VERSION "Version"

NS_ :

BS_:

BU_: IID IDC CCU Tester CCURT1 CCURT2 CCU3 CCU4 AVAS LCUFL LCUFR LCURL LCURR ZCUF ZCUL ZCUR ZCUT PADS MFS VDC ITS BCB IPS DCDC PCU EOP DCU BMC SRS EPS RBM IBCS AMP WHUD ADC RADARRR RADARRL RADARFR RADARFL RPC IFC RADARFRT RADARR HDMAP SBM WCM ETC TBOX DSM FLPDM FRPDM RLPDM RRPDM

BO_ 475 IDC_4: 64 IDC
 SG_ IDC_4_Dummy7 : 31|30@0+ (1,0) [0|0] ""  CCU,CCURT2
 SG_ IDC_4_Dummy6 : 64|25@0+ (1,0) [0|0] ""  CCU,CCURT2
 SG_ IDC_4_Dummy5 : 101|22@0+ (1,0) [0|0] ""  CCU,CCURT2
 SG_ IDC_4_Dummy4 : 127|64@0+ (1,0) [0|0] ""  CCU,CCURT2
 SG_ IDC_4_Dummy3 : 303|48@0+ (1,0) [0|0] ""  CCU,CCURT2
 SG_ IDC_4_Dummy2 : 415|38@0+ (1,0) [0|0] ""  CCU,CCURT2
 SG_ IDC_4_Dummy1 : 455|64@0+ (1,0) [0|0] ""  CCU,CCURT2
 SG_ Reserved1 : 441|2@0+ (1,0) [0|3] ""  CCU,CCURT2
 SG_ ACU_FRSeatOttomanExtentPosCtlReq : 295|8@0+ (0.5,0) [0|255] ""  CCU,CCURT2
 SG_ ACU_FRSeatOttomanAnglePosCtlReq : 287|8@0+ (0.5,0) [0|255] ""  CCU,CCURT2
 SG_ ACU_FLSeatOttomanExtentPosCtlReq : 279|8@0+ (0.5,0) [0|255] ""  CCU,CCURT2
 SG_ ACU_FLSeatOttomanAnglePosCtlReq : 271|8@0+ (0.5,0) [0|255] ""  CCU,CCURT2
 SG_ IDC_4_Counter : 23|8@0+ (1,0) [0|255] ""  CCU,CCURT2
 SG_ IDC_4_CRC : 7|16@0+ (1,0) [0|65535] ""  CCU,CCURT2
 SG_ ACU_HVACFR_OffOnBtnSt : 49|1@0+ (1,0) [0|1] ""  CCU,CCURT2
 SG_ ACU_HVACFR_AutoModeBtnSt : 48|1@0+ (1,0) [0|1] ""  CCU,CCURT2
 SG_ ACU_HVACFR_ModeBtnSt : 63|1@0+ (1,0) [0|1] ""  CCU,CCURT2
 SG_ ACU_HVACF_FDefrostBtnSt : 62|1@0+ (1,0) [0|1] ""  CCU,CCURT2
 SG_ ACU_HVACF_RDefrostBtnSt : 61|1@0+ (1,0) [0|1] ""  CCU,CCURT2
 SG_ ACU_HVACF_DualSyncBtnSt : 60|1@0+ (1,0) [0|1] ""  CCU,CCURT2
 SG_ ACU_HVACF_IonBtnSt : 59|1@0+ (1,0) [0|1] ""  CCU,CCURT2
 SG_ ACU_HVACFR_FanIncBtnSt : 58|1@0+ (1,0) [0|1] ""  CCU,CCURT2
 SG_ ACU_HVACFR_FanDecBtnSt : 57|1@0+ (1,0) [0|1] ""  CCU,CCURT2
 SG_ ACU_HVACF_CirBtnSt : 56|1@0+ (1,0) [0|1] ""  CCU,CCURT2
 SG_ ACU_HVACF_ACBtnSt : 71|1@0+ (1,0) [0|1] ""  CCU,CCURT2
 SG_ ACU_HVACF_ACMaxBtnSt : 70|1@0+ (1,0) [0|1] ""  CCU,CCURT2
 SG_ ACU_HVACF_FLTempIncBtnSt : 69|1@0+ (1,0) [0|1] ""  CCU,CCURT2
 SG_ ACU_HVACF_FLTempDecBtnSt : 68|1@0+ (1,0) [0|1] ""  CCU,CCURT2
 SG_ ACU_HVACF_FRTempIncBtnSt : 67|1@0+ (1,0) [0|1] ""  CCU,CCURT2
 SG_ ACU_HVACF_FRTempDecBtnSt : 66|1@0+ (1,0) [0|1] ""  CCU,CCURT2
 SG_ ACU_HVACF_ECOBtnSt : 65|1@0+ (1,0) [0|1] ""  CCU,CCURT2
 SG_ ACU_HVAC_RearOnOffBtnSt : 103|1@0+ (1,0) [0|1] ""  CCU,CCURT2
 SG_ ACU_HVAC_RearAutoModeBtnSt : 102|1@0+ (1,0) [0|1] ""  CCU,CCURT2
 SG_ ACU_LeftMirrorXPosCtlReq : 191|8@0+ (1,0) [0|255] "%"  CCU,CCURT2,ZCUL
 SG_ ACU_LeftMirrorYPosCtlReq : 199|8@0+ (1,0) [0|255] "%"  CCU,CCURT2,ZCUL
 SG_ ACU_RightMirrorXPosCtlReq : 207|8@0+ (1,0) [0|255] "%"  CCU,CCURT2,ZCUL
 SG_ ACU_RightMirrorYPosCtlReq : 215|8@0+ (1,0) [0|255] "%"  CCU,CCURT2,ZCUL
 SG_ ACU_FLSeatSlidePosCtlReq : 223|8@0+ (0.5,0) [0|255] ""  CCU,CCURT2
 SG_ ACU_FLSeatHeightPosCtlReq : 231|8@0+ (0.5,0) [0|255] ""  CCU,CCURT2
 SG_ ACU_FLSeatBackrestPosCtlReq : 239|8@0+ (0.5,0) [0|255] ""  CCU,CCURT2
 SG_ ACU_FLSeatTiltPosCtlReq : 247|8@0+ (0.5,0) [0|255] ""  CCU,CCURT2
 SG_ ACU_SteeringAnglePosCtlReq : 255|8@0+ (0.5,0) [0|255] ""  CCU,CCURT2,ZCUL
 SG_ ACU_SteeringExtentPosCtlReq : 263|8@0+ (0.5,0) [0|255] ""  CCU,CCURT2,ZCUL
 SG_ ACU_FRSeatSlidePosCtlReq : 351|8@0+ (0.5,0) [0|255] ""  CCU,CCURT2
 SG_ ACU_FRSeatHeightPosCtlReq : 359|8@0+ (0.5,0) [0|255] ""  CCU,CCURT2
 SG_ ACU_FRSeatBackrestPosCtlReq : 367|8@0+ (0.5,0) [0|255] ""  CCU,CCURT2
 SG_ ACU_FRSeatTiltPosCtlReq : 375|8@0+ (0.5,0) [0|255] ""  CCU,CCURT2
 SG_ ACU_FLSeatCushionPosCtlReq : 383|8@0+ (0.5,0) [0|255] ""  CCU,CCURT2
 SG_ ACU_FRSeatCushionPosCtlReq : 391|8@0+ (0.5,0) [0|255] ""  CCU,CCURT2
 SG_ ACU_FLSeatOttomanPosCtlReq : 399|8@0+ (0.5,0) [0|255] ""  CCU,CCURT2
 SG_ ACU_FRSeatOttomanPosCtlReq : 407|8@0+ (0.5,0) [0|255] ""  CCU,CCURT2

BO_ 967 IDC_DMS_1: 64 IDC
 SG_ IDC_DMS_1_Dummy13 : 264|4@0+ (1,0) [0|15] "" Vector__XXX
 SG_ IDC_DMS_1_Dummy12 : 63|3@0+ (1,0) [0|7] ""  CCU
 SG_ DMS_YawnSt : 276|2@0+ (1,0) [0|3] ""  ADC,CCU
 SG_ IDC_DMS_1_Dummy11 : 137|2@0+ (1,0) [0|3] ""  CCU
 SG_ IDC_DMS_1_Dummy10 : 25|2@0+ (1,0) [0|0] ""  CCU
 SG_ IDC_DMS_1_Dummy9 : 34|1@0+ (1,0) [0|0] ""  CCU
 SG_ DMS_FaceID : 58|4@0+ (1,0) [0|15] ""  CCU
 SG_ IDC_DMS_1_Dummy6 : 128|1@0+ (1,0) [0|0] ""  CCU
 SG_ IDC_DMS_1_Dummy5 : 188|1@0+ (1,0) [0|0] ""  CCU
 SG_ IDC_DMS_1_Dummy4 : 274|43@0+ (1,0) [0|8796093022207] ""  CCU
 SG_ IDC_DMS_1_Dummy3 : 327|64@0+ (1,0) [0|0] ""  CCU
 SG_ IDC_DMS_1_Dummy2 : 391|64@0+ (1,0) [0|0] ""  CCU
 SG_ IDC_DMS_1_Dummy1 : 455|64@0+ (1,0) [0|0] ""  CCU
 SG_ DMS_SeatBeltRigntrearStatus : 269|1@0+ (1,0) [0|1] ""  CCU
 SG_ DMS_SeatBeltMidrearStatus : 270|1@0+ (1,0) [0|1] ""  CCU
 SG_ DMS_SeatBeltLeftrearStatus : 271|1@0+ (1,0) [0|1] ""  CCU
 SG_ DMS_SeatBeltCodriverStatus : 256|1@0+ (1,0) [0|1] ""  CCU
 SG_ DMS_SeatBeltDriverStatus : 257|1@0+ (1,0) [0|1] ""  CCU
 SG_ DMS_MidrearChild : 258|1@0+ (1,0) [0|1] ""  CCU
 SG_ DMS_RigntrearChild : 259|1@0+ (1,0) [0|1] ""  CCU
 SG_ DMS_LeftrearChild : 260|1@0+ (1,0) [0|1] ""  CCU
 SG_ DMS_CodriverChild : 261|1@0+ (1,0) [0|1] ""  CCU
 SG_ DMS_MidrearThumbleftgestures : 262|1@0+ (1,0) [0|1] ""  CCU
 SG_ DMS_RigntrearThumbleftgestures : 263|1@0+ (1,0) [0|1] ""  CCU
 SG_ DMS_LeftrearThumbleftgestures : 248|1@0+ (1,0) [0|1] ""  CCU
 SG_ DMS_CodriverThumbleftgestures : 249|1@0+ (1,0) [0|1] ""  CCU
 SG_ DMS_DriverThumbleftgestures : 250|1@0+ (1,0) [0|1] ""  CCU
 SG_ DMS_MidrearThumbrightgestures : 251|1@0+ (1,0) [0|1] ""  CCU
 SG_ DMS_RigntrearThumbrightgestures : 252|1@0+ (1,0) [0|1] ""  CCU
 SG_ DMS_LeftrearThumbrightgestures : 253|1@0+ (1,0) [0|1] ""  CCU
 SG_ DMS_CodriverThumbrightgestures : 254|1@0+ (1,0) [0|1] ""  CCU
 SG_ DMS_DriverThumbrightgestures : 255|1@0+ (1,0) [0|1] ""  CCU
 SG_ DMS_MidrearThumbdowngestures : 240|1@0+ (1,0) [0|1] ""  CCU
 SG_ DMS_RigntrearThumbdowngestures : 241|1@0+ (1,0) [0|1] ""  CCU
 SG_ DMS_LeftrearThumbdowngestures : 242|1@0+ (1,0) [0|1] ""  CCU
 SG_ DMS_CodriverThumbdowngestures : 243|1@0+ (1,0) [0|1] ""  CCU
 SG_ DMS_DriverThumbdowngestures : 244|1@0+ (1,0) [0|1] ""  CCU
 SG_ DMS_MidrearThumbupgestures : 245|1@0+ (1,0) [0|1] ""  CCU
 SG_ DMS_RigntrearThumbupgestures : 246|1@0+ (1,0) [0|1] ""  CCU
 SG_ DMS_LeftrearThumbupgestures : 247|1@0+ (1,0) [0|1] ""  CCU
 SG_ DMS_CodriverThumbupgestures : 232|1@0+ (1,0) [0|1] ""  CCU
 SG_ DMS_DriverThumbupgestures : 233|1@0+ (1,0) [0|1] ""  CCU
 SG_ DMS_MidrearPapergesture : 234|1@0+ (1,0) [0|1] ""  CCU
 SG_ DMS_RigntrearPapergesture : 235|1@0+ (1,0) [0|1] ""  CCU
 SG_ DMS_LeftrearPapergesture : 236|1@0+ (1,0) [0|1] ""  CCU
 SG_ DMS_CodriverPapergesture : 237|1@0+ (1,0) [0|1] ""  CCU
 SG_ DMS_DriverPapergesture : 238|1@0+ (1,0) [0|1] ""  CCU
 SG_ DMS_MidrearScissorsgesture : 239|1@0+ (1,0) [0|1] ""  CCU
 SG_ DMS_RigntrearScissorsgesture : 224|1@0+ (1,0) [0|1] ""  CCU
 SG_ DMS_LeftrearScissorsgesture : 225|1@0+ (1,0) [0|1] ""  CCU
 SG_ DMS_CodriverScissorsgesture : 226|1@0+ (1,0) [0|1] ""  CCU
 SG_ DMS_DriverScissorsgesture : 227|1@0+ (1,0) [0|1] ""  CCU
 SG_ DMS_MidrearRockgesture : 228|1@0+ (1,0) [0|1] ""  CCU
 SG_ DMS_RigntrearRockgesture : 229|1@0+ (1,0) [0|1] ""  CCU
 SG_ DMS_LeftrearRockgesture : 230|1@0+ (1,0) [0|1] ""  CCU
 SG_ DMS_CodriverRockgesture : 231|1@0+ (1,0) [0|1] ""  CCU
 SG_ DMS_DriverRockgesture : 216|1@0+ (1,0) [0|1] ""  CCU
 SG_ DMS_MidrearWavepalmtotheleft : 217|1@0+ (1,0) [0|1] ""  CCU
 SG_ DMS_RigntrearWavepalmtotheleft : 218|1@0+ (1,0) [0|1] ""  CCU
 SG_ DMS_LeftrearWavepalmtotheleft : 219|1@0+ (1,0) [0|1] ""  CCU
 SG_ DMS_CodriverWavepalmtotheleft : 220|1@0+ (1,0) [0|1] ""  CCU
 SG_ DMS_DriverWavepalmtotheleft : 221|1@0+ (1,0) [0|1] ""  CCU
 SG_ DMS_MidrearWavepalmtotheright : 222|1@0+ (1,0) [0|1] ""  CCU
 SG_ DMS_RigntrearWavepalmtotheright : 223|1@0+ (1,0) [0|1] ""  CCU
 SG_ DMS_LeftrearWavepalmtotheright : 208|1@0+ (1,0) [0|1] ""  CCU
 SG_ DMS_CodriverWavepalmtotheright : 209|1@0+ (1,0) [0|1] ""  CCU
 SG_ DMS_DriverWavepalmtotheright : 210|1@0+ (1,0) [0|1] ""  CCU
 SG_ DMS_MidrearDownwardwave : 211|1@0+ (1,0) [0|1] ""  CCU
 SG_ DMS_RigntrearDownwardwave : 212|1@0+ (1,0) [0|1] ""  CCU
 SG_ DMS_LeftrearDownwardwave : 213|1@0+ (1,0) [0|1] ""  CCU
 SG_ DMS_CodriverDownwardwave : 214|1@0+ (1,0) [0|1] ""  CCU
 SG_ DMS_DriverDownwardwave : 215|1@0+ (1,0) [0|1] ""  CCU
 SG_ DMS_MidrearUpwardwave : 200|1@0+ (1,0) [0|1] ""  CCU
 SG_ DMS_RigntrearUpwardwave : 201|1@0+ (1,0) [0|1] ""  CCU
 SG_ DMS_LeftrearUpwardwave : 202|1@0+ (1,0) [0|1] ""  CCU
 SG_ DMS_CodriverUpwardwave : 203|1@0+ (1,0) [0|1] ""  CCU
 SG_ DMS_DriverUpwardwave : 204|1@0+ (1,0) [0|1] ""  CCU
 SG_ DMS_MidrearForefingercircleleft : 205|1@0+ (1,0) [0|1] ""  CCU
 SG_ DMS_RigntrearForefingercirclelef : 206|1@0+ (1,0) [0|1] ""  CCU
 SG_ DMS_LeftrearForefingercircleleft : 207|1@0+ (1,0) [0|1] ""  CCU
 SG_ DMS_CodriverForefingercircleleft : 192|1@0+ (1,0) [0|1] ""  CCU
 SG_ DMS_DriverForefingercircleleft : 193|1@0+ (1,0) [0|1] ""  CCU
 SG_ DMS_MidrearForefingercircleright : 194|1@0+ (1,0) [0|1] ""  CCU
 SG_ DMS_RigntrearForefingercirclerig : 195|1@0+ (1,0) [0|1] ""  CCU
 SG_ DMS_LeftrearForefingercirclerigh : 196|1@0+ (1,0) [0|1] ""  CCU
 SG_ DMS_CodriverForefingercirclerigh : 197|1@0+ (1,0) [0|1] ""  CCU
 SG_ DMS_DriverForefingercircleright : 198|1@0+ (1,0) [0|1] ""  CCU
 SG_ DMS_MidrearOKgesture : 199|1@0+ (1,0) [0|1] ""  CCU
 SG_ DMS_RigntrearOKgesture : 184|1@0+ (1,0) [0|1] ""  CCU
 SG_ DMS_LeftrearOKgesture : 185|1@0+ (1,0) [0|1] ""  CCU
 SG_ DMS_CodriverOKgesture : 186|1@0+ (1,0) [0|1] ""  CCU
 SG_ DMS_DriverOKgesture : 187|1@0+ (1,0) [0|1] ""  CCU
 SG_ DMS_MidrearHandheartgesture : 189|1@0+ (1,0) [0|1] ""  CCU
 SG_ DMS_RigntrearHandheartgesture : 190|1@0+ (1,0) [0|1] ""  CCU
 SG_ DMS_LeftrearHandheartgesture : 191|1@0+ (1,0) [0|1] ""  CCU
 SG_ DMS_CodriverHandheartgesture : 176|1@0+ (1,0) [0|1] ""  CCU
 SG_ DMS_DriverHandheartgesture : 177|1@0+ (1,0) [0|1] ""  CCU
 SG_ DMS_CarOwner : 178|1@0+ (1,0) [0|1] ""  CCU
 SG_ DMS_PersonGender : 180|2@0+ (1,0) [0|3] ""  CCU
 SG_ DMS_SeatMidrearSt : 181|1@0+ (1,0) [0|1] ""  CCU
 SG_ DMS_SeatRigntrearSt : 182|1@0+ (1,0) [0|1] ""  CCU
 SG_ DMS_SeatLeftrearSt : 183|1@0+ (1,0) [0|1] ""  CCU
 SG_ DMS_PersonAge : 175|8@0+ (0.392,0) [0|99] ""  CCU
 SG_ DMS_SeatMidmiddleSt : 160|1@0+ (1,0) [0|1] ""  CCU
 SG_ DMS_SeatCodriverSt : 161|1@0+ (1,0) [0|1] ""  CCU
 SG_ DMS_PersonCount : 165|4@0+ (1,0) [0|7] ""  CCU
 SG_ DMS_DriverDistractionSt : 167|2@0+ (1,0) [0|3] ""  CCU
 SG_ DMS_SeatDriverSt : 152|1@0+ (1,0) [0|1] ""  CCU
 SG_ DMS_DriverInterestsRegion : 156|4@0+ (1,0) [0|15] ""  CCU
 SG_ DMS_DriverFatigueSt : 159|3@0+ (1,0) [0|3] ""  CCU
 SG_ DMS_FaceIDFailCause : 146|3@0+ (1,0) [0|7] ""  CCU
 SG_ DMS_FaceIDWelcomeMode : 147|1@0+ (1,0) [0|1] ""  CCU
 SG_ DMS_DriverFaceID : 151|4@0+ (1,0) [0|15] ""  CCU
 SG_ DMS_MidrearHealthSt : 140|3@0+ (1,0) [0|7] ""  CCU
 SG_ DMS_RigntrearHealthSt : 143|3@0+ (1,0) [0|7] ""  CCU
 SG_ DMS_LeftrearHealthSt : 131|3@0+ (1,0) [0|7] ""  CCU
 SG_ DMS_CodriverHealthSt : 134|3@0+ (1,0) [0|7] ""  CCU
 SG_ DMS_SeatPositionID : 121|3@0+ (1,0) [0|3] ""  CCU
 SG_ DMS_MidrearTelephoneSt : 123|2@0+ (1,0) [0|3] ""  CCU
 SG_ DMS_RigntrearTelephoneSt : 125|2@0+ (1,0) [0|3] ""  CCU
 SG_ DMS_LeftrearTelephoneSt : 127|2@0+ (1,0) [0|3] ""  CCU
 SG_ DMS_CodriverTelephoneSt : 113|2@0+ (1,0) [0|3] ""  CCU
 SG_ DMS_MidrearSmokeSt : 115|2@0+ (1,0) [0|3] ""  CCU
 SG_ DMS_RigntrearSmokeSt : 117|2@0+ (1,0) [0|3] ""  CCU
 SG_ DMS_LeftrearSmokeSt : 119|2@0+ (1,0) [0|3] ""  CCU
 SG_ DMS_MidrearExpressionSt : 107|4@0+ (1,0) [0|15] ""  CCU
 SG_ DMS_RigntrearExpressionSt : 111|4@0+ (1,0) [0|15] ""  CCU
 SG_ DMS_LeftrearExpressionSt : 99|4@0+ (1,0) [0|15] ""  CCU
 SG_ DMS_CodriverExpressionSt : 103|4@0+ (1,0) [0|15] ""  CCU
 SG_ DMS_CodriverSmokeSt : 89|2@0+ (1,0) [0|3] ""  CCU
 SG_ DMS_ObjectSt : 90|1@0+ (1,0) [0|1] ""  CCU
 SG_ DMS_PetSt : 91|1@0+ (1,0) [0|1] ""  CCU
 SG_ DMS_DistrWarnSt : 94|3@0+ (1,0) [0|7] ""  CCU
 SG_ DMS_FatigWarnSt : 81|3@0+ (1,0) [0|7] ""  CCU
 SG_ DMS_SeatLeftmiddleSt : 82|1@0+ (1,0) [0|1] ""  CCU
 SG_ DMS_SeatRightmiddleSt : 83|1@0+ (1,0) [0|1] ""  CCU
 SG_ DMS_DriverHealthSt : 86|3@0+ (1,0) [0|7] ""  CCU
 SG_ DMS_DriverTelephoneSt : 72|2@0+ (1,0) [0|3] ""  CCU
 SG_ DMS_DriverSmokeSt : 74|2@0+ (1,0) [0|3] ""  CCU
 SG_ DMS_GlassWearSt : 75|1@0+ (1,0) [0|1] ""  CCU
 SG_ DMS_MouthSt : 76|1@0+ (1,0) [0|1] ""  CCU
 SG_ DMS_RightEyeOpenSt : 78|2@0+ (1,0) [0|3] ""  CCU
 SG_ DMS_LeftEyeOpenSt : 64|2@0+ (1,0) [0|3] ""  CCU
 SG_ DMS_FaceIDDeleteResult : 66|2@0+ (1,0) [0|3] ""  CCU
 SG_ DMS_FaceIDVerifyResult : 68|2@0+ (1,0) [0|3] ""  CCU
 SG_ DMS_FaceIDRegisterResult : 70|2@0+ (1,0) [0|3] ""  CCU
 SG_ DMS_FaceIDStatus : 60|2@0+ (1,0) [0|3] ""  CCU
 SG_ DMS_DriverExpressionSt : 268|4@0+ (1,0) [0|15] ""  CCU
 SG_ DMS_1_Checksum : 7|16@0+ (1,0) [0|65535] ""  CCU,ADC
 SG_ DMS_1_MsgCounter : 23|8@0+ (1,0) [0|255] ""  CCU,ADC
 SG_ DMS_SysErrSt : 31|3@0+ (1,0) [0|7] ""  CCU,ADC
 SG_ DMS_DrvrDetSts : 28|3@0+ (1,0) [0|7] ""  CCU,ADC
 SG_ DMS_InterestsRegion : 39|5@0+ (1,0) [0|31] ""  CCU,ADC
 SG_ DMS_L3DriverDistractionSt : 33|6@0+ (1,0) [0|63] ""  CCU,ADC
 SG_ DMS_L3DriverFatigueSt : 43|12@0+ (1,0) [0|4095] ""  CCU,ADC

BO_ 1963 IDC_Diag_Tx: 64 IDC
 SG_ IDC_Diag_Response : 7|64@0+ (1,0) [0|0] ""  Tester

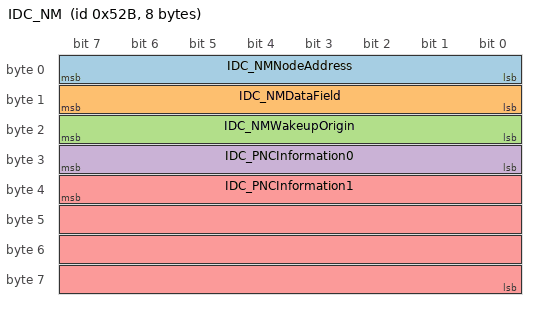
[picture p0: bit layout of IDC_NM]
BO_ 1323 IDC_NM: 8 IDC
 SG_ IDC_NMNodeAddress : 7|8@0+ (1,0) [0|255] ""  CCU,CCURT2
 SG_ IDC_NMDataField : 15|8@0+ (1,0) [0|0] ""  CCU,CCURT2
 SG_ IDC_NMWakeupOrigin : 23|8@0+ (1,0) [0|255] ""  CCU,CCURT2
 SG_ IDC_PNCInformation0 : 31|8@0+ (1,0) [0|255] ""  CCU,CCURT2
 SG_ IDC_PNCInformation1 : 39|32@0+ (1,0) [0|0] ""  CCU,CCURT2

BO_ 169 IDC_SecReq: 16 IDC
 SG_ IDC_SecReq : 7|128@0+ (1,0) [0|255] ""  CCU

BO_ 157 IDC_IMMO: 1 IDC
 SG_ IDC_IMMO : 7|8@0+ (1,0) [0|255] "" Vector__XXX

BO_ 122 IDC_SECKEY: 1 IDC
 SG_ IDC_SEC_KEY_Defaultencoding : 7|8@0+ (1,0) [0|255] ""  CCU,CCURT1

BO_ 624 CCU_ZCUR_1: 64 CCU
 SG_ KAE_KeyReminderWarning : 40|1@0+ (1,0) [0|1] ""  IDC
 SG_ KAE_DoorLockWarning : 55|2@0+ (1,0) [0|3] ""  IDC
 SG_ KAE_StartAuthFailWarning : 53|1@0+ (1,0) [0|1] ""  IDC
 SG_ KAE_KeyBattaryLowWarning : 52|1@0+ (1,0) [0|1] ""  IDC
 SG_ KAE_IDOutWarning : 50|1@0+ (1,0) [0|1] ""  IDC
 SG_ ZCUR_1_FreshnessValue : 455|16@0+ (1,0) [0|255] ""  IDC
 SG_ ZCUR_1_MAC_Check : 471|48@0+ (1,0) [0|255] ""  IDC

BO_ 777 CCU_ZCUR_4: 64 CCU
 SG_ SSW_FROttomanExtentCurrentOpeSt : 443|2@0+ (1,0) [0|3] ""  IDC
 SG_ SSW_FROttomanExtentCurrentPst : 435|8@0+ (0.5,0) [0|100] ""  IDC
 SG_ SSW_FROttomanAngleCurrentOpeSt : 437|2@0+ (1,0) [0|3] ""  IDC
 SG_ SSW_FROttomanAngleCurrentPst : 429|8@0+ (0.5,0) [0|100] ""  IDC
 SG_ SSW_FRSeatSlideCurrentPst : 87|8@0+ (0.5,0) [0|100] ""  IDC
 SG_ SSW_FRSeatHeightCurrentPst : 95|8@0+ (0.5,0) [0|100] ""  IDC
 SG_ SSW_FRSeatBackrestCurrentPst : 151|8@0+ (0.5,0) [0|100] ""  IDC
 SG_ SSW_FRSeatTiltCurrentPst : 175|8@0+ (0.5,0) [0|100] ""  IDC
 SG_ SSW_FRSeatCushionCurrentPst : 183|8@0+ (0.5,0) [0|100] ""  IDC
 SG_ SSW_FRSeatOttomanCurrentPst : 191|8@0+ (0.5,0) [0|100] ""  IDC
 SG_ SSW_FRSeatHeatingSt : 167|3@0+ (1,0) [0|7] ""  IDC
 SG_ SSW_FRSeatVentSt : 164|3@0+ (1,0) [0|7] ""  IDC
 SG_ EL_MRTurnLightSt : 325|2@0+ (1,0) [0|3] ""  SRS,IDC,TBOX
 SG_ EL_MRTurnLightFaultSt : 323|1@0+ (1,0) [0|1] ""  SRS,IDC,ADC

BO_ 786 CCU_ZCUR_7: 64 CCU
 SG_ SSW_FRMassageForceSt : 7|4@0+ (1,0) [0|15] "" Vector__XXX
 SG_ SSW_FRMassageModeSt : 439|4@0+ (1,0) [0|15] ""  IDC
 SG_ SSW_FRSPAMode : 425|2@0+ (1,0) [0|3] ""  IDC
 SG_ SSW_FRLumbarModeSt : 428|3@0+ (1,0) [0|7] ""  IDC
 SG_ SSW_FRMassageSt : 430|2@0+ (1,0) [0|3] ""  IDC
 SG_ AQM_CO2DataVD : 423|1@0+ (1,0) [0|1] ""  IDC
 SG_ AQM_CO2Data : 407|16@0+ (1,0) [0|65535] ""  IDC
 SG_ AQM_PM25Data : 215|10@0+ (1,0) [0|999] "ug/m3"  IDC
 SG_ AQM_PM10Data : 221|10@0+ (1,0) [0|999] "ug/m3"  IDC
 SG_ AQM_PM25DataVD : 232|1@0+ (1,0) [0|1] ""  IDC
 SG_ AQM_PM10DataVD : 247|1@0+ (1,0) [0|1] ""  IDC
 SG_ AQM_PM25ValueOutVD : 290|1@0+ (1,0) [0|1] ""  IDC
 SG_ AQM_PM25ValueOut : 289|10@0+ (1,0) [0|999] "Î¼g/mÂ³"  IDC

BO_ 342 CCU_ZCUR_8: 64 CCU
 SG_ KAE_KUID : 83|4@0+ (1,0) [0|15] ""  IDC
 SG_ KAE_RKEChargeGunUnlockReq : 103|1@0+ (1,0) [0|1] ""  IDC

BO_ 632 CCU_ZCUL_2: 64 CCU
 SG_ SSW_FLLumbarOpeSt : 139|3@0+ (1,0) [0|7] ""  IDC
 SG_ SSW_FLOttomanExtentCurrentOpeSt : 373|2@0+ (1,0) [0|3] ""  IDC
 SG_ SSW_FLOttomanExtentCurrentPst : 365|8@0+ (0.5,0) [0|100] ""  IDC
 SG_ SSW_FLOttomanAngleCurrentOpeSt : 367|2@0+ (1,0) [0|3] ""  IDC
 SG_ SSW_FLOttomanAngleCurrentPst : 359|8@0+ (0.5,0) [0|100] ""  IDC
 SG_ SSW_FLSeatVentSt : 164|3@0+ (1,0) [0|7] ""  ZCUR,IDC,SBM
 SG_ SSW_FLSeatHeatingSt : 167|3@0+ (1,0) [0|7] ""  ZCUR,IDC,SBM
 SG_ SSW_FLSeatSlideCurrentPst : 47|8@0+ (0.5,0) [0|100] "%"  IDC
 SG_ SSW_FLSeatHeightCurrentPst : 55|8@0+ (0.5,0) [0|100] "%"  IDC
 SG_ SSW_FLSeatBackrestCurrentPst : 63|8@0+ (0.5,0) [0|100] "%"  IDC
 SG_ SSW_FLSeatTiltCurrentPst : 79|8@0+ (0.5,0) [0|100] "%"  IDC
 SG_ SSW_SteeringAngleCurrentPst : 87|8@0+ (0.5,0) [0|100] "%"  IDC
 SG_ SSW_SteeringExtentCurrentPst : 95|8@0+ (0.5,0) [0|100] "%"  IDC
 SG_ SSW_FLSeatCushionCurrentPst : 103|8@0+ (0.5,0) [0|100] "%"  IDC
 SG_ SSW_FLSeatOttomanCurrentPst : 127|8@0+ (0.5,0) [0|100] "%"  IDC
 SG_ SSW_SteerHeatSt : 135|1@0+ (1,0) [0|1] ""  IDC

BO_ 776 CCU_ZCUL_3: 64 CCU
 SG_ EL_MLTurnLightSt : 35|2@0+ (1,0) [0|3] ""  IDC
 SG_ EL_MLTurnLightFaultSt : 33|1@0+ (1,0) [0|1] ""  SRS,IDC,ADC
 SG_ UINM_HazardLightSwSt : 39|1@0+ (1,0) [0|1] ""  SRS,IDC,ADC

BO_ 791 CCU_ZCUF_2: 64 CCU
 SG_ WW_FWPMotorSt : 27|3@0+ (1,0) [0|7] ""  IBCS,IDC
 SG_ WW_FWSHLevelWarning : 24|1@0+ (1,0) [0|1] ""  IDC
 SG_ EL_FLPositionLightSt : 71|1@0+ (1,0) [0|1] ""  IDC
 SG_ EL_FLPositionLightFaultSt : 70|1@0+ (1,0) [0|1] ""  IDC,ADC
 SG_ EL_FRPositionLightSt : 69|1@0+ (1,0) [0|1] ""  IDC
 SG_ EL_FRPositionLightFaultSt : 68|1@0+ (1,0) [0|1] ""  IDC,ADC
 SG_ EL_LeftLowBeamSt : 67|1@0+ (1,0) [0|1] ""  IDC
 SG_ EL_LeftLowBeamFaultSt : 66|1@0+ (1,0) [0|1] ""  IDC,ADC
 SG_ EL_RightLowBeamSt : 65|1@0+ (1,0) [0|1] ""  IDC
 SG_ EL_RightLowBeamFaultSt : 64|1@0+ (1,0) [0|1] ""  IDC,ADC
 SG_ EL_LeftHighBeamSt : 79|1@0+ (1,0) [0|1] ""  IDC
 SG_ EL_LeftHighBeamFaultSt : 78|1@0+ (1,0) [0|1] ""  IDC,ADC
 SG_ EL_RightHighBeamSt : 77|1@0+ (1,0) [0|1] ""  IDC
 SG_ EL_RightHighBeamFaultSt : 76|1@0+ (1,0) [0|1] ""  IDC,ADC
 SG_ EL_FLFogLightSt : 75|1@0+ (1,0) [0|1] ""  IDC
 SG_ EL_FLFogLightFaultSt : 74|1@0+ (1,0) [0|1] ""  IDC,ADC
 SG_ EL_FRFogLightSt : 73|1@0+ (1,0) [0|1] ""  IDC
 SG_ EL_FRFogLightFaultSt : 72|1@0+ (1,0) [0|1] ""  IDC,ADC
 SG_ EL_LeftDRLFaultSt : 86|1@0+ (1,0) [0|1] ""  IDC,ADC
 SG_ EL_RightDRLFaultSt : 84|1@0+ (1,0) [0|1] ""  IDC,ADC
 SG_ EL_FLTurnLightSt : 95|2@0+ (1,0) [0|3] ""  SRS,IDC,TBOX
 SG_ EL_FLTurnLightFaultSt : 93|1@0+ (1,0) [0|1] ""  SRS,IDC,ADC
 SG_ EL_FRTurnLightSt : 92|2@0+ (1,0) [0|3] ""  SRS,IDC,TBOX
 SG_ EL_FRTurnLightFaultSt : 90|1@0+ (1,0) [0|1] ""  SRS,IDC,ADC
 SG_ EBSF_SOC : 263|8@0+ (1,0) [0|100] "%"  ZCUR,BMC,SRS,IDC,SBM,TBOX
 SG_ EBSF_SOC_STATE : 311|2@0+ (1,0) [0|3] ""  ZCUR,BMC,SRS,IDC,SBM

BO_ 792 CCU_ZCUT_2: 64 CCU
 SG_ EL_CHMSLSt : 107|1@0+ (1,0) [0|1] ""  ADC,IDC
 SG_ EL_SideBrkLightSt : 109|1@0+ (1,0) [0|1] ""  ADC,IDC
 SG_ EL_ReverseLightSt : 111|1@0+ (1,0) [0|1] ""  ADC,IDC
 SG_ UMM_SecondMIDSeatSt : 35|2@0+ (1,0) [0|3] ""  IFC,IDC,ADC
 SG_ UMM_SecondRHSeatSt : 37|2@0+ (1,0) [0|3] ""  IFC,IDC,ADC
 SG_ UMM_SecondLHSeatSt : 39|2@0+ (1,0) [0|3] ""  IFC,IDC,ADC
 SG_ PLG_SetPosition : 79|8@0+ (0.5,0) [0|100] ""  IDC
 SG_ LCK_PowerFillerCapAngle : 103|8@0+ (1,0) [0|255] "deg"  IDC
 SG_ EL_ReverseLightFaultSt : 110|1@0+ (1,0) [0|1] ""  IDC
 SG_ EL_SideBrkLightFaultSt : 108|1@0+ (1,0) [0|1] ""  IDC
 SG_ EL_CHMSLFaultSt : 106|1@0+ (1,0) [0|1] ""  IDC
 SG_ EL_RLPositionLightSt : 105|1@0+ (1,0) [0|1] ""  IDC
 SG_ EL_RLPositionLightFaultSt : 104|1@0+ (1,0) [0|1] ""  IDC
 SG_ EL_RRPositionLightSt : 119|1@0+ (1,0) [0|1] ""  IDC
 SG_ EL_RRPositionLightFaultSt : 118|1@0+ (1,0) [0|1] ""  IDC
 SG_ EL_RearFogLightSt : 117|1@0+ (1,0) [0|1] ""  IDC
 SG_ EL_RearFogLightFaultSt : 116|1@0+ (1,0) [0|1] ""  IDC
 SG_ EL_RLTurnLightSt : 113|2@0+ (1,0) [0|3] ""  SRS,IDC,TBOX
 SG_ EL_RLTurnLightFaultSt : 127|1@0+ (1,0) [0|1] ""  SRS,IDC
 SG_ EL_RRTurnLightSt : 126|2@0+ (1,0) [0|3] ""  SRS,IDC,TBOX
 SG_ EL_RRTurnLightFaultSt : 124|1@0+ (1,0) [0|1] ""  SRS,IDC
 SG_ LCK_RearLeftDoorLockAction : 141|2@0+ (1,0) [0|2] ""  IDC

BO_ 616 CCU_1: 64 CCU
 SG_ EEM_LvElecEgySt : 315|4@0+ (1,0) [0|15] ""  IDC
 SG_ CCU_1_Dummy12 : 39|1@0+ (1,0) [0|0] ""  ZCUT,ZCUR,ZCUL,ZCUF,WHUD,WCM,TBOX,SRS,SBM,RBM,RADARRR,RADARRL,RADARR,RADARFR,RADARFL,PCU,PADS,MFS,LCURR,LCURL,LCUFR,LCUFL,ITS,IPS,IDC,IBCS,HDMAP,ETC,EPS,EOP,DCU,DCDC,CCURT2,CCURT1,CCU4,CCU3,BMC,BCB,AVAS,AMP,ADC
 SG_ CCU_1_Dummy11 : 36|1@0+ (1,0) [0|0] ""  ZCUT,ZCUR,ZCUL,ZCUF,WHUD,WCM,TBOX,SRS,SBM,RBM,RADARRR,RADARRL,RADARR,RADARFR,RADARFL,PCU,PADS,MFS,LCURR,LCURL,LCUFR,LCUFL,ITS,IPS,IDC,IBCS,HDMAP,ETC,EPS,EOP,DCU,DCDC,CCURT2,CCURT1,CCU4,CCU3,BMC,BCB,AVAS,AMP,ADC
 SG_ CCU_1_Dummy10 : 47|20@0+ (1,0) [0|1048575] ""  EOP,IDC,ZCUT,ZCUR,ZCUL,ZCUF,WHUD,WCM,SRS,TBOX,SBM,RBM,RADARRR,RADARRL,RADARR,RADARFR,RADARFL,PCU,MFS,PADS,LCURR,LCURL,LCUFR,LCUFL,ITS,IPS,HDMAP,IBCS,ETC,EPS,DCU,DCDC,CCURT2,CCURT1,CCU4,CCU3,BMC,BCB,AVAS,AMP,ADC
 SG_ CCU_1_Dummy9 : 71|24@0+ (1,0) [0|0] ""  ADC,AMP,AVAS,BCB,BMC,CCU3,CCU4,CCURT1,CCURT2,DCDC,DCU,EOP,EPS,ETC,HDMAP,IBCS,IDC,IPS,ITS,LCUFL,LCUFR,LCURL,LCURR,MFS,PADS,PCU,RADARFL,RADARFR,RADARR,RADARRL,RADARRR,RBM,SBM,SRS,TBOX,WCM,WHUD,ZCUF,ZCUL,ZCUR,ZCUT
 SG_ CCU_1_Dummy8 : 95|64@0+ (1,0) [0|0] ""  ADC,AMP,AVAS,BCB,BMC,CCU3,CCU4,CCURT1,CCURT2,DCDC,DCU,EOP,EPS,ETC,HDMAP,IBCS,IDC,IPS,ITS,LCUFL,LCUFR,LCURL,LCURR,MFS,PADS,PCU,RADARFL,RADARFR,RADARR,RADARRL,RADARRR,RBM,SBM,SRS,TBOX,WCM,WHUD,ZCUF,ZCUL,ZCUR,ZCUT
 SG_ CCU_1_Dummy7 : 155|4@0+ (1,0) [0|0] ""  ADC,AMP,AVAS,BCB,BMC,CCU3,CCU4,CCURT1,CCURT2,DCDC,DCU,EOP,EPS,ETC,HDMAP,IBCS,IDC,IPS,ITS,LCUFL,LCUFR,LCURL,LCURR,MFS,PADS,PCU,RADARFL,RADARFR,RADARR,RADARRL,RADARRR,RBM,SBM,SRS,TBOX,WCM,WHUD,ZCUF,ZCUL,ZCUR,ZCUT
 SG_ CCU_1_Dummy6 : 165|30@0+ (1,0) [0|0] ""  ADC,AMP,AVAS,BCB,BMC,CCU3,CCU4,CCURT1,CCURT2,DCDC,DCU,EOP,EPS,ETC,HDMAP,IBCS,IDC,IPS,ITS,LCUFL,LCUFR,LCURL,LCURR,MFS,PADS,PCU,RADARFL,RADARFR,RADARR,RADARRL,RADARRR,RBM,SBM,SRS,TBOX,WCM,WHUD,ZCUF,ZCUL,ZCUR,ZCUT
 SG_ CCU_1_Dummy5 : 199|64@0+ (1,0) [0|0] ""  ADC,AMP,AVAS,BCB,BMC,CCU3,CCU4,CCURT1,CCURT2,DCDC,DCU,EOP,EPS,ETC,HDMAP,IBCS,IDC,IPS,ITS,LCUFL,LCUFR,LCURL,LCURR,MFS,PADS,PCU,RADARFL,RADARFR,RADARR,RADARRL,RADARRR,RBM,SBM,SRS,TBOX,WCM,WHUD,ZCUF,ZCUL,ZCUR,ZCUT
 SG_ CCU_1_Dummy4 : 263|60@0+ (1,0) [0|1.15292150460685E+018] ""  ITS,LCUFL,LCUFR,LCURL,LCURR,MFS,PADS,PCU,RADARFL,RADARFR,RADARR,RADARRL,RADARRR,RBM,SBM,SRS,TBOX,WCM,WHUD,ZCUF,ZCUL,ZCUR,ZCUT,IPS,IDC,IBCS,HDMAP,ETC,EPS,EOP,DCU,DCDC,CCURT2,CCURT1,CCU4,CCU3,BMC,BCB,AVAS,AMP,ADC
 SG_ CCU_1_Dummy3 : 325|10@0+ (1,0) [0|0] ""  ZCUT,ZCUR,ZCUL,ZCUF,WHUD,WCM,TBOX,SRS,SBM,RBM,RADARRR,RADARRL,RADARR,RADARFR,RADARFL,PCU,PADS,MFS,LCURR,LCURL,LCUFR,LCUFL,ITS,IPS,IDC,IBCS,HDMAP,ETC,EPS,EOP,DCU,DCDC,CCURT2,CCURT1,CCU4,CCU3,BMC,BCB,AVAS,AMP,ADC
 SG_ CCU_1_Dummy2 : 343|48@0+ (1,0) [0|0] ""  ZCUT,ZCUR,ZCUL,ZCUF,WHUD,WCM,TBOX,SRS,SBM,RBM,RADARRR,RADARRL,RADARR,RADARFR,RADARFL,PCU,PADS,MFS,LCURR,LCURL,LCUFR,LCUFL,ITS,IPS,IDC,IBCS,HDMAP,ETC,EPS,EOP,DCU,DCDC,CCURT2,CCURT1,CCU4,CCU3,BMC,BCB,AVAS,AMP,ADC
 SG_ CCU_1_Dummy1 : 391|64@0+ (1,0) [0|0] ""  CCURT1,CCU3,CCU4,EPS,AVAS,LCURL,LCUFR,LCUFL,LCURR,ZCUF,ZCUL,ZCUR,ZCUT,PADS,MFS,ITS,BCB,IPS,DCDC,PCU,EOP,DCU,BMC,AMP,WHUD,RADARRR,RADARRL,RADARFR,RADARFL,RADARR,HDMAP,SBM,WCM,ETC,SRS,RBM,IBCS,TBOX,CCURT2,IDC,ADC
 SG_ CCU_1_Counter1 : 23|8@0+ (1,0) [0|255] ""  IDC
 SG_ CCU_1_CRC1 : 7|16@0+ (1,0) [0|65535] ""  IDC
 SG_ UMM_FrontPassengerSeatSt : 57|2@0+ (1,0) [0|3] ""  SRS,IFC,IDC,ADC
 SG_ UMM_EmergencyWarning : 31|1@0+ (1,0) [0|1] ""  IDC
 SG_ UINM_BrakeSWSt : 30|1@0+ (1,0) [0|1] ""  IDC
 SG_ UMM_OpIndicationWarning : 29|3@0+ (1,0) [0|7] ""  IDC
 SG_ UMM_UsageModeSt : 26|3@0+ (1,0) [0|7] ""  CCURT1,CCU3,CCU4,AVAS,LCUFL,LCUFR,LCURL,LCURR,ZCUF,ZCUL,ZCUR,ZCUT,PADS,MFS,ITS,BCB,IPS,DCDC,PCU,EOP,DCU,BMC,SRS,EPS,RBM,IBCS,IDC,AMP,WHUD,ADC,RADARRR,RADARRL,RADARFR,RADARFL,RPC,IFC,RADARFRT,RADARR,HDMAP,SBM,WCM,ETC,TBOX
 SG_ UINM_BrakeSWNCSt : 38|1@0+ (1,0) [0|1] ""  IDC
 SG_ UINM_BrakeSWNOSt : 37|1@0+ (1,0) [0|1] ""  IDC
 SG_ UMM_ReadyForbidWarning : 35|1@0+ (1,0) [0|1] ""  IDC
 SG_ UMM_PowerKeepMode : 34|1@0+ (1,0) [0|1] ""  ZCUR,MFS,IDC
 SG_ UMM_PowerOffEnable : 33|1@0+ (1,0) [0|1] ""  MFS,IDC
 SG_ UMM_PowerKeepEnable : 32|1@0+ (1,0) [0|1] ""  MFS,IDC
 SG_ UMM_DriverSeatSt : 59|2@0+ (1,0) [0|3] ""  SRS,IDC,ADC,IFC
 SG_ VMM_VehModeSt : 159|4@0+ (1,0) [0|15] ""  AVAS,LCUFL,LCUFR,LCURL,LCURR,ZCUF,ZCUL,ZCUR,ZCUT,PADS,MFS,ITS,BCB,IPS,DCDC,PCU,EOP,DCU,BMC,SRS,RBM,IBCS,IDC,AMP,WHUD,ADC,RADARRR,RADARRL,RADARFR,RADARFL,RPC,IFC,RADARFRT,RADARR,HDMAP,SBM,WCM,ETC,TBOX
 SG_ VMM_OTAModeSt : 167|2@0+ (1,0) [0|3] ""  AVAS,LCUFL,LCUFR,LCURL,LCURR,ZCUF,ZCUL,ZCUR,ZCUT,PADS,MFS,ITS,BCB,IPS,DCDC,PCU,EOP,DCU,BMC,SRS,RBM,IBCS,IDC,AMP,WHUD,ADC,RADARRR,RADARRL,RADARFR,RADARFL,RPC,IFC,RADARFRT,RADARR,HDMAP,SBM,WCM,ETC,TBOX
 SG_ IPDS_EnablePowerSup : 327|2@0+ (1,0) [0|3] ""  SRS,RBM,IBCS,IDC,TBOX
 SG_ EEM_LdCtlLv : 331|3@0+ (1,0) [0|7] ""  CCURT2,IDC
 SG_ EEM_LdCtlSt : 328|1@0+ (1,0) [0|1] ""  CCURT2,IDC
 SG_ CCU_1_FreshnessValue : 455|16@0+ (1,0) [0|255] ""  IDC,ADC
 SG_ CCU_1_MAC_Check : 471|48@0+ (1,0) [0|255] ""  IDC,ADC

BO_ 816 CCU_2: 64 CCU
 SG_ AQM_FreshPopReq : 20|1@0+ (1,0) [0|1] ""  IDC,ZCUR
 SG_ AQM_CO2CleanReq : 21|1@0+ (1,0) [0|1] ""  IDC,ZCUR
 SG_ HVAC_InCarAutoVentilationSt : 25|1@0+ (1,0) [0|1] ""  IDC
 SG_ HVAC_RearDefrostSt : 31|1@0+ (1,0) [0|1] ""  ZCUL,ZCUR,ZCUT,IDC,ADC,TBOX
 SG_ HVAC_ACSt : 30|1@0+ (1,0) [0|1] ""  CCURT1,ZCUL,ZCUR,IDC,SBM,TBOX
 SG_ HVAC_ACmaxSt : 29|1@0+ (1,0) [0|1] ""  ZCUL,ZCUR,IDC,TBOX
 SG_ HVAC_AutoDefCfgSt : 28|2@0+ (1,0) [0|3] ""  IDC
 SG_ HVAC_TimedVentilationSt : 26|1@0+ (1,0) [0|1] ""  IDC
 SG_ HVAC_DualSyncSt : 39|1@0+ (1,0) [0|1] ""  ZCUL,ZCUR,IDC,TBOX
 SG_ HVAC_AutoSt : 38|1@0+ (1,0) [0|1] ""  ZCUL,ZCUR,IDC,SBM,TBOX
 SG_ HVAC_WindExitMode : 37|3@0+ (1,0) [0|7] ""  CCURT1,ZCUL,ZCUR,IDC,ADC,TBOX
 SG_ HVAC_AirCirculationSt : 47|2@0+ (1,0) [0|3] ""  ZCUL,ZCUR,IDC,SBM,TBOX
 SG_ HVAC_PopUpDisplayReq : 45|1@0+ (1,0) [0|1] ""  IDC
 SG_ HVAC_PopupDisplayReq2 : 44|5@0+ (1,0) [0|31] ""  IDC
 SG_ AQM_IonPopReq : 55|1@0+ (1,0) [0|1] ""  IDC
 SG_ HVAC_DriverTempSelect : 54|5@0+ (0.5,18) [18|32] "degC"  CCURT1,ZCUL,ZCUR,IDC,SBM,TBOX
 SG_ AQM_IonMode : 49|2@0+ (1,0) [0|3] ""  ZCUL,ZCUR,IDC,TBOX
 SG_ HVAC_WindExitSpd : 63|4@0+ (1,0) [0|15] ""  CCURT1,ZCUL,ZCUR,IDC,TBOX
 SG_ HVAC_ECOSt : 59|1@0+ (1,0) [0|1] ""  ZCUR,IDC
 SG_ HVAC_WindExitSpdPercent : 56|7@0+ (1,0) [0|100] "%"  IDC
 SG_ HVAC_PTCPwrConsmp : 65|10@0+ (10,0) [0|10200] "W"  CCURT1,IDC,TBOX
 SG_ HVAC_PsnTempSelect : 87|5@0+ (0.5,18) [18|31] "degC"  ZCUL,ZCUR,IDC,SBM,TBOX
 SG_ HVAC_PTCWaterTempWarn : 82|1@0+ (1,0) [0|1] ""  IDC,TBOX
 SG_ HVAC_ComfortCfgSt : 81|2@0+ (1,0) [0|3] ""  IDC,TBOX
 SG_ HVAC_AirCirCfgSt : 88|1@0+ (1,0) [0|1] ""  IDC,TBOX
 SG_ HVAC_PTCOutletTargetTemp : 103|6@0+ (1,20) [20|80] "degC"  CCURT1,IDC,TBOX
 SG_ HVAC_AirQualitySenSt : 97|2@0+ (1,0) [0|3] ""  IDC,TBOX
 SG_ HVAC_FanspeedCfgSt : 111|2@0+ (1,0) [0|3] ""  IDC,TBOX
 SG_ HVAC_SceneDisplayReq : 109|2@0+ (1,0) [0|3] ""  IDC,TBOX
 SG_ HVAC_EvapratorSelfCleanSt : 107|1@0+ (1,0) [0|1] ""  IDC,TBOX
 SG_ HVAC_SolarFeaturesCfgSt : 106|1@0+ (1,0) [0|1] ""  IDC,TBOX
 SG_ HVAC_CorrectedExterTemp : 135|8@0+ (0.5,-40) [-40|87.5] "degC"  ZCUL,ZCUR,ZCUT,ITS,IDC,ADC,TBOX
 SG_ HVAC_CorrectedExterTempVD : 143|1@0+ (1,0) [0|1] ""  ZCUL,ZCUR,ZCUT,ITS,IDC,ADC
 SG_ HVAC_DualCircuSt : 174|2@0+ (1,0) [0|2] ""  ZCUR,IDC
 SG_ HVAC_CondDefSt : 204|2@0+ (1,0) [1|3] ""  CCURT1,IDC
 SG_ AQM_PM25CleanReq : 242|1@0+ (1,0) [0|1] ""  IDC
 SG_ AQM_FraganceRatioWarn : 267|2@0+ (1,0) [0|3] ""  IDC
 SG_ AQM_FraganceConcentrationReq : 279|2@0+ (1,0) [0|3] ""  ZCUR,IDC
 SG_ AQM_FragTasteRemanentRatio : 277|4@0+ (10,0) [0|100] "%"  IDC
 SG_ AQM_FraganceTaste : 273|2@0+ (1,0) [0|3] ""  IDC
 SG_ AQM_FraganceConcentration : 287|2@0+ (1,0) [0|3] ""  IDC
 SG_ AQM_FraganceBoxID : 285|2@0+ (1,0) [0|3] ""  IDC
 SG_ AQM_FraganceTaste_Seek : 283|4@0+ (1,0) [0|15] ""  IDC
 SG_ AQM_FraganceBoxLoad : 295|5@0+ (1,0) [0|31] ""  IDC
 SG_ HVAC_UnlockVentilationSt : 337|1@0+ (1,0) [0|1] ""  IDC
 SG_ AQM_PM25CirReq : 351|1@0+ (1,0) [0|1] ""  IDC
 SG_ HVAC_ECPPwrConsump : 367|11@0+ (10,0) [0|20320] "W"  CCURT1,IDC,TBOX

BO_ 288 CCU_3: 64 CCU
 SG_ PWL_LockAutoWinCloseFunCfgSt : 31|1@0+ (1,0) [0|1] ""  IDC
 SG_ PWL_PowerWinOpenWarn : 28|1@0+ (1,0) [0|1] ""  IDC

BO_ 825 CCU_5: 64 CCU
 SG_ RLS_RainfallLevel : 439|4@0+ (1,0) [0|15] ""  ADC,IDC
 SG_ RLS_RSErr : 400|1@0+ (1,0) [0|1] ""  ADC,IDC
 SG_ RLS_LSErr : 401|1@0+ (1,0) [0|1] ""  ADC,IDC
 SG_ RLS_WiperSpd : 385|4@0+ (1,0) [0|15] ""  ADC,IDC
 SG_ RLS_LampOnReqValid : 386|1@0+ (1,0) [0|1] ""  ADC,IDC
 SG_ RLS_LightOnReq : 387|1@0+ (1,0) [0|1] ""  ADC,CCURT1,IDC
 SG_ SSW_RLSeatAutoModeCfgSt : 452|1@0+ (1,0) [0|1] ""  IDC
 SG_ SSW_RRSeatAutoModeCfgSt : 451|1@0+ (1,0) [0|1] ""  IDC
 SG_ SSW_FRSeatAutoModeCfgSt : 31|1@0+ (1,0) [0|1] ""  IDC
 SG_ SSW_FLSeatAutoModeCfgSt : 30|1@0+ (1,0) [0|1] ""  IDC
 SG_ SSW_FLSeatHeatModeSt : 29|2@0+ (1,0) [0|3] ""  IDC
 SG_ MR_MirrorAutoFoldFuncCfgSt : 27|1@0+ (1,0) [0|1] ""  IDC
 SG_ MR_MirrorAngleDipFuncCfgSt : 26|2@0+ (1,0) [0|3] ""  IDC
 SG_ SSW_EasyEntryExitFuncCfgSt : 24|1@0+ (1,0) [0|1] ""  IDC
 SG_ SSW_SeatNapModePosSt : 39|1@0+ (1,0) [0|1] ""  IDC
 SG_ SSW_PosSaveRecallPopUpReq : 38|1@0+ (1,0) [0|1] ""  IDC
 SG_ SSW_SeatNapPopUpReq : 37|1@0+ (1,0) [0|1] ""  IDC
 SG_ SSW_FRSeatHeatModeSt : 36|2@0+ (1,0) [0|3] ""  IDC
 SG_ WW_FwpFaultSt : 34|1@0+ (1,0) [0|1] ""  IDC,ADC
 SG_ WW_RwpFaultSt : 33|1@0+ (1,0) [0|1] ""  IDC,ADC
 SG_ WW_FwshFaultSt : 32|1@0+ (1,0) [0|1] ""  IDC,ADC
 SG_ WW_RwshFaultSt : 47|1@0+ (1,0) [0|1] ""  IDC,ADC
 SG_ WW_FwpAutoModeSt : 46|1@0+ (1,0) [0|1] ""  IDC,ADC
 SG_ SSW_FRSeatVentSt : 52|3@0+ (1,0) [0|7] ""  IDC
 SG_ SSW_SeatNapModeSt : 49|2@0+ (1,0) [0|3] ""  IDC
 SG_ MR_LeftMirrorXCurrentPst : 63|8@0+ (0.5,0) [0|255] ""  IDC
 SG_ MR_LeftMirrorYCurrentPst : 71|8@0+ (0.5,0) [0|255] ""  IDC
 SG_ MR_RightMirrorXCurrentPst : 79|8@0+ (0.5,0) [0|255] ""  IDC
 SG_ MR_RightMirrorYCurrentPst : 87|8@0+ (0.5,0) [0|255] ""  IDC
 SG_ SSW_FLSeatSlideCurrentPst : 95|8@0+ (0.5,0) [0|100] "%"  IDC
 SG_ SSW_FLSeatHeightCurrentPst : 103|8@0+ (0.5,0) [0|100] "%"  IDC
 SG_ SSW_FLSeatBackrestCurrentPst : 111|8@0+ (0.5,0) [0|100] "%"  IDC
 SG_ SSW_FLSeatTiltCurrentPst : 119|8@0+ (0.5,0) [0|100] "%"  IDC
 SG_ SSW_SteeringAngleCurrentPst : 127|8@0+ (0.5,0) [0|100] "%"  IDC
 SG_ SSW_SteeringExtentCurrentPst : 135|8@0+ (0.5,0) [0|100] "%"  IDC
 SG_ SSW_PSCSOpeSt : 143|4@0+ (1,0) [0|15] ""  IDC
 SG_ WinVentilationReqExculFb : 139|2@0+ (1,0) [0|3] ""  IDC,TBOX
 SG_ SSW_FLSeatVentModeSt : 137|2@0+ (1,0) [0|3] ""  IDC,TBOX
 SG_ SSW_FRSeatHeatingSt : 148|3@0+ (1,0) [0|7] ""  IDC
 SG_ SSW_FRSeatVentModeSt : 145|2@0+ (1,0) [0|3] ""  IDC
 SG_ SSW_FRSeatSlideCurrentPst : 159|8@0+ (0.5,0) [0|100] "%"  IDC
 SG_ SSW_FRSeatHeightCurrentPst : 167|8@0+ (0.5,0) [0|100] "%"  IDC
 SG_ SSW_FRSeatBackrestCurrentPst : 175|8@0+ (0.5,0) [0|100] "%"  IDC
 SG_ SSW_FRSeatTiltCurrentPst : 183|8@0+ (0.5,0) [0|100] "%"  IDC
 SG_ SSW_FLSeatCushionCurrentPst : 191|8@0+ (0.5,0) [0|100] "%"  IDC
 SG_ SSW_FRSeatCushionCurrentPst : 199|8@0+ (0.5,0) [0|100] "%"  IDC
 SG_ SSW_FLSeatOttomanCurrentPst : 207|8@0+ (0.5,0) [0|100] "%"  IDC
 SG_ SSW_FRSeatOttomanCurrentPst : 215|8@0+ (0.5,0) [0|100] "%"  IDC
 SG_ PWL_FLWinCurrentPst : 327|8@0+ (0.5,0) [0|100] ""  IDC,TBOX
 SG_ PWL_FRWinCurrentPst : 335|8@0+ (0.5,0) [0|100] ""  IDC,TBOX
 SG_ PWL_RLWinCurrentPst : 343|8@0+ (0.5,0) [0|100] ""  IDC,TBOX
 SG_ PWL_RRWinCurrentPst : 351|8@0+ (0.5,0) [0|100] ""  IDC,TBOX
 SG_ PWL_FLWinCurrentOpeSt : 359|3@0+ (1,0) [0|7] ""  IDC,TBOX
 SG_ PWL_FRWinCurrentOpeSt : 356|3@0+ (1,0) [0|7] ""  IDC,TBOX
 SG_ PWL_RLWinCurrentOpeSt : 367|3@0+ (1,0) [0|7] ""  IDC,TBOX
 SG_ PWL_RRWinCurrentOpeSt : 364|3@0+ (1,0) [0|7] ""  IDC,TBOX
 SG_ WW_RainFallLevel : 391|4@0+ (1,0) [0|15] ""  IDC,ADC
 SG_ WW_RLSWarning_Rain : 402|1@0+ (1,0) [0|1] ""  IDC
 SG_ PLG_TravelPst : 431|8@0+ (0.5,0) [0|100] "%"  IDC
 SG_ PLG_SetPst : 435|4@0+ (0.5,0) [0|7.5] "%"  IDC
 SG_ PLG_DoorSt : 447|3@0+ (1,0) [0|7] ""  IDC
 SG_ PLG_ModeSW : 444|1@0+ (1,0) [0|1] ""  IDC

BO_ 291 CCU_6: 64 CCU
 SG_ WW_FWPInitAdjustSWPresent : 42|1@0+ (1,0) [0|1] ""  IDC
 SG_ WW_RearCamWasherVRResp : 123|2@0+ (1,0) [0|3] ""  IDC
 SG_ WW_RearCamWasherVKResp : 125|2@0+ (1,0) [0|3] ""  IDC
 SG_ ATWS_ATWSAlarmReq : 31|2@0+ (1,0) [0|3] ""  CCURT1,IDC,ADC
 SG_ ATWS_ATWSLEDIndCmd : 29|2@0+ (1,0) [0|3] ""  ZCUL,IDC
 SG_ ATWS_ATWSSt : 26|3@0+ (1,0) [0|7] ""  CCURT1,ZCUR,IDC,ADC
 SG_ WW_FrontWiperServiceMode : 41|1@0+ (1,0) [0|1] ""  ZCUF,IDC
 SG_ WW_RearWiperServiceMode : 40|1@0+ (1,0) [0|1] ""  ZCUF,ZCUT,IDC
 SG_ HRN_HornDoorLookAckEnable : 71|1@0+ (1,0) [0|1] ""  ZCUF,IDC
 SG_ HRN_HornVehAckEnable : 69|1@0+ (1,0) [0|1] ""  ZCUF,IDC
 SG_ WW_FWPIntLevelSt : 93|3@0+ (1,0) [0|7] ""  IDC
 SG_ WW_FWPAutoLevelSt : 90|3@0+ (1,0) [0|7] ""  IDC
 SG_ WW_FrontAutoWiperEnable : 103|1@0+ (1,0) [0|1] ""  IDC
 SG_ WW_FrontWiperVRResp : 102|2@0+ (1,0) [0|3] ""  IDC
 SG_ WW_FrontWasherVRResp : 100|2@0+ (1,0) [0|3] ""  IDC
 SG_ ATWS_ATWSAlarmHistory : 98|3@0+ (1,0) [0|7] ""  CCURT1,IDC
 SG_ WW_FrontWiperCtrlSt : 111|3@0+ (1,0) [0|7] ""  ZCUF,ZCUT,IDC,ADC,IFC
 SG_ WW_FrontAutoWiperPresent : 108|1@0+ (1,0) [0|1] ""  IDC
 SG_ WW_RearWiperCtrlSt : 107|3@0+ (1,0) [0|7] ""  ZCUF,ZCUT,IDC,ADC
 SG_ WW_RearWiperPresent : 104|1@0+ (1,0) [0|1] ""  IDC
 SG_ WW_RearWiperVRResp : 119|2@0+ (1,0) [0|3] ""  IDC
 SG_ WW_RearWasherVRResp : 117|2@0+ (1,0) [0|3] ""  IDC
 SG_ WW_FrontWiperCtrlSrc : 115|3@0+ (1,0) [0|7] ""  ZCUF,ZCUT,IDC,ADC
 SG_ WW_RearWiperCtrlSrc : 112|3@0+ (1,0) [0|7] ""  ZCUF,ZCUT,IDC,ADC

BO_ 865 CCU_7: 64 CCU
 SG_ EL_SideBrkLightCtrlCmd : 29|1@0+ (1,0) [0|1] ""  ADC,CCURT1,IDC,ZCUF,ZCUT
 SG_ EL_PositionLightCtrlSource : 34|3@0+ (1,0) [0|7] ""  ADC,IDC,MFS,TBOX,ZCUF,ZCUL,ZCUR,ZCUT
 SG_ EL_HeadLightDelayEnable : 31|1@0+ (1,0) [0|1] ""  IDC
 SG_ EL_RLSWarning_Light : 47|1@0+ (1,0) [0|1] ""  ZCUT,IDC
 SG_ EL_LampOnWarningReq : 80|1@0+ (1,0) [0|1] ""  IDC
 SG_ IL_AutoDomeLightCfgSt : 107|1@0+ (1,0) [0|1] ""  IDC
 SG_ EL_WelcomeLightMode : 119|4@0+ (1,0) [0|15] ""  IDC
 SG_ EL_LightShowSt : 115|4@0+ (1,0) [0|15] ""  ZCUF,ZCUL,ZCUR,ZCUT,IDC
 SG_ EL_HeadLightLevelingSwSt : 467|4@0+ (1,0) [0|15] ""  IDC
 SG_ EL_ALSEnable : 479|1@0+ (1,0) [0|1] ""  IDC
 SG_ EL_LeftTurnLightStForDisp : 478|1@0+ (1,0) [0|1] ""  IDC,ADC,IFC
 SG_ EL_RightTurnLightStForDisp : 477|1@0+ (1,0) [0|1] ""  IDC,ADC,IFC
 SG_ EL_PositionLightstForDisp : 476|1@0+ (1,0) [0|1] ""  CCURT1,MFS,IDC,ADC,IFC
 SG_ EL_FrontFogLightStForDisp : 475|1@0+ (1,0) [0|1] ""  IDC,ADC,IFC
 SG_ EL_RearFogLightStForDisp : 474|1@0+ (1,0) [0|1] ""  IDC,ADC,IFC
 SG_ EL_LowBeamStForDisp : 473|1@0+ (1,0) [0|1] ""  CCURT1,IDC,ADC,IFC
 SG_ EL_HighBeamStForDisp : 472|1@0+ (1,0) [0|1] ""  CCURT1,IDC,ADC,IFC

BO_ 293 CCU_8: 64 CCU
 SG_ TPMS_FrontLeftTirePressure : 207|8@0+ (1.373,0) [0|255] "kpa"  IDC
 SG_ TPMS_FrontRightTirePressure : 215|8@0+ (1.373,0) [0|255] "kpa"  IDC
 SG_ TPMS_RearRightTirePressure : 223|8@0+ (1.373,0) [0|255] "kpa"  IDC
 SG_ TPMS_RearLeftTirePressure : 231|8@0+ (1.373,0) [0|255] "kpa"  IDC
 SG_ TPMS_FrontLeftTireTemperature : 239|8@0+ (1,-50) [-50|204] "degC"  IDC
 SG_ TPMS_FrontRightTireTemperature : 247|8@0+ (1,-50) [-50|204] "degC"  IDC
 SG_ TPMS_RearRightTireTemperature : 255|8@0+ (1,-50) [-50|204] "degC"  IDC
 SG_ TPMS_RearLeftTireTemperature : 263|8@0+ (1,-50) [-50|204] "degC"  IDC
 SG_ TPMS_FrontWheelRCP : 271|4@0+ (10,200) [200|350] "kpa"  IDC
 SG_ TPMS_RearWheelRCP : 267|4@0+ (10,200) [200|350] "kpa"  IDC
 SG_ TPMS_FrontLeftTireLowPressure : 279|1@0+ (1,0) [0|1] ""  SRS,IDC
 SG_ TPMS_FrontRightTireLowPressure : 278|1@0+ (1,0) [0|1] ""  SRS,IDC
 SG_ TPMS_RearRightTireLowPressure : 277|1@0+ (1,0) [0|1] ""  SRS,IDC
 SG_ TPMS_RearLeftTireLowPressure : 276|1@0+ (1,0) [0|1] ""  SRS,IDC
 SG_ TPMS_FrontLeftTireHighPressure : 275|1@0+ (1,0) [0|1] ""  IDC
 SG_ TPMS_FrontRightTireHighPressure : 274|1@0+ (1,0) [0|1] ""  IDC
 SG_ TPMS_RearRightTireHighPressure : 273|1@0+ (1,0) [0|1] ""  IDC
 SG_ TPMS_RearLeftTireHighPressure : 272|1@0+ (1,0) [0|1] ""  IDC
 SG_ TPMS_FrontLeftTireDelaPressure : 287|1@0+ (1,0) [0|1] ""  IDC
 SG_ TPMS_FrontRightTireDelaPressure : 286|1@0+ (1,0) [0|1] ""  IDC
 SG_ TPMS_RearRightTireDelaPressure : 285|1@0+ (1,0) [0|1] ""  IDC
 SG_ TPMS_RearLeftTireDelaPressure : 284|1@0+ (1,0) [0|1] ""  IDC
 SG_ TPMS_FLTireHighTemperature : 283|1@0+ (1,0) [0|1] ""  IDC
 SG_ TPMS_FRTireHighTemperature : 282|1@0+ (1,0) [0|1] ""  IDC
 SG_ TPMS_RRTireHighTemperature : 281|1@0+ (1,0) [0|1] ""  IDC
 SG_ TPMS_RearLeftTireHighTemperature : 280|1@0+ (1,0) [0|1] ""  IDC
 SG_ TPMS_TireWarningLamp : 295|1@0+ (1,0) [0|1] ""  SRS,IDC
 SG_ TPMS_FrontLeftSensorLowBattery : 294|1@0+ (1,0) [0|1] ""  IDC
 SG_ TPMS_FrontRighSensorLowBattery : 293|1@0+ (1,0) [0|1] ""  IDC
 SG_ TPMS_RearRightSensorLowBattery : 292|1@0+ (1,0) [0|1] ""  IDC
 SG_ TPMS_RearLeftSensorLowBattery : 291|1@0+ (1,0) [0|1] ""  IDC
 SG_ TPMS_FrontLeftSensorFailure : 290|1@0+ (1,0) [0|1] ""  SRS,IDC
 SG_ TPMS_FrontRightSensorFailure : 289|1@0+ (1,0) [0|1] ""  SRS,IDC
 SG_ TPMS_RearRightSensorFailure : 288|1@0+ (1,0) [0|1] ""  SRS,IDC
 SG_ TPMS_RearLeftSensorFailure : 303|1@0+ (1,0) [0|1] ""  SRS,IDC
 SG_ TPMS_FrontLeftSensorNotCalibrate : 302|1@0+ (1,0) [0|1] ""  SRS,IDC
 SG_ TPMS_FRSensorNotCalibrate : 301|1@0+ (1,0) [0|1] ""  SRS,IDC
 SG_ TPMS_RearRightSensorNotCalibrate : 300|1@0+ (1,0) [0|1] ""  SRS,IDC
 SG_ TPMS_RearLeftSensorNotCalibrate : 299|1@0+ (1,0) [0|1] ""  SRS,IDC
 SG_ TPMS_FrontLeftSensorMute : 298|1@0+ (1,0) [0|1] ""  IDC
 SG_ TPMS_FrontRightSensorMute : 297|1@0+ (1,0) [0|1] ""  IDC
 SG_ TPMS_RearRightSensorMute : 296|1@0+ (1,0) [0|1] ""  IDC
 SG_ TPMS_RearLeftSensorMute : 311|1@0+ (1,0) [0|1] ""  IDC
 SG_ TPMS_SystemWarningLamp : 310|1@0+ (1,0) [0|1] ""  SRS,IDC

BO_ 294 CCU_9: 64 CCU
 SG_ LCK_DriverDoorAjarSt : 31|1@0+ (1,0) [0|1] ""  CCURT1,ZCUF,ZCUR,ZCUT,IBCS,IDC,ADC,IFC
 SG_ LCK_PassengerDoorAjarSt : 30|1@0+ (1,0) [0|1] ""  CCURT1,ZCUF,ZCUR,ZCUT,IDC,ADC,IFC
 SG_ LCK_DriverDoorLockSt : 29|1@0+ (1,0) [0|1] ""  ZCUR,ZCUT,IBCS,IDC,ADC,IFC
 SG_ LCK_PassengerDoorLockSt : 28|1@0+ (1,0) [0|1] ""  ZCUR,ZCUT,IDC,ADC,IFC
 SG_ LCK_VehicleDoorLockSt : 25|2@0+ (1,0) [0|3] ""  ZCUF,ZCUL,ZCUR,ZCUT,IDC,ADC,IFC
 SG_ LCK_VehicleChildSaftyLockSt : 39|1@0+ (1,0) [0|1] ""  IDC,ADC,IFC
 SG_ LCK_VehicleChildSaftyLockedIndic : 38|1@0+ (1,0) [0|1] ""  ZCUL,IDC,ADC,IFC
 SG_ LCK_VehicleDoorLockedIndicate : 41|1@0+ (1,0) [0|1] ""  ZCUL,IDC
 SG_ LCK_VehicleDoorUnlockedIndicate : 40|1@0+ (1,0) [0|1] ""  ZCUL,IDC
 SG_ LCK_LockOverHeatInhibit : 183|2@0+ (1,0) [0|3] ""  ZCUL,IDC
 SG_ LCK_LockVehicleModeInhibit : 181|2@0+ (1,0) [0|3] ""  ZCUL,IDC
 SG_ LCK_LockEmergencyInhibit : 179|2@0+ (1,0) [0|3] ""  ZCUL,IDC
 SG_ CCU_9_FreshnessValue : 455|16@0+ (1,0) [0|255] ""  ZCUF,ZCUL,ZCUR,ZCUT,IDC,ADC
 SG_ CCU_9_MAC_Check : 471|48@0+ (1,0) [0|255] ""  ZCUF,ZCUL,ZCUR,ZCUT,IDC,ADC

BO_ 909 CCU_ZCU_1: 64 CCU
 SG_ KAE_BLEChl7Connectingst : 267|2@0+ (1,0) [0|3] ""  IDC
 SG_ LCK_FLPowerReleaseFailedRemind : 27|1@0+ (1,0) [0|1] ""  IDC
 SG_ LCK_FRPowerReleaseFailedRemind : 26|1@0+ (1,0) [0|1] ""  IDC
 SG_ LCK_RLPowerReleaseFailedRemind : 25|1@0+ (1,0) [0|1] ""  IDC
 SG_ LCK_RRPowerReleaseFailedRemind : 24|1@0+ (1,0) [0|1] ""  IDC
 SG_ LCK_HoodAjarSt : 37|1@0+ (1,0) [0|1] ""  ZCUL,ZCUT,ZCUR,IDC,ADC,IFC
 SG_ LCK_FrontLeftDoorAjarSt : 36|1@0+ (1,0) [0|1] ""  ZCUF,ZCUR,ZCUT,IDC,ADC,IFC
 SG_ LCK_FrontRightDoorAjarSt : 35|1@0+ (1,0) [0|1] ""  ZCUF,ZCUR,ZCUT,IDC,ADC,IFC
 SG_ LCK_RearLeftDoorAjarSt : 34|1@0+ (1,0) [0|1] ""  ZCUL,RBM,IBCS,ZCUF,ZCUR,IDC,ADC,IFC
 SG_ LCK_RearRightDoorAjarSt : 33|1@0+ (1,0) [0|1] ""  ZCUL,IBCS,RBM,ZCUF,ZCUR,IDC,ADC,IFC
 SG_ LCK_TrunkAjarSt : 32|1@0+ (1,0) [0|1] ""  ZCUL,ZCUF,ZCUR,IDC,ADC,IFC
 SG_ LCK_FrontLeftDoorLockSt : 47|1@0+ (1,0) [0|1] ""  ZCUR,ZCUT,IDC,ADC,IFC
 SG_ LCK_FrontRightDoorLockSt : 46|1@0+ (1,0) [0|1] ""  ZCUR,IDC,ADC,IFC
 SG_ LCK_RearLeftDoorLockSt : 45|1@0+ (1,0) [0|1] ""  ZCUR,IDC,ADC,IFC
 SG_ LCK_RearRightDoorLockSt : 44|1@0+ (1,0) [0|1] ""  ZCUR,IDC,ADC,IFC
 SG_ LCK_RearLeftChildSaftyLockSt : 43|1@0+ (1,0) [0|1] ""  IDC,ADC,IFC
 SG_ LCK_RearRightChildSaftyLockSt : 42|1@0+ (1,0) [0|1] ""  IDC,ADC,IFC
 SG_ LCK_FrontLeftDoorHandlePosition : 135|8@0+ (1,0) [0|255] ""  IDC
 SG_ LCK_FrontRightDoorHandlePosition : 143|8@0+ (1,0) [0|255] ""  IDC
 SG_ LCK_RearLeftDoorHandlePosition : 151|8@0+ (1,0) [0|255] ""  IDC
 SG_ LCK_RearRightDoorHandlePosition : 159|8@0+ (1,0) [0|255] ""  IDC

CM_ SG_ 475 ACU_FRSeatOttomanExtentPosCtlReq "Front Right Seat Ottoman Extent Position Control Request";
CM_ SG_ 475 ACU_FRSeatOttomanAnglePosCtlReq "Front Right Seat Ottoman Angle Position Control Request";
CM_ SG_ 475 ACU_FLSeatOttomanExtentPosCtlReq "Front Left Seat Ottoman Extent Position Control Request";
CM_ SG_ 475 ACU_FLSeatOttomanAnglePosCtlReq "Front Left Seat Ottoman Angle Position Control Request";
CM_ SG_ 475 IDC_4_Counter "E2E Profile 5 Counter";
CM_ SG_ 475 IDC_4_CRC "E2E Profile 5 CRC";
CM_ SG_ 475 ACU_HVACFR_OffOnBtnSt "ON/OFF Button Status";
CM_ SG_ 475 ACU_HVACFR_AutoModeBtnSt "AUTO Button Status";
CM_ SG_ 475 ACU_HVACFR_ModeBtnSt "MODE Button Status";
CM_ SG_ 475 ACU_HVACF_FDefrostBtnSt "DEF Button Status";
CM_ SG_ 475 ACU_HVACF_RDefrostBtnSt "RrDEF Button Status";
CM_ SG_ 475 ACU_HVACF_DualSyncBtnSt "DUAL/sync Button Status";
CM_ SG_ 475 ACU_HVACF_IonBtnSt "ION Button Status";
CM_ SG_ 475 ACU_HVACFR_FanIncBtnSt "Fan+  Button Status";
CM_ SG_ 475 ACU_HVACFR_FanDecBtnSt "Fan-  Button Status";
CM_ SG_ 475 ACU_HVACF_CirBtnSt "Circulation Button Status";
CM_ SG_ 475 ACU_HVACF_ACBtnSt "AC Button Status";
CM_ SG_ 475 ACU_HVACF_ACMaxBtnSt "ACMax Button Status";
CM_ SG_ 475 ACU_HVACF_FLTempIncBtnSt "Front Left Temp+  Button Status";
CM_ SG_ 475 ACU_HVACF_FLTempDecBtnSt "Front Left Temp-  Button Status";
CM_ SG_ 475 ACU_HVACF_FRTempIncBtnSt "Front Right Temp+  Button Status";
CM_ SG_ 475 ACU_HVACF_FRTempDecBtnSt "Front Right Temp-  Button Status";
CM_ SG_ 475 ACU_HVACF_ECOBtnSt "ACU Eco Button Status";
CM_ SG_ 475 ACU_HVAC_RearOnOffBtnSt "Rear ON/OFF Button Status";
CM_ SG_ 475 ACU_HVAC_RearAutoModeBtnSt "Rear AUTO Button Status";
CM_ SG_ 475 ACU_LeftMirrorXPosCtlReq "Left Mirror X Positon Control Request";
CM_ SG_ 475 ACU_LeftMirrorYPosCtlReq "Left Mirror Y Positon Control Request";
CM_ SG_ 475 ACU_RightMirrorXPosCtlReq "Right Mirror X Positon Control Request";
CM_ SG_ 475 ACU_RightMirrorYPosCtlReq "Right Mirror Y Positon Control Request";
CM_ SG_ 475 ACU_FLSeatSlidePosCtlReq "Front Left Seat Slide Positon Control Request";
CM_ SG_ 475 ACU_FLSeatHeightPosCtlReq "Front Left Seat Height Positon Control Request";
CM_ SG_ 475 ACU_FLSeatBackrestPosCtlReq "Front Left Seat Backrest Positon Control Request";
CM_ SG_ 475 ACU_FLSeatTiltPosCtlReq "Front Left Seat Tilt Positon Control Request";
CM_ SG_ 475 ACU_SteeringAnglePosCtlReq "Steering Angle Positon Control Request";
CM_ SG_ 475 ACU_SteeringExtentPosCtlReq "Steering Extent Positon Control Request";
CM_ SG_ 475 ACU_FRSeatSlidePosCtlReq "Front Right Seat Slide Positon Control Request";
CM_ SG_ 475 ACU_FRSeatHeightPosCtlReq "Front Right Seat Height Positon Control Request";
CM_ SG_ 475 ACU_FRSeatBackrestPosCtlReq "Front Right Seat Backrest Positon Control Request";
CM_ SG_ 475 ACU_FRSeatTiltPosCtlReq "Front Right Seat Tilt Positon Control Request";
CM_ SG_ 475 ACU_FLSeatCushionPosCtlReq "Front Left Seat Cushion Positon Control Request";
CM_ SG_ 475 ACU_FRSeatCushionPosCtlReq "Front Right Seat Cushion Positon Control Request";
CM_ SG_ 475 ACU_FLSeatOttomanPosCtlReq "Front Left Seat Ottoman Positon Control Request";
CM_ SG_ 475 ACU_FRSeatOttomanPosCtlReq "Front Right Seat Ottoman Positon Control Request";
CM_ SG_ 967 DMS_YawnSt "Indication Driver's mouth Status";
CM_ SG_ 967 IDC_DMS_1_Dummy11 "ndication FaceID_Regonize_result";
CM_ SG_ 967 DMS_FaceID "FaceID";
CM_ SG_ 967 DMS_SeatBeltRigntrearStatus "Indication_SeatBeltRigntrearStatus";
CM_ SG_ 967 DMS_SeatBeltMidrearStatus "Indication_SeatBeltMidrearStatus";
CM_ SG_ 967 DMS_SeatBeltLeftrearStatus "Indication_SeatBeltLeftrearStatus";
CM_ SG_ 967 DMS_SeatBeltCodriverStatus "Indication_SeatBeltCodriverStatus";
CM_ SG_ 967 DMS_SeatBeltDriverStatus "Indication_SeatBeltDriverStatus";
CM_ SG_ 967 DMS_MidrearChild "Indication_MidrearChild";
CM_ SG_ 967 DMS_RigntrearChild "Indication_RigntrearChild";
CM_ SG_ 967 DMS_LeftrearChild "Indication_LeftrearChild";
CM_ SG_ 967 DMS_CodriverChild "Indication_CodriverChild";
CM_ SG_ 967 DMS_MidrearThumbleftgestures "Indication_MidrearThumbleftgestures";
CM_ SG_ 967 DMS_RigntrearThumbleftgestures "Indication_RigntrearThumbleftgestures";
CM_ SG_ 967 DMS_LeftrearThumbleftgestures "Indication_LeftrearThumbleftgestures";
CM_ SG_ 967 DMS_CodriverThumbleftgestures "Indication_CodriverThumbleftgestures";
CM_ SG_ 967 DMS_DriverThumbleftgestures "Indication_DriverThumbleftgestures";
CM_ SG_ 967 DMS_MidrearThumbrightgestures "Indication_MidrearThumbrightgestures";
CM_ SG_ 967 DMS_RigntrearThumbrightgestures "Indication_RigntrearThumbrightgestures";
CM_ SG_ 967 DMS_LeftrearThumbrightgestures "Indication_LeftrearThumbrightgestures";
CM_ SG_ 967 DMS_CodriverThumbrightgestures "Indication_CodriverThumbrightgestures";
CM_ SG_ 967 DMS_DriverThumbrightgestures "Indication_DriverThumbrightgestures";
CM_ SG_ 967 DMS_MidrearThumbdowngestures "Indication_MidrearThumbdowngestures";
CM_ SG_ 967 DMS_RigntrearThumbdowngestures "Indication_RigntrearThumbdowngestures";
CM_ SG_ 967 DMS_LeftrearThumbdowngestures "Indication_LeftrearThumbdowngestures";
CM_ SG_ 967 DMS_CodriverThumbdowngestures "Indication_CodriverThumbdowngestures";
CM_ SG_ 967 DMS_DriverThumbdowngestures "Indication_DriverThumbdowngestures";
CM_ SG_ 967 DMS_MidrearThumbupgestures "Indication_MidrearThumbupgestures";
CM_ SG_ 967 DMS_RigntrearThumbupgestures "Indication_RigntrearThumbupgestures";
CM_ SG_ 967 DMS_LeftrearThumbupgestures "Indication_LeftrearThumbupgestures";
CM_ SG_ 967 DMS_CodriverThumbupgestures "Indication_CodriverThumbupgestures";
CM_ SG_ 967 DMS_DriverThumbupgestures "Indication_DriverThumbupgestures";
CM_ SG_ 967 DMS_MidrearPapergesture "Indication_MidrearPapergesture";
CM_ SG_ 967 DMS_RigntrearPapergesture "Indication_RigntrearPapergesture";
CM_ SG_ 967 DMS_LeftrearPapergesture "Indication_LeftrearPapergesture";
CM_ SG_ 967 DMS_CodriverPapergesture "Indication_CodriverPapergesture";
CM_ SG_ 967 DMS_DriverPapergesture "Indication_DriverPapergesture";
CM_ SG_ 967 DMS_MidrearScissorsgesture "Indication_MidrearScissorsgesture";
CM_ SG_ 967 DMS_RigntrearScissorsgesture "Indication_RigntrearScissorsgesture";
CM_ SG_ 967 DMS_LeftrearScissorsgesture "Indication_LeftrearScissorsgesture";
CM_ SG_ 967 DMS_CodriverScissorsgesture "Indication_CodriverScissorsgesture";
CM_ SG_ 967 DMS_DriverScissorsgesture "Indication_DriverScissorsgesture";
CM_ SG_ 967 DMS_MidrearRockgesture "Indication_MidrearRockgesture";
CM_ SG_ 967 DMS_RigntrearRockgesture "Indication_RigntrearRockgesture";
CM_ SG_ 967 DMS_LeftrearRockgesture "Indication_LeftrearRockgesture";
CM_ SG_ 967 DMS_CodriverRockgesture "Indication_CodriverRockgesture";
CM_ SG_ 967 DMS_DriverRockgesture "Indication_DriverRockgesture";
CM_ SG_ 967 DMS_MidrearWavepalmtotheleft "Indication_MidrearWavepalmtotheleft";
CM_ SG_ 967 DMS_RigntrearWavepalmtotheleft "Indication_RigntrearWavepalmtotheleft";
CM_ SG_ 967 DMS_LeftrearWavepalmtotheleft "Indication_LeftrearWavepalmtotheleft";
CM_ SG_ 967 DMS_CodriverWavepalmtotheleft "Indication_CodriverWavepalmtotheleft";
CM_ SG_ 967 DMS_DriverWavepalmtotheleft "Indication_DriverWavepalmtotheleft";
CM_ SG_ 967 DMS_MidrearWavepalmtotheright "Indication_MidrearWavepalmtotheright";
CM_ SG_ 967 DMS_RigntrearWavepalmtotheright "Indication_RigntrearWavepalmtotheright";
CM_ SG_ 967 DMS_LeftrearWavepalmtotheright "Indication_LeftrearWavepalmtotheright";
CM_ SG_ 967 DMS_CodriverWavepalmtotheright "Indication_CodriverWavepalmtotheright";
CM_ SG_ 967 DMS_DriverWavepalmtotheright "Indication_DriverWavepalmtotheright";
CM_ SG_ 967 DMS_MidrearDownwardwave "Indication_MidrearDownwardwave";
CM_ SG_ 967 DMS_RigntrearDownwardwave "Indication_RigntrearDownwardwave";
CM_ SG_ 967 DMS_LeftrearDownwardwave "Indication_LeftrearDownwardwave";
CM_ SG_ 967 DMS_CodriverDownwardwave "Indication_CodriverDownwardwave";
CM_ SG_ 967 DMS_DriverDownwardwave "Indication_DriverDownwardwave";
CM_ SG_ 967 DMS_MidrearUpwardwave "Indication_MidrearUpwardwave";
CM_ SG_ 967 DMS_RigntrearUpwardwave "Indication_RigntrearUpwardwave";
CM_ SG_ 967 DMS_LeftrearUpwardwave "Indication_LeftrearUpwardwave";
CM_ SG_ 967 DMS_CodriverUpwardwave "Indication_CodriverUpwardwave";
CM_ SG_ 967 DMS_DriverUpwardwave "Indication_DriverUpwardwave";
CM_ SG_ 967 DMS_MidrearForefingercircleleft "Indication_MidrearForefingercircleleft";
CM_ SG_ 967 DMS_RigntrearForefingercirclelef "Indication_RigntrearForefingercircleleft";
CM_ SG_ 967 DMS_LeftrearForefingercircleleft "Indication_LeftrearForefingercircleleft";
CM_ SG_ 967 DMS_CodriverForefingercircleleft "Indication_CodriverForefingercircleleft";
CM_ SG_ 967 DMS_DriverForefingercircleleft "Indication_DriverForefingercircleleft";
CM_ SG_ 967 DMS_MidrearForefingercircleright "Indication_MidrearForefingercircleright";
CM_ SG_ 967 DMS_RigntrearForefingercirclerig "Indication_RigntrearForefingercircleright";
CM_ SG_ 967 DMS_LeftrearForefingercirclerigh "Indication_LeftrearForefingercircleright";
CM_ SG_ 967 DMS_CodriverForefingercirclerigh "Indication_CodriverForefingercircleright";
CM_ SG_ 967 DMS_DriverForefingercircleright "Indication_DriverForefingercircleright";
CM_ SG_ 967 DMS_MidrearOKgesture "Indication_MidrearOKgesture";
CM_ SG_ 967 DMS_RigntrearOKgesture "Indication_RigntrearOKgesture";
CM_ SG_ 967 DMS_LeftrearOKgesture "Indication_LeftrearOKgesture";
CM_ SG_ 967 DMS_CodriverOKgesture "Indication_CodriverOKgesture";
CM_ SG_ 967 DMS_DriverOKgesture "Indication_DriverOKgesture";
CM_ SG_ 967 DMS_MidrearHandheartgesture "Indication_MidrearHandheartgesture";
CM_ SG_ 967 DMS_RigntrearHandheartgesture "Indication_RigntrearHandheartgesture";
CM_ SG_ 967 DMS_LeftrearHandheartgesture "Indication_LeftrearHandheartgesture";
CM_ SG_ 967 DMS_CodriverHandheartgesture "Indication_CodriverHandheartgesture";
CM_ SG_ 967 DMS_DriverHandheartgesture "Indication_DriverHandheartgesture";
CM_ SG_ 967 DMS_CarOwner " Indication_CarOwner";
CM_ SG_ 967 DMS_PersonGender " Indication_Gender";
CM_ SG_ 967 DMS_SeatMidrearSt "Indication_SeatMidrearStatus";
CM_ SG_ 967 DMS_SeatRigntrearSt "Indication_SeatRigntrearStatus";
CM_ SG_ 967 DMS_SeatLeftrearSt "Indication_SeatLeftrearStatus";
CM_ SG_ 967 DMS_PersonAge " Indication_Age";
CM_ SG_ 967 DMS_SeatMidmiddleSt "Indication_SeatMidmiddleStatus";
CM_ SG_ 967 DMS_SeatCodriverSt "Indication_SeatCodriverStatus";
CM_ SG_ 967 DMS_PersonCount "Indication_PersonCount";
CM_ SG_ 967 DMS_DriverDistractionSt "Indicates the distraction level of the driver";
CM_ SG_ 967 DMS_SeatDriverSt "Indication_SeatDriverStatus";
CM_ SG_ 967 DMS_DriverInterestsRegion "Indication Region of interests";
CM_ SG_ 967 DMS_DriverFatigueSt "Indicates the fatigue level of the driver";
CM_ SG_ 967 DMS_FaceIDFailCause "Indication FaceID_Verify/RegisterFail_Cause ";
CM_ SG_ 967 DMS_FaceIDWelcomeMode "Indication FaceID Welcome mode";
CM_ SG_ 967 DMS_DriverFaceID "Indication FaceID_Number";
CM_ SG_ 967 DMS_MidrearHealthSt "Indication_MidrearHealthSt";
CM_ SG_ 967 DMS_RigntrearHealthSt "Indication_RigntrearHealthSt";
CM_ SG_ 967 DMS_LeftrearHealthSt "Indication_LeftrearHealthSt";
CM_ SG_ 967 DMS_CodriverHealthSt "Indication_CodriverHealthSt";
CM_ SG_ 967 DMS_SeatPositionID "Indication_SeatPosition ID";
CM_ SG_ 967 DMS_MidrearTelephoneSt "Indication_MidrearTelephoneSt";
CM_ SG_ 967 DMS_RigntrearTelephoneSt "Indication_RigntrearTelephoneSt";
CM_ SG_ 967 DMS_LeftrearTelephoneSt "Indication_LeftrearTelephoneSt";
CM_ SG_ 967 DMS_CodriverTelephoneSt "Indication_CodriverTelephoneSt";
CM_ SG_ 967 DMS_MidrearSmokeSt "Indication_MidrearSmokeSt";
CM_ SG_ 967 DMS_RigntrearSmokeSt "Indication_RigntrearSmokeSt";
CM_ SG_ 967 DMS_LeftrearSmokeSt "Indication_LeftrearSmokeSt";
CM_ SG_ 967 DMS_MidrearExpressionSt "Indication_MidrearExpressionSt";
CM_ SG_ 967 DMS_RigntrearExpressionSt "Indication_RigntrearExpressionSt";
CM_ SG_ 967 DMS_LeftrearExpressionSt "Indication_LeftrearExpressionSt";
CM_ SG_ 967 DMS_CodriverExpressionSt "Indication_CodriverExpressionSt";
CM_ SG_ 967 DMS_CodriverSmokeSt "Indication_CodriverSmokeSt";
CM_ SG_ 967 DMS_ObjectSt "Object";
CM_ SG_ 967 DMS_PetSt "Pet";
CM_ SG_ 967 DMS_DistrWarnSt "Provides the driver distraction determined by the driver facing camera";
CM_ SG_ 967 DMS_FatigWarnSt "Indicates the fatigue level of the driver";
CM_ SG_ 967 DMS_SeatLeftmiddleSt "Indication_SeatLeftmiddleStatus";
CM_ SG_ 967 DMS_DriverHealthSt "Indication_DriverHealthSt";
CM_ SG_ 967 DMS_DriverTelephoneSt "Indication_DriverTelephoneSt";
CM_ SG_ 967 DMS_DriverSmokeSt "Indication_DriverSmokeSt";
CM_ SG_ 967 DMS_GlassWearSt " Indication_GlassWearSt";
CM_ SG_ 967 DMS_MouthSt "Float_MouthSt";
CM_ SG_ 967 DMS_RightEyeOpenSt "Indication Driver's Right Eye Open Status";
CM_ SG_ 967 DMS_LeftEyeOpenSt "Indication Driver's Left Eye Open Status";
CM_ SG_ 967 DMS_FaceIDDeleteResult "Indication FaceID_Delete_result";
CM_ SG_ 967 DMS_FaceIDRegisterResult "Indication FaceID_Register_result";
CM_ SG_ 967 DMS_FaceIDStatus "Indication FaceID Status";
CM_ SG_ 967 DMS_DriverExpressionSt "Driver Expression status";
CM_ SG_ 967 DMS_1_Checksum "E2E Profile 5 CRC";
CM_ SG_ 967 DMS_1_MsgCounter "E2E Profile 5 Counter";
CM_ SG_ 967 DMS_SysErrSt "Driver monitoring system error status";
CM_ SG_ 967 DMS_DrvrDetSts "States whether the driver facing camera has detected the presence of a driver.";
CM_ SG_ 967 DMS_InterestsRegion "region of interests";
CM_ SG_ 967 DMS_L3DriverDistractionSt "driver distraction state for L3";
CM_ SG_ 967 DMS_L3DriverFatigueSt "driver fatigue state for L3";
CM_ SG_ 1963 IDC_Diag_Response "IDC diagnostic response";
CM_ SG_ 1323 IDC_NMNodeAddress "IDC node address";
CM_ SG_ 1323 IDC_NMDataField "IDC Network management data";
CM_ SG_ 1323 IDC_NMWakeupOrigin "Origin of the wake up";
CM_ SG_ 1323 IDC_PNCInformation0 "PNC Information";
CM_ SG_ 1323 IDC_PNCInformation1 "PNC Information";
CM_ SG_ 169 IDC_SecReq "nan";
CM_ SG_ 157 IDC_IMMO "IDC feedback anti-theft results";
CM_ SG_ 122 IDC_SEC_KEY_Defaultencoding "IDC feedback key and default_encoding results";
CM_ SG_ 624 KAE_KeyReminderWarning "Key reminder warning";
CM_ SG_ 624 KAE_DoorLockWarning "Door lock warning";
CM_ SG_ 624 KAE_StartAuthFailWarning "Start Auth Fail Warning";
CM_ SG_ 624 KAE_KeyBattaryLowWarning "Entity Key Battary Low Warning";
CM_ SG_ 624 KAE_IDOutWarning "ID outside vehicle warning";
CM_ SG_ 624 ZCUR_1_FreshnessValue "nan";
CM_ SG_ 624 ZCUR_1_MAC_Check "nan";
CM_ SG_ 777 SSW_FROttomanExtentCurrentOpeSt "Front Right Seat Ottoman Extent Current Operation Status";
CM_ SG_ 777 SSW_FROttomanExtentCurrentPst "Front Right Seat Ottoman Extent  Current Position";
CM_ SG_ 777 SSW_FROttomanAngleCurrentOpeSt "Front Right Seat Ottoman Angle Current Operation Status";
CM_ SG_ 777 SSW_FROttomanAngleCurrentPst "Front Right Seat Ottoman Angle Current Position";
CM_ SG_ 777 SSW_FRSeatSlideCurrentPst "Front Right Seat Slide Current  Position Percentage ";
CM_ SG_ 777 SSW_FRSeatHeightCurrentPst "Front Right Seat Height Current  Position Percentage ";
CM_ SG_ 777 SSW_FRSeatBackrestCurrentPst "Front Right Seat Backrest Current  Position Percentage ";
CM_ SG_ 777 SSW_FRSeatTiltCurrentPst "Front Right Seat Tilt Current  Position Percentage ";
CM_ SG_ 777 SSW_FRSeatCushionCurrentPst "Front Right Seat Cushion Current  Position Percentage ";
CM_ SG_ 777 SSW_FRSeatOttomanCurrentPst "Front Right Seat Ottoman Current  Position Percentage ";
CM_ SG_ 777 SSW_FRSeatHeatingSt "Front Right Seat Heating Status";
CM_ SG_ 777 SSW_FRSeatVentSt "Front Right Seat Ventilation Status";
CM_ SG_ 777 EL_MRTurnLightSt "Middle right turn light status";
CM_ SG_ 777 EL_MRTurnLightFaultSt "Middle right turn light fault status";
CM_ SG_ 786 SSW_FRMassageForceSt "Front Right massage intensity";
CM_ SG_ 786 SSW_FRMassageModeSt "Front Right massage mode";
CM_ SG_ 786 SSW_FRSPAMode "Front Right SPA Mode status";
CM_ SG_ 786 SSW_FRLumbarModeSt "Front Right lumbar mode";
CM_ SG_ 786 SSW_FRMassageSt "Front Right massage status";
CM_ SG_ 786 AQM_CO2DataVD "CO2 Data Valid";
CM_ SG_ 786 AQM_CO2Data "CO2 Data";
CM_ SG_ 786 AQM_PM25Data "PM2.5Data";
CM_ SG_ 786 AQM_PM10Data "PM10 Data";
CM_ SG_ 786 AQM_PM25DataVD "PM25 Data Valid";
CM_ SG_ 786 AQM_PM10DataVD "PM10 Data Valid";
CM_ SG_ 786 AQM_PM25ValueOutVD "outside PM2.5 value validity";
CM_ SG_ 786 AQM_PM25ValueOut "outside PM2.5 value";
CM_ SG_ 342 KAE_KUID "KAE  user-ID";
CM_ SG_ 342 KAE_RKEChargeGunUnlockReq " Charge Gun Unloc kRequest";
CM_ SG_ 632 SSW_FLLumbarOpeSt "Front Left Lumbar and Massage Operation State";
CM_ SG_ 632 SSW_FLOttomanExtentCurrentOpeSt "Front Left Seat Ottoman Extent Current Operation Status";
CM_ SG_ 632 SSW_FLOttomanExtentCurrentPst "Front Left Seat Ottoman Extent  Current Position";
CM_ SG_ 632 SSW_FLOttomanAngleCurrentOpeSt "Front Left Seat Ottoman Angle Current Operation Status";
CM_ SG_ 632 SSW_FLOttomanAngleCurrentPst "Front Left Seat Ottoman Angle Current Position";
CM_ SG_ 632 SSW_FLSeatVentSt "Front Left Seat Ventilation Status";
CM_ SG_ 632 SSW_FLSeatHeatingSt "Front Left Seat Heating Status";
CM_ SG_ 632 SSW_FLSeatSlideCurrentPst "Front Left Seat Slide Current  Position Percentage";
CM_ SG_ 632 SSW_FLSeatHeightCurrentPst "Front Left Seat Height Current  Position Percentage ";
CM_ SG_ 632 SSW_FLSeatBackrestCurrentPst "Front Left Seat Backrest Current  Position Percentage ";
CM_ SG_ 632 SSW_FLSeatTiltCurrentPst "Front Left Seat Tilt Current Position Percentage ";
CM_ SG_ 632 SSW_SteeringAngleCurrentPst "Steering Angle Current  Position Percentage ";
CM_ SG_ 632 SSW_SteeringExtentCurrentPst "Steering Extent Current  Position Percentage ";
CM_ SG_ 632 SSW_FLSeatCushionCurrentPst "Front Left Seat Cushion Current  Position Percentage ";
CM_ SG_ 632 SSW_FLSeatOttomanCurrentPst "Front Left Seat Ottoman Current  Position Percentage ";
CM_ SG_ 632 SSW_SteerHeatSt "Steering Wheel Heat Status";
CM_ SG_ 776 EL_MLTurnLightSt "Middle left turn light status";
CM_ SG_ 776 EL_MLTurnLightFaultSt "Middle left turn light fault status";
CM_ SG_ 776 UINM_HazardLightSwSt "Hazard light switch status";
CM_ SG_ 791 WW_FWPMotorSt "FrontWiper Motor status";
CM_ SG_ 791 WW_FWSHLevelWarning "Remind of Insufficient Glass Cleaner";
CM_ SG_ 791 EL_FLPositionLightSt "Front left position light status";
CM_ SG_ 791 EL_FLPositionLightFaultSt "Front left position light fault status";
CM_ SG_ 791 EL_FRPositionLightSt "Front Right position light status";
CM_ SG_ 791 EL_FRPositionLightFaultSt "Front Right position light fault status";
CM_ SG_ 791 EL_LeftLowBeamSt "Left low beam status";
CM_ SG_ 791 EL_LeftLowBeamFaultSt "Left low beam fault status";
CM_ SG_ 791 EL_RightLowBeamSt "Right low beam status";
CM_ SG_ 791 EL_RightLowBeamFaultSt "Right low beam fault status";
CM_ SG_ 791 EL_LeftHighBeamSt "Left high beam status";
CM_ SG_ 791 EL_LeftHighBeamFaultSt "Left high beam fault status";
CM_ SG_ 791 EL_RightHighBeamSt "Right high beam status";
CM_ SG_ 791 EL_RightHighBeamFaultSt "Right high beam fault status";
CM_ SG_ 791 EL_FLFogLightSt "Front left fog light status";
CM_ SG_ 791 EL_FLFogLightFaultSt "Front left fog light fault status";
CM_ SG_ 791 EL_FRFogLightSt "Front right fog light status";
CM_ SG_ 791 EL_FRFogLightFaultSt "Front right fog light fault status";
CM_ SG_ 791 EL_LeftDRLFaultSt "Left day time running light fault status";
CM_ SG_ 791 EL_RightDRLFaultSt "Right day time running light fault status";
CM_ SG_ 791 EL_FLTurnLightSt "Front left turn light status";
CM_ SG_ 791 EL_FLTurnLightFaultSt "Front left turn light fault status";
CM_ SG_ 791 EL_FRTurnLightSt "Front right turn light status";
CM_ SG_ 791 EL_FRTurnLightFaultSt "Front right turn light fault status";
CM_ SG_ 791 EBSF_SOC "State of Charge";
CM_ SG_ 791 EBSF_SOC_STATE "SOC Status";
CM_ SG_ 792 EL_CHMSLSt "Centre high mounted stop lamp status";
CM_ SG_ 792 EL_SideBrkLightSt "Side brake light status";
CM_ SG_ 792 EL_ReverseLightSt "Reverse light status";
CM_ SG_ 792 UMM_SecondMIDSeatSt "Second Middle Seat Sensor Status";
CM_ SG_ 792 UMM_SecondRHSeatSt "Second Right Seat Sensor Status";
CM_ SG_ 792 UMM_SecondLHSeatSt "Second Left Seat Sensor Status";
CM_ SG_ 792 PLG_SetPosition "PLG set position";
CM_ SG_ 792 LCK_PowerFillerCapAngle "PowerFillerCapOpenAngle";
CM_ SG_ 792 EL_ReverseLightFaultSt "Reverse light fault status";
CM_ SG_ 792 EL_SideBrkLightFaultSt "Side brake light fault status";
CM_ SG_ 792 EL_CHMSLFaultSt "Centre high mounted stop lamp fault status";
CM_ SG_ 792 EL_RLPositionLightSt "Rear left position light status";
CM_ SG_ 792 EL_RLPositionLightFaultSt "Rear left position light fault status";
CM_ SG_ 792 EL_RRPositionLightSt "Rear right position light status";
CM_ SG_ 792 EL_RRPositionLightFaultSt "Rear right position light fault status";
CM_ SG_ 792 EL_RearFogLightSt "Rear fog light status";
CM_ SG_ 792 EL_RearFogLightFaultSt "Rear fog light fault status";
CM_ SG_ 792 EL_RLTurnLightSt "Rear left turn light status";
CM_ SG_ 792 EL_RLTurnLightFaultSt "Rear left turn light fault status";
CM_ SG_ 792 EL_RRTurnLightSt "Rear right turn light status";
CM_ SG_ 792 EL_RRTurnLightFaultSt "Rear right turn light fault status";
CM_ SG_ 792 LCK_RearLeftDoorLockAction "RearLeftDoorLockAction";
CM_ SG_ 616 EEM_LvElecEgySt "State of low voltage electric energy for  Mian electric network";
CM_ SG_ 616 UMM_FrontPassengerSeatSt "Front Right Seat Sensor Status";
CM_ SG_ 616 UMM_EmergencyWarning "Emergency Off Warning";
CM_ SG_ 616 UINM_BrakeSWSt "Brake Swtich state";
CM_ SG_ 616 UMM_OpIndicationWarning "Start OpIndication Warning";
CM_ SG_ 616 UMM_UsageModeSt "Usage mode state";
CM_ SG_ 616 UINM_BrakeSWNCSt "Brake Swtich NC state";
CM_ SG_ 616 UINM_BrakeSWNOSt "Brake Swtich NO state";
CM_ SG_ 616 UMM_ReadyForbidWarning "nan";
CM_ SG_ 616 UMM_PowerKeepMode "Power Keep Mode";
CM_ SG_ 616 UMM_PowerOffEnable "Power off Enable Status";
CM_ SG_ 616 UMM_PowerKeepEnable "Power keep Enable Status";
CM_ SG_ 616 UMM_DriverSeatSt "Front Left Seat Sensor Status";
CM_ SG_ 616 VMM_VehModeSt "Vehicle mode state";
CM_ SG_ 616 VMM_OTAModeSt "OTA Mode state";
CM_ SG_ 616 IPDS_EnablePowerSup "Enable power supply";
CM_ SG_ 616 EEM_LdCtlLv "	 Electrical Energy Management LoadControl level";
CM_ SG_ 616 EEM_LdCtlSt "Electrical Energy Management LoadControl switch state";
CM_ SG_ 616 CCU_1_FreshnessValue "nan";
CM_ SG_ 616 CCU_1_MAC_Check "nan";
CM_ SG_ 816 AQM_FreshPopReq "Inside car high CO2 request Fresh circulation";
CM_ SG_ 816 AQM_CO2CleanReq "Inside car high CO2 request ventilate";
CM_ SG_ 816 HVAC_InCarAutoVentilationSt "HVAC In Car Auto Ventilation State";
CM_ SG_ 816 HVAC_RearDefrostSt "Rear window and mirror heater activation status";
CM_ SG_ 816 HVAC_ACSt "The HVAC A/C state display";
CM_ SG_ 816 HVAC_ACmaxSt "The HVAC A/C max state display";
CM_ SG_ 816 HVAC_AutoDefCfgSt "auto deforst Configurates status";
CM_ SG_ 816 HVAC_TimedVentilationSt "Timed Ventilation Configurates status";
CM_ SG_ 816 HVAC_DualSyncSt "The HVAC dual Sync control state";
CM_ SG_ 816 HVAC_AutoSt "The HVAC auto state display";
CM_ SG_ 816 HVAC_WindExitMode "The wind exit mode";
CM_ SG_ 816 HVAC_AirCirculationSt "Airconditionor air circulation state";
CM_ SG_ 816 HVAC_PopUpDisplayReq "The Air Condition Information Pop-Up Display Request";
CM_ SG_ 816 HVAC_PopupDisplayReq2 "The Air condition information Pop-ip Display Requestï¼ˆtoastï¼‰";
CM_ SG_ 816 AQM_IonPopReq "Ion automatic open popup Request";
CM_ SG_ 816 HVAC_DriverTempSelect "The selected temperature of Driver side";
CM_ SG_ 816 AQM_IonMode "Ion mode";
CM_ SG_ 816 HVAC_WindExitSpd "The wind exit speed";
CM_ SG_ 816 HVAC_ECOSt "HVAC Eco/Normal  Mode";
CM_ SG_ 816 HVAC_WindExitSpdPercent "Front Wind Exit Spd Percent";
CM_ SG_ 816 HVAC_PTCPwrConsmp "PTC power consumption";
CM_ SG_ 816 HVAC_PsnTempSelect "The selected temperature of passenger side";
CM_ SG_ 816 HVAC_PTCWaterTempWarn "PTC Water Temp Warning";
CM_ SG_ 816 HVAC_ComfortCfgSt "Comfort curve configuration status";
CM_ SG_ 816 HVAC_AirCirCfgSt "Air circulation control mode when HVAC in auto mode configuration status";
CM_ SG_ 816 HVAC_PTCOutletTargetTemp "PTC Target Temperature";
CM_ SG_ 816 HVAC_AirQualitySenSt "Air quality sensitivity status";
CM_ SG_ 816 HVAC_FanspeedCfgSt "HVAC Fan speed of AUTO  mode configuration status";
CM_ SG_ 816 HVAC_SceneDisplayReq "Scene Button Display Request";
CM_ SG_ 816 HVAC_EvapratorSelfCleanSt "Evaprator Self Clean function configuration status";
CM_ SG_ 816 HVAC_SolarFeaturesCfgSt "Solar features configuration status";
CM_ SG_ 816 HVAC_CorrectedExterTemp "Corrected External temperature";
CM_ SG_ 816 HVAC_CorrectedExterTempVD "External temperature valid data";
CM_ SG_ 816 HVAC_DualCircuSt "HVACF inkate air dual circulation state";
CM_ SG_ 816 HVAC_CondDefSt "Condenser defrosting status";
CM_ SG_ 816 AQM_PM25CleanReq "PM2.5 Clean Req from the HVAC";
CM_ SG_ 816 AQM_FraganceRatioWarn "FRAG_Ratio_Warn";
CM_ SG_ 816 AQM_FraganceConcentrationReq "Fragance Concentration request";
CM_ SG_ 816 AQM_FragTasteRemanentRatio "BOX Remanent Ratio according to FraganceBoxID";
CM_ SG_ 816 AQM_FraganceTaste "Fragance Taste choose";
CM_ SG_ 816 AQM_FraganceConcentration "Fragance Concentration";
CM_ SG_ 816 AQM_FraganceBoxID "FraganceBoxID";
CM_ SG_ 816 AQM_FraganceTaste_Seek "Seek Requestï¼ŒRequest Frag return Remanent Ratio and taste ID according to this signal";
CM_ SG_ 816 AQM_FraganceBoxLoad "Indicate BOX load according to AQM_FraganceBoxID";
CM_ SG_ 816 HVAC_UnlockVentilationSt "Unlock Ventilation Status";
CM_ SG_ 816 AQM_PM25CirReq "Circulation change request";
CM_ SG_ 816 HVAC_ECPPwrConsump "ECP power consumption";
CM_ SG_ 288 PWL_LockAutoWinCloseFunCfgSt "Lock Auto Window Close Function Configuration Status";
CM_ SG_ 288 PWL_PowerWinOpenWarn "Power Window Open Warning";
CM_ SG_ 825 RLS_RainfallLevel "Rain level";
CM_ SG_ 825 RLS_RSErr "Error status rain sensor";
CM_ SG_ 825 RLS_LSErr "Error status light sensor";
CM_ SG_ 825 RLS_WiperSpd "Wiper speed mode";
CM_ SG_ 825 RLS_LampOnReqValid "Lamp On Request signal valid";
CM_ SG_ 825 RLS_LightOnReq "Switch on/off low beam request";
CM_ SG_ 825 SSW_RLSeatAutoModeCfgSt "Rear Left Seat Auto Mode Configuration State";
CM_ SG_ 825 SSW_RRSeatAutoModeCfgSt "Rear Right Seat Auto Mode Configuration State";
CM_ SG_ 825 SSW_FRSeatAutoModeCfgSt "Front Right Seat Auto Mode  Configration Status";
CM_ SG_ 825 SSW_FLSeatAutoModeCfgSt "Front Left Seat Auto Mode Configration Status";
CM_ SG_ 825 SSW_FLSeatHeatModeSt "Front Left Seat Heat Mode Status";
CM_ SG_ 825 MR_MirrorAutoFoldFuncCfgSt "Mirror Auto Fold Function Configuration Status";
CM_ SG_ 825 MR_MirrorAngleDipFuncCfgSt "Mirror Angle Dip  Function Configuration Status";
CM_ SG_ 825 SSW_EasyEntryExitFuncCfgSt "Easy Entry-Exit Function Configuration Status";
CM_ SG_ 825 SSW_SeatNapModePosSt "Seat Nap Mode Position Status";
CM_ SG_ 825 SSW_PosSaveRecallPopUpReq "Position Save Recall Pop-Up Request";
CM_ SG_ 825 SSW_SeatNapPopUpReq "Seat Nap Mode Pop-Up Request";
CM_ SG_ 825 SSW_FRSeatHeatModeSt "Front Right Seat Heating Mode Status";
CM_ SG_ 825 WW_FwpFaultSt "Front Wiper Fault state";
CM_ SG_ 825 WW_RwpFaultSt "Rear Wiper Fault state";
CM_ SG_ 825 WW_FwshFaultSt "Front Washer Fault state";
CM_ SG_ 825 WW_RwshFaultSt "Rear Washer Fault state";
CM_ SG_ 825 WW_FwpAutoModeSt "Front Wiper Auto Mode state";
CM_ SG_ 825 SSW_FRSeatVentSt "Front Right Seat Ventilation Status";
CM_ SG_ 825 SSW_SeatNapModeSt "Seat Nap Mode State";
CM_ SG_ 825 MR_LeftMirrorXCurrentPst "Left Mirror X Current Position Percentage ";
CM_ SG_ 825 MR_LeftMirrorYCurrentPst "Left Mirror Y Current Position Percentage ";
CM_ SG_ 825 MR_RightMirrorXCurrentPst "Right Mirror X Current  Position Percentage ";
CM_ SG_ 825 MR_RightMirrorYCurrentPst "Right Mirror Y Current  Position Percentage ";
CM_ SG_ 825 SSW_FLSeatSlideCurrentPst "Front Left Seat Slide Current  Position Percentage ";
CM_ SG_ 825 SSW_FLSeatHeightCurrentPst "Front Left Seat Height Current  Position Percentage ";
CM_ SG_ 825 SSW_FLSeatBackrestCurrentPst "Front Left Seat Backrest Current  Position Percentage ";
CM_ SG_ 825 SSW_FLSeatTiltCurrentPst "Front Left Seat Tilt Current Position Percentage ";
CM_ SG_ 825 SSW_SteeringAngleCurrentPst "Steering Angle Current  Position Percentage ";
CM_ SG_ 825 SSW_SteeringExtentCurrentPst "Steering Extent Current  Position Percentage ";
CM_ SG_ 825 SSW_PSCSOpeSt "Front Left Seat Control System Operation
State";
CM_ SG_ 825 WinVentilationReqExculFb "Window Ventilation Request Excult Feedback";
CM_ SG_ 825 SSW_FLSeatVentModeSt "Front Left Seat Ventilation  Mode Status";
CM_ SG_ 825 SSW_FRSeatHeatingSt "Front Right Seat Heating Status";
CM_ SG_ 825 SSW_FRSeatVentModeSt "Front Right Seat Ventilation Mode Status";
CM_ SG_ 825 SSW_FRSeatSlideCurrentPst "Front Right Seat Slide Current  Position Percentage ";
CM_ SG_ 825 SSW_FRSeatHeightCurrentPst "Front Right Seat Height Current  Position Percentage ";
CM_ SG_ 825 SSW_FRSeatBackrestCurrentPst "Front Right Seat Backrest Current  Position Percentage ";
CM_ SG_ 825 SSW_FRSeatTiltCurrentPst "Front Right Seat Tilt Current  Position Percentage ";
CM_ SG_ 825 SSW_FLSeatCushionCurrentPst "Front Left Seat Cushion Current  Position Percentage ";
CM_ SG_ 825 SSW_FRSeatCushionCurrentPst "Front Right Seat Cushion Current  Position Percentage ";
CM_ SG_ 825 SSW_FLSeatOttomanCurrentPst "Front Left Seat Ottoman Current  Position Percentage ";
CM_ SG_ 825 SSW_FRSeatOttomanCurrentPst "Front Right Seat Ottoman Current  Position Percentage ";
CM_ SG_ 825 PWL_FLWinCurrentPst "Front Left Window Current Position Percentage ";
CM_ SG_ 825 PWL_FRWinCurrentPst "Front Right Window Current Position Percentage ";
CM_ SG_ 825 PWL_RLWinCurrentPst "Rear Left Window Current Position Percentage ";
CM_ SG_ 825 PWL_RRWinCurrentPst "Rear Right Window Current Position Percentage ";
CM_ SG_ 825 PWL_FLWinCurrentOpeSt "Front Left Window Current Opeation Status";
CM_ SG_ 825 PWL_FRWinCurrentOpeSt "Front Right Window Current Opeation Status";
CM_ SG_ 825 PWL_RLWinCurrentOpeSt "Rear Left Window Current Opeation Status";
CM_ SG_ 825 PWL_RRWinCurrentOpeSt "Rear Right Window Current Opeation Status";
CM_ SG_ 825 WW_RainFallLevel "Rain Fall Level";
CM_ SG_ 825 WW_RLSWarning_Rain "Error state of Rain sensor";
CM_ SG_ 825 PLG_TravelPst "PLG travel position";
CM_ SG_ 825 PLG_SetPst "PLG Set Position";
CM_ SG_ 825 PLG_DoorSt "Power lift gate state";
CM_ SG_ 825 PLG_ModeSW "PLG mode switch state";
CM_ SG_ 291 WW_FWPInitAdjustSWPresent "Front Wiper interval level Adjust Switch Present";
CM_ SG_ 291 WW_RearCamWasherVRResp "Rear Camera Washer Request";
CM_ SG_ 291 WW_RearCamWasherVKResp "Rear Camera Washer Request";
CM_ SG_ 291 ATWS_ATWSAlarmReq "ATWS Alarm Request";
CM_ SG_ 291 ATWS_ATWSLEDIndCmd "ATWS LED indication Command";
CM_ SG_ 291 ATWS_ATWSSt "ATWS status";
CM_ SG_ 291 WW_FrontWiperServiceMode "indicate that whether Front Wiper under  Servie mode ";
CM_ SG_ 291 WW_RearWiperServiceMode "indicate that whether Rear Wiper under  Servie mode ";
CM_ SG_ 291 HRN_HornDoorLookAckEnable "Horn Door Locking acknowledge enable";
CM_ SG_ 291 HRN_HornVehAckEnable "Horn Vehicel search acknowledge enable";
CM_ SG_ 291 WW_FWPIntLevelSt "Front Wiper interval level";
CM_ SG_ 291 WW_FWPAutoLevelSt "Front Wiper RLS sensitivity level";
CM_ SG_ 291 WW_FrontAutoWiperEnable "Front Wiper Auto Enable status";
CM_ SG_ 291 WW_FrontWiperVRResp "Front wiper speech control response";
CM_ SG_ 291 WW_FrontWasherVRResp "Front washer speech control response";
CM_ SG_ 291 ATWS_ATWSAlarmHistory "ATWS Alarm History";
CM_ SG_ 291 WW_FrontWiperCtrlSt "Front wiper control status";
CM_ SG_ 291 WW_FrontAutoWiperPresent "Auto Front Wiper Equipped Status";
CM_ SG_ 291 WW_RearWiperCtrlSt "Rear wiper control status";
CM_ SG_ 291 WW_RearWiperPresent "Rear wiper Present or Absent";
CM_ SG_ 291 WW_RearWiperVRResp "Rear wiper speech control response";
CM_ SG_ 291 WW_RearWasherVRResp "Rear washer speech control response";
CM_ SG_ 291 WW_FrontWiperCtrlSrc "Front wiper control source";
CM_ SG_ 291 WW_RearWiperCtrlSrc "Rear wiper control source";
CM_ SG_ 865 EL_SideBrkLightCtrlCmd "Side brake light control command";
CM_ SG_ 865 EL_PositionLightCtrlSource "Position light control source";
CM_ SG_ 865 EL_HeadLightDelayEnable "Head light delay enable";
CM_ SG_ 865 EL_RLSWarning_Light "RLS auto light warning";
CM_ SG_ 865 EL_LampOnWarningReq "Lamp on warning request";
CM_ SG_ 865 IL_AutoDomeLightCfgSt "AutoDomeLightConfigurationState";
CM_ SG_ 865 EL_WelcomeLightMode "welcome light mode";
CM_ SG_ 865 EL_LightShowSt "light show mode ";
CM_ SG_ 865 EL_HeadLightLevelingSwSt "Head light leveling manul adjust switch status";
CM_ SG_ 865 EL_ALSEnable "Head light leveling auto adjust enble";
CM_ SG_ 865 EL_LeftTurnLightStForDisp "Left turn light status";
CM_ SG_ 865 EL_RightTurnLightStForDisp "Right turn light status";
CM_ SG_ 865 EL_PositionLightstForDisp "Position light status";
CM_ SG_ 865 EL_FrontFogLightStForDisp "Front fog light status";
CM_ SG_ 865 EL_RearFogLightStForDisp "Rear fog light status";
CM_ SG_ 865 EL_LowBeamStForDisp "Low beam status";
CM_ SG_ 865 EL_HighBeamStForDisp "High beam status";
CM_ SG_ 293 TPMS_FrontLeftTirePressure "FrontLeftTirePressure";
CM_ SG_ 293 TPMS_FrontRightTirePressure "FrontRightTirePressure";
CM_ SG_ 293 TPMS_RearRightTirePressure "RearRightTirePressure";
CM_ SG_ 293 TPMS_RearLeftTirePressure "RearLeftTirePressure";
CM_ SG_ 293 TPMS_FrontLeftTireTemperature "FrontLeftTireTemperature";
CM_ SG_ 293 TPMS_FrontRightTireTemperature "FrontRightTireTemperature";
CM_ SG_ 293 TPMS_RearRightTireTemperature "RearRightTireTemperature";
CM_ SG_ 293 TPMS_RearLeftTireTemperature "RearLeftTireTemperature";
CM_ SG_ 293 TPMS_FrontWheelRCP "FrontWheelRCP";
CM_ SG_ 293 TPMS_RearWheelRCP "RearWheelRCP";
CM_ SG_ 293 TPMS_FrontLeftTireLowPressure "FrontLeftTireLowPressure";
CM_ SG_ 293 TPMS_FrontRightTireLowPressure "FrontRightTireLowPressure";
CM_ SG_ 293 TPMS_RearRightTireLowPressure "RearRightTireLowPressure";
CM_ SG_ 293 TPMS_RearLeftTireLowPressure "RearLeftTireLowPressure";
CM_ SG_ 293 TPMS_FrontLeftTireHighPressure "FrontLeftTireHighPressure";
CM_ SG_ 293 TPMS_FrontRightTireHighPressure "FrontRightTireHighPressure";
CM_ SG_ 293 TPMS_RearRightTireHighPressure "RearRightTireHighPressure";
CM_ SG_ 293 TPMS_RearLeftTireHighPressure "RearLeftTireHighPressure";
CM_ SG_ 293 TPMS_FrontLeftTireDelaPressure "FrontLeftTireDelaPressure";
CM_ SG_ 293 TPMS_FrontRightTireDelaPressure "FrontRightTireDelaPressure";
CM_ SG_ 293 TPMS_RearRightTireDelaPressure "RearRightTireDelaPressure";
CM_ SG_ 293 TPMS_RearLeftTireDelaPressure "RearLeftTireDelaPressure";
CM_ SG_ 293 TPMS_FLTireHighTemperature "FrontLeftTireHighTemperature";
CM_ SG_ 293 TPMS_FRTireHighTemperature "FrontRightTireHighTemperature";
CM_ SG_ 293 TPMS_RRTireHighTemperature "RearRightTireHighTemperature";
CM_ SG_ 293 TPMS_RearLeftTireHighTemperature "RearLeftTireHighTemperature";
CM_ SG_ 293 TPMS_TireWarningLamp "TireWarningLamp";
CM_ SG_ 293 TPMS_FrontLeftSensorLowBattery "FrontLeftSensorLowBattery";
CM_ SG_ 293 TPMS_FrontRighSensorLowBattery "FrontRighSensorLowBattery";
CM_ SG_ 293 TPMS_RearRightSensorLowBattery "RearRightSensorLowBattery";
CM_ SG_ 293 TPMS_RearLeftSensorLowBattery "RearLeftSensorLowBattery";
CM_ SG_ 293 TPMS_FrontLeftSensorFailure "FrontLeftSensorFailure";
CM_ SG_ 293 TPMS_FrontRightSensorFailure "FrontRightSensorFailure";
CM_ SG_ 293 TPMS_RearRightSensorFailure "RearRightSensorFailure";
CM_ SG_ 293 TPMS_RearLeftSensorFailure "RearLeftSensorFailure";
CM_ SG_ 293 TPMS_FrontLeftSensorNotCalibrate "FrontLeftSensorNotCalibrate";
CM_ SG_ 293 TPMS_FRSensorNotCalibrate "FrontRightSensorNotCalibrate";
CM_ SG_ 293 TPMS_RearRightSensorNotCalibrate "RearRightSensorNotCalibrate";
CM_ SG_ 293 TPMS_RearLeftSensorNotCalibrate "RearLeftSensorNotCalibrate";
CM_ SG_ 293 TPMS_FrontLeftSensorMute "FrontLeftSensorMute";
CM_ SG_ 293 TPMS_FrontRightSensorMute "FrontRightSensorMute";
CM_ SG_ 293 TPMS_RearRightSensorMute "RearRightSensorMute";
CM_ SG_ 293 TPMS_RearLeftSensorMute "RearLeftSensorMute";
CM_ SG_ 293 TPMS_SystemWarningLamp "SystemWarningLamp";
CM_ SG_ 294 LCK_DriverDoorAjarSt "DriverDoorAjarST ";
CM_ SG_ 294 LCK_PassengerDoorAjarSt "PassengerDoorAjarST";
CM_ SG_ 294 LCK_DriverDoorLockSt "DriverDoorLockSt";
CM_ SG_ 294 LCK_PassengerDoorLockSt "PassengerDoorLockSt";
CM_ SG_ 294 LCK_VehicleDoorLockSt "VehicleDoorLockSt";
CM_ SG_ 294 LCK_VehicleChildSaftyLockSt "VehicleChildSaftyLockSt";
CM_ SG_ 294 LCK_VehicleChildSaftyLockedIndic "VehicleChildSaftyLockedIndicate";
CM_ SG_ 294 LCK_VehicleDoorLockedIndicate "VehicleDoorLockedIndicate";
CM_ SG_ 294 LCK_VehicleDoorUnlockedIndicate "VehicleDoorUnlockedIndicate";
CM_ SG_ 294 LCK_LockOverHeatInhibit "LockOverHeatInhibit";
CM_ SG_ 294 LCK_LockVehicleModeInhibit "LockVehicleModeInhibit";
CM_ SG_ 294 LCK_LockEmergencyInhibit "LockEmergencyInhibit";
CM_ SG_ 294 CCU_9_FreshnessValue "nan";
CM_ SG_ 294 CCU_9_MAC_Check "nan";
CM_ SG_ 909 KAE_BLEChl7Connectingst "BLE Device7 Connecting Status";
CM_ SG_ 909 LCK_FLPowerReleaseFailedRemind "FrontLeftPowerReleaseFailedRemind";
CM_ SG_ 909 LCK_FRPowerReleaseFailedRemind "FrontLeftPowerReleaseFailedRemind";
CM_ SG_ 909 LCK_RLPowerReleaseFailedRemind "FrontLeftPowerReleaseFailedRemind";
CM_ SG_ 909 LCK_RRPowerReleaseFailedRemind "FrontLeftPowerReleaseFailedRemind";
CM_ SG_ 909 LCK_HoodAjarSt "HoodAjarSt";
CM_ SG_ 909 LCK_FrontLeftDoorAjarSt "FrontLeftDoorAjarSt";
CM_ SG_ 909 LCK_FrontRightDoorAjarSt "FrontRightDoorAjarSt";
CM_ SG_ 909 LCK_RearLeftDoorAjarSt "RearLeftDoorAjarSt";
CM_ SG_ 909 LCK_RearRightDoorAjarSt "RearRightDoorAjarSt";
CM_ SG_ 909 LCK_TrunkAjarSt "TrunkAjarSt";
CM_ SG_ 909 LCK_FrontLeftDoorLockSt "FrontLeftDoorLockSt";
CM_ SG_ 909 LCK_FrontRightDoorLockSt "FrontRightDoorLockSt";
CM_ SG_ 909 LCK_RearLeftDoorLockSt "RearLeftDoorLockSt";
CM_ SG_ 909 LCK_RearRightDoorLockSt "RearRightDoorLockSt";
CM_ SG_ 909 LCK_RearLeftChildSaftyLockSt "RearLeftChildSaftyLockSt";
CM_ SG_ 909 LCK_RearRightChildSaftyLockSt "RearRightChildSaftyLockSt";
CM_ SG_ 909 LCK_FrontLeftDoorHandlePosition "FrontLeftDoorHandlePosition";
CM_ SG_ 909 LCK_FrontRightDoorHandlePosition "FrontRightDoorHandlePosition";
CM_ SG_ 909 LCK_RearLeftDoorHandlePosition "RearLeftDoorHandlePosition";
CM_ SG_ 909 LCK_RearRightDoorHandlePosition "RearRightDoorHandlePosition";
BA_DEF_ BO_  "E2EProfile" STRING ;
BA_DEF_ BO_  "E2EDataLength" INT 0 65535;
BA_DEF_ BO_  "E2EDataId" INT 0 65535;
BA_DEF_ SG_  "Remark" STRING ;
BA_DEF_ SG_  "EventCommandSignal" ENUM  "No","Yes";
BA_DEF_ SG_  "GatewayedSignals" ENUM  "No","Yes";
BA_DEF_ SG_  "GenSigTimeoutValue" HEX 0 0;
BA_DEF_ SG_  "GenSigStartValue" HEX 0 0;
BA_DEF_ SG_  "GenSigInvalidValue" HEX 0 0;
BA_DEF_ SG_  "GenSigInactiveValue" HEX 0 0;
BA_DEF_ SG_  "GenSigSendType" ENUM  "Trigger","Passive","Cyclic","OnWrite","OnWriteWithRepetition","OnChange","OnChangeWithRepetition","IfActive","IfActiveWithRepetition","NoSigSendType";
BA_DEF_ BO_  "GenMsgCycleTimeFast" INT 0 0;
BA_DEF_ BO_  "GenMsgCycleTime" INT 0 0;
BA_DEF_ BO_  "GenMsgSendType" ENUM  "Periodic","Event","IfActive","POE","PA","FixedPeriodic","Event","EnabledPeriodic","NotUsed","NotUsed","EventPeriodic","NotUsed","NotUsed","NoMsgSendType";
BA_DEF_ BO_  "VFrameFormat" ENUM  "StandardCAN","ExtendedCAN","reserved","reserved","reserved","reserved","reserved","reserved","reserved","reserved","reserved","reserved","reserved","reserved","StandardCAN_FD","ExtendedCAN_FD";
BA_DEF_ BO_  "CANFD_BRS" ENUM  "0","1";
BA_DEF_ SG_  "SystemSignalLongSymbol" STRING ;
BA_DEF_DEF_  "E2EProfile" "";
BA_DEF_DEF_  "E2EDataLength" 0;
BA_DEF_DEF_  "E2EDataId" 0;
BA_DEF_DEF_  "Remark" "";
BA_DEF_DEF_  "EventCommandSignal" "";
BA_DEF_DEF_  "GatewayedSignals" "";
BA_DEF_DEF_  "GenSigTimeoutValue" 0;
BA_DEF_DEF_  "GenSigStartValue" 0;
BA_DEF_DEF_  "GenSigInvalidValue" 0;
BA_DEF_DEF_  "GenSigInactiveValue" 0;
BA_DEF_DEF_  "GenSigSendType" "";
BA_DEF_DEF_  "GenMsgCycleTimeFast" 0;
BA_DEF_DEF_  "GenMsgCycleTime" 0;
BA_DEF_DEF_  "GenMsgSendType" "";
BA_DEF_DEF_  "VFrameFormat" "";
BA_DEF_DEF_  "CANFD_BRS" "";
BA_DEF_DEF_  "SystemSignalLongSymbol" "";
BA_ "CANFD_BRS" BO_ 475 1;
BA_ "GenMsgCycleTime" BO_ 475 1000;
BA_ "GenMsgCycleTimeFast" BO_ 475 40;
BA_ "GenMsgSendType" BO_ 475 4;
BA_ "E2EProfile" BO_ 475 "P05";
BA_ "E2EDataLength" BO_ 475 512;
BA_ "E2EDataId" BO_ 475 1797;
BA_ "VFrameFormat" BO_ 475 14;
BA_ "E2EProfile" BO_ 967 "P05";
BA_ "E2EDataLength" BO_ 967 512;
BA_ "E2EDataId" BO_ 967 1795;
BA_ "CANFD_BRS" BO_ 967 1;
BA_ "GenMsgCycleTime" BO_ 967 200;
BA_ "GenMsgSendType" BO_ 967 0;
BA_ "VFrameFormat" BO_ 967 14;
BA_ "CANFD_BRS" BO_ 1963 1;
BA_ "GenMsgSendType" BO_ 1963 1;
BA_ "VFrameFormat" BO_ 1963 14;
BA_ "CANFD_BRS" BO_ 1323 1;
BA_ "GenMsgCycleTime" BO_ 1323 200;
BA_ "GenMsgSendType" BO_ 1323 0;
BA_ "VFrameFormat" BO_ 1323 14;
BA_ "CANFD_BRS" BO_ 169 1;
BA_ "GenMsgSendType" BO_ 169 1;
BA_ "VFrameFormat" BO_ 169 14;
BA_ "CANFD_BRS" BO_ 157 1;
BA_ "GenMsgSendType" BO_ 157 1;
BA_ "VFrameFormat" BO_ 157 14;
BA_ "CANFD_BRS" BO_ 122 1;
BA_ "GenMsgSendType" BO_ 122 1;
BA_ "VFrameFormat" BO_ 122 14;
BA_ "CANFD_BRS" BO_ 624 1;
BA_ "GenMsgCycleTime" BO_ 624 20;
BA_ "GenMsgSendType" BO_ 624 0;
BA_ "VFrameFormat" BO_ 624 14;
BA_ "CANFD_BRS" BO_ 777 1;
BA_ "GenMsgCycleTime" BO_ 777 100;
BA_ "GenMsgSendType" BO_ 777 0;
BA_ "VFrameFormat" BO_ 777 14;
BA_ "CANFD_BRS" BO_ 786 1;
BA_ "GenMsgCycleTime" BO_ 786 100;
BA_ "GenMsgSendType" BO_ 786 0;
BA_ "VFrameFormat" BO_ 786 14;
BA_ "CANFD_BRS" BO_ 342 1;
BA_ "GenMsgCycleTime" BO_ 342 500;
BA_ "GenMsgCycleTimeFast" BO_ 342 40;
BA_ "GenMsgSendType" BO_ 342 3;
BA_ "VFrameFormat" BO_ 342 14;
BA_ "CANFD_BRS" BO_ 632 1;
BA_ "GenMsgCycleTime" BO_ 632 100;
BA_ "GenMsgSendType" BO_ 632 0;
BA_ "VFrameFormat" BO_ 632 14;
BA_ "CANFD_BRS" BO_ 776 1;
BA_ "GenMsgCycleTime" BO_ 776 100;
BA_ "GenMsgSendType" BO_ 776 0;
BA_ "VFrameFormat" BO_ 776 14;
BA_ "CANFD_BRS" BO_ 791 1;
BA_ "GenMsgCycleTime" BO_ 791 100;
BA_ "GenMsgSendType" BO_ 791 0;
BA_ "VFrameFormat" BO_ 791 14;
BA_ "CANFD_BRS" BO_ 792 1;
BA_ "GenMsgCycleTime" BO_ 792 100;
BA_ "GenMsgSendType" BO_ 792 0;
BA_ "VFrameFormat" BO_ 792 14;
BA_ "E2EProfile" BO_ 616 "P05";
BA_ "E2EDataLength" BO_ 616 448;
BA_ "E2EDataId" BO_ 616 282;
BA_ "CANFD_BRS" BO_ 616 1;
BA_ "GenMsgCycleTime" BO_ 616 20;
BA_ "GenMsgSendType" BO_ 616 0;
BA_ "VFrameFormat" BO_ 616 14;
BA_ "CANFD_BRS" BO_ 816 1;
BA_ "GenMsgCycleTime" BO_ 816 100;
BA_ "GenMsgSendType" BO_ 816 0;
BA_ "VFrameFormat" BO_ 816 14;
BA_ "CANFD_BRS" BO_ 288 1;
BA_ "GenMsgCycleTime" BO_ 288 500;
BA_ "GenMsgCycleTimeFast" BO_ 288 40;
BA_ "GenMsgSendType" BO_ 288 3;
BA_ "VFrameFormat" BO_ 288 14;
BA_ "CANFD_BRS" BO_ 825 1;
BA_ "GenMsgCycleTime" BO_ 825 100;
BA_ "GenMsgSendType" BO_ 825 0;
BA_ "VFrameFormat" BO_ 825 14;
BA_ "CANFD_BRS" BO_ 291 1;
BA_ "GenMsgCycleTime" BO_ 291 500;
BA_ "GenMsgCycleTimeFast" BO_ 291 40;
BA_ "GenMsgSendType" BO_ 291 3;
BA_ "VFrameFormat" BO_ 291 14;
BA_ "CANFD_BRS" BO_ 865 1;
BA_ "GenMsgCycleTime" BO_ 865 40;
BA_ "GenMsgSendType" BO_ 865 0;
BA_ "VFrameFormat" BO_ 865 14;
BA_ "CANFD_BRS" BO_ 293 1;
BA_ "GenMsgCycleTime" BO_ 293 500;
BA_ "GenMsgCycleTimeFast" BO_ 293 40;
BA_ "GenMsgSendType" BO_ 293 3;
BA_ "VFrameFormat" BO_ 293 14;
BA_ "CANFD_BRS" BO_ 294 1;
BA_ "GenMsgCycleTime" BO_ 294 500;
BA_ "GenMsgCycleTimeFast" BO_ 294 40;
BA_ "GenMsgSendType" BO_ 294 3;
BA_ "VFrameFormat" BO_ 294 14;
BA_ "CANFD_BRS" BO_ 909 1;
BA_ "GenMsgCycleTime" BO_ 909 100;
BA_ "GenMsgSendType" BO_ 909 0;
BA_ "VFrameFormat" BO_ 909 14;
BA_ "GenSigSendType" SG_ 475 Reserved1 0;
BA_ "GatewayedSignals" SG_ 475 Reserved1 0;
BA_ "EventCommandSignal" SG_ 475 Reserved1 0;
BA_ "Remark" SG_ 475 Reserved1 "<E2E_Group1>";
BA_ "GenSigSendType" SG_ 475 ACU_FRSeatOttomanExtentPosCtlReq 0;
BA_ "GenSigStartValue" SG_ 475 ACU_FRSeatOttomanExtentPosCtlReq 255;
BA_ "GatewayedSignals" SG_ 475 ACU_FRSeatOttomanExtentPosCtlReq 0;
BA_ "EventCommandSignal" SG_ 475 ACU_FRSeatOttomanExtentPosCtlReq 1;
BA_ "Remark" SG_ 475 ACU_FRSeatOttomanExtentPosCtlReq "<E2E_Group1>";
BA_ "GenSigInactiveValue" SG_ 475 ACU_FRSeatOttomanExtentPosCtlReq 255;
BA_ "GenSigSendType" SG_ 475 ACU_FRSeatOttomanAnglePosCtlReq 0;
BA_ "GenSigStartValue" SG_ 475 ACU_FRSeatOttomanAnglePosCtlReq 255;
BA_ "GatewayedSignals" SG_ 475 ACU_FRSeatOttomanAnglePosCtlReq 0;
BA_ "EventCommandSignal" SG_ 475 ACU_FRSeatOttomanAnglePosCtlReq 1;
BA_ "Remark" SG_ 475 ACU_FRSeatOttomanAnglePosCtlReq "<E2E_Group1>";
BA_ "GenSigInactiveValue" SG_ 475 ACU_FRSeatOttomanAnglePosCtlReq 255;
BA_ "GenSigSendType" SG_ 475 ACU_FLSeatOttomanExtentPosCtlReq 0;
BA_ "GenSigStartValue" SG_ 475 ACU_FLSeatOttomanExtentPosCtlReq 255;
BA_ "GatewayedSignals" SG_ 475 ACU_FLSeatOttomanExtentPosCtlReq 0;
BA_ "EventCommandSignal" SG_ 475 ACU_FLSeatOttomanExtentPosCtlReq 1;
BA_ "Remark" SG_ 475 ACU_FLSeatOttomanExtentPosCtlReq "<E2E_Group1>";
BA_ "GenSigInactiveValue" SG_ 475 ACU_FLSeatOttomanExtentPosCtlReq 255;
BA_ "GenSigSendType" SG_ 475 ACU_FLSeatOttomanAnglePosCtlReq 0;
BA_ "GenSigStartValue" SG_ 475 ACU_FLSeatOttomanAnglePosCtlReq 255;
BA_ "GatewayedSignals" SG_ 475 ACU_FLSeatOttomanAnglePosCtlReq 0;
BA_ "EventCommandSignal" SG_ 475 ACU_FLSeatOttomanAnglePosCtlReq 1;
BA_ "Remark" SG_ 475 ACU_FLSeatOttomanAnglePosCtlReq "<E2E_Group1>";
BA_ "GenSigInactiveValue" SG_ 475 ACU_FLSeatOttomanAnglePosCtlReq 255;
BA_ "GenSigSendType" SG_ 475 IDC_4_Counter 1;
BA_ "GatewayedSignals" SG_ 475 IDC_4_Counter 0;
BA_ "EventCommandSignal" SG_ 475 IDC_4_Counter 0;
BA_ "Remark" SG_ 475 IDC_4_Counter "<E2E_Group1>";
BA_ "GenSigSendType" SG_ 475 IDC_4_CRC 1;
BA_ "GatewayedSignals" SG_ 475 IDC_4_CRC 0;
BA_ "EventCommandSignal" SG_ 475 IDC_4_CRC 0;
BA_ "Remark" SG_ 475 IDC_4_CRC "<E2E_Group1>";
BA_ "GenSigSendType" SG_ 475 ACU_HVACFR_OffOnBtnSt 0;
BA_ "EventCommandSignal" SG_ 475 ACU_HVACFR_OffOnBtnSt 1;
BA_ "GenSigSendType" SG_ 475 ACU_HVACFR_AutoModeBtnSt 0;
BA_ "EventCommandSignal" SG_ 475 ACU_HVACFR_AutoModeBtnSt 1;
BA_ "GenSigSendType" SG_ 475 ACU_HVACFR_ModeBtnSt 0;
BA_ "EventCommandSignal" SG_ 475 ACU_HVACFR_ModeBtnSt 1;
BA_ "GenSigSendType" SG_ 475 ACU_HVACF_FDefrostBtnSt 0;
BA_ "EventCommandSignal" SG_ 475 ACU_HVACF_FDefrostBtnSt 1;
BA_ "GenSigSendType" SG_ 475 ACU_HVACF_RDefrostBtnSt 0;
BA_ "EventCommandSignal" SG_ 475 ACU_HVACF_RDefrostBtnSt 1;
BA_ "GenSigSendType" SG_ 475 ACU_HVACF_DualSyncBtnSt 0;
BA_ "EventCommandSignal" SG_ 475 ACU_HVACF_DualSyncBtnSt 1;
BA_ "GenSigSendType" SG_ 475 ACU_HVACF_IonBtnSt 0;
BA_ "EventCommandSignal" SG_ 475 ACU_HVACF_IonBtnSt 1;
BA_ "GenSigSendType" SG_ 475 ACU_HVACFR_FanIncBtnSt 0;
BA_ "EventCommandSignal" SG_ 475 ACU_HVACFR_FanIncBtnSt 1;
BA_ "GenSigSendType" SG_ 475 ACU_HVACFR_FanDecBtnSt 0;
BA_ "EventCommandSignal" SG_ 475 ACU_HVACFR_FanDecBtnSt 1;
BA_ "GenSigSendType" SG_ 475 ACU_HVACF_CirBtnSt 0;
BA_ "EventCommandSignal" SG_ 475 ACU_HVACF_CirBtnSt 1;
BA_ "GenSigSendType" SG_ 475 ACU_HVACF_ACBtnSt 0;
BA_ "EventCommandSignal" SG_ 475 ACU_HVACF_ACBtnSt 1;
BA_ "GenSigSendType" SG_ 475 ACU_HVACF_ACMaxBtnSt 0;
BA_ "EventCommandSignal" SG_ 475 ACU_HVACF_ACMaxBtnSt 1;
BA_ "GenSigSendType" SG_ 475 ACU_HVACF_FLTempIncBtnSt 0;
BA_ "EventCommandSignal" SG_ 475 ACU_HVACF_FLTempIncBtnSt 1;
BA_ "GenSigSendType" SG_ 475 ACU_HVACF_FLTempDecBtnSt 0;
BA_ "EventCommandSignal" SG_ 475 ACU_HVACF_FLTempDecBtnSt 1;
BA_ "GenSigSendType" SG_ 475 ACU_HVACF_FRTempIncBtnSt 0;
BA_ "EventCommandSignal" SG_ 475 ACU_HVACF_FRTempIncBtnSt 1;
BA_ "GenSigSendType" SG_ 475 ACU_HVACF_FRTempDecBtnSt 0;
BA_ "EventCommandSignal" SG_ 475 ACU_HVACF_FRTempDecBtnSt 1;
BA_ "GenSigSendType" SG_ 475 ACU_HVACF_ECOBtnSt 0;
BA_ "EventCommandSignal" SG_ 475 ACU_HVACF_ECOBtnSt 1;
BA_ "GenSigSendType" SG_ 475 ACU_HVAC_RearOnOffBtnSt 0;
BA_ "EventCommandSignal" SG_ 475 ACU_HVAC_RearOnOffBtnSt 1;
BA_ "GenSigSendType" SG_ 475 ACU_HVAC_RearAutoModeBtnSt 0;
BA_ "EventCommandSignal" SG_ 475 ACU_HVAC_RearAutoModeBtnSt 1;
BA_ "GenSigInactiveValue" SG_ 475 ACU_LeftMirrorXPosCtlReq 255;
BA_ "GenSigStartValue" SG_ 475 ACU_LeftMirrorXPosCtlReq 255;
BA_ "GenSigSendType" SG_ 475 ACU_LeftMirrorXPosCtlReq 0;
BA_ "EventCommandSignal" SG_ 475 ACU_LeftMirrorXPosCtlReq 1;
BA_ "GenSigInactiveValue" SG_ 475 ACU_LeftMirrorYPosCtlReq 255;
BA_ "GenSigStartValue" SG_ 475 ACU_LeftMirrorYPosCtlReq 255;
BA_ "GenSigSendType" SG_ 475 ACU_LeftMirrorYPosCtlReq 0;
BA_ "EventCommandSignal" SG_ 475 ACU_LeftMirrorYPosCtlReq 1;
BA_ "GenSigInactiveValue" SG_ 475 ACU_RightMirrorXPosCtlReq 255;
BA_ "GenSigStartValue" SG_ 475 ACU_RightMirrorXPosCtlReq 255;
BA_ "GenSigSendType" SG_ 475 ACU_RightMirrorXPosCtlReq 0;
BA_ "EventCommandSignal" SG_ 475 ACU_RightMirrorXPosCtlReq 1;
BA_ "GenSigInactiveValue" SG_ 475 ACU_RightMirrorYPosCtlReq 255;
BA_ "GenSigStartValue" SG_ 475 ACU_RightMirrorYPosCtlReq 255;
BA_ "GenSigSendType" SG_ 475 ACU_RightMirrorYPosCtlReq 0;
BA_ "EventCommandSignal" SG_ 475 ACU_RightMirrorYPosCtlReq 1;
BA_ "GenSigInactiveValue" SG_ 475 ACU_FLSeatSlidePosCtlReq 255;
BA_ "GenSigStartValue" SG_ 475 ACU_FLSeatSlidePosCtlReq 255;
BA_ "GenSigSendType" SG_ 475 ACU_FLSeatSlidePosCtlReq 0;
BA_ "EventCommandSignal" SG_ 475 ACU_FLSeatSlidePosCtlReq 1;
BA_ "GenSigInactiveValue" SG_ 475 ACU_FLSeatHeightPosCtlReq 255;
BA_ "GenSigStartValue" SG_ 475 ACU_FLSeatHeightPosCtlReq 255;
BA_ "GenSigSendType" SG_ 475 ACU_FLSeatHeightPosCtlReq 0;
BA_ "EventCommandSignal" SG_ 475 ACU_FLSeatHeightPosCtlReq 1;
BA_ "GenSigInactiveValue" SG_ 475 ACU_FLSeatBackrestPosCtlReq 255;
BA_ "GenSigStartValue" SG_ 475 ACU_FLSeatBackrestPosCtlReq 255;
BA_ "GenSigSendType" SG_ 475 ACU_FLSeatBackrestPosCtlReq 0;
BA_ "EventCommandSignal" SG_ 475 ACU_FLSeatBackrestPosCtlReq 1;
BA_ "GenSigInactiveValue" SG_ 475 ACU_FLSeatTiltPosCtlReq 255;
BA_ "GenSigStartValue" SG_ 475 ACU_FLSeatTiltPosCtlReq 255;
BA_ "GenSigSendType" SG_ 475 ACU_FLSeatTiltPosCtlReq 0;
BA_ "EventCommandSignal" SG_ 475 ACU_FLSeatTiltPosCtlReq 1;
BA_ "GenSigInactiveValue" SG_ 475 ACU_SteeringAnglePosCtlReq 255;
BA_ "GenSigStartValue" SG_ 475 ACU_SteeringAnglePosCtlReq 255;
BA_ "EventCommandSignal" SG_ 475 ACU_SteeringAnglePosCtlReq 1;
BA_ "GenSigInactiveValue" SG_ 475 ACU_SteeringExtentPosCtlReq 255;
BA_ "GenSigStartValue" SG_ 475 ACU_SteeringExtentPosCtlReq 255;
BA_ "GenSigSendType" SG_ 475 ACU_SteeringExtentPosCtlReq 0;
BA_ "EventCommandSignal" SG_ 475 ACU_SteeringExtentPosCtlReq 1;
BA_ "GenSigInactiveValue" SG_ 475 ACU_FRSeatSlidePosCtlReq 255;
BA_ "GenSigStartValue" SG_ 475 ACU_FRSeatSlidePosCtlReq 255;
BA_ "GenSigSendType" SG_ 475 ACU_FRSeatSlidePosCtlReq 0;
BA_ "EventCommandSignal" SG_ 475 ACU_FRSeatSlidePosCtlReq 1;
BA_ "GenSigInactiveValue" SG_ 475 ACU_FRSeatHeightPosCtlReq 255;
BA_ "GenSigStartValue" SG_ 475 ACU_FRSeatHeightPosCtlReq 255;
BA_ "GenSigSendType" SG_ 475 ACU_FRSeatHeightPosCtlReq 0;
BA_ "EventCommandSignal" SG_ 475 ACU_FRSeatHeightPosCtlReq 1;
BA_ "GenSigStartValue" SG_ 475 ACU_FRSeatBackrestPosCtlReq 255;
BA_ "GenSigSendType" SG_ 475 ACU_FRSeatBackrestPosCtlReq 0;
BA_ "EventCommandSignal" SG_ 475 ACU_FRSeatBackrestPosCtlReq 1;
BA_ "GenSigInactiveValue" SG_ 475 ACU_FRSeatBackrestPosCtlReq 255;
BA_ "GenSigStartValue" SG_ 475 ACU_FRSeatTiltPosCtlReq 255;
BA_ "GenSigSendType" SG_ 475 ACU_FRSeatTiltPosCtlReq 0;
BA_ "EventCommandSignal" SG_ 475 ACU_FRSeatTiltPosCtlReq 1;
BA_ "GenSigInactiveValue" SG_ 475 ACU_FRSeatTiltPosCtlReq 255;
BA_ "GenSigStartValue" SG_ 475 ACU_FLSeatCushionPosCtlReq 255;
BA_ "GenSigSendType" SG_ 475 ACU_FLSeatCushionPosCtlReq 0;
BA_ "EventCommandSignal" SG_ 475 ACU_FLSeatCushionPosCtlReq 1;
BA_ "GenSigInactiveValue" SG_ 475 ACU_FLSeatCushionPosCtlReq 255;
BA_ "GenSigStartValue" SG_ 475 ACU_FRSeatCushionPosCtlReq 255;
BA_ "GenSigSendType" SG_ 475 ACU_FRSeatCushionPosCtlReq 0;
BA_ "EventCommandSignal" SG_ 475 ACU_FRSeatCushionPosCtlReq 1;
BA_ "GenSigInactiveValue" SG_ 475 ACU_FRSeatCushionPosCtlReq 255;
BA_ "GenSigStartValue" SG_ 475 ACU_FLSeatOttomanPosCtlReq 255;
BA_ "GenSigSendType" SG_ 475 ACU_FLSeatOttomanPosCtlReq 0;
BA_ "EventCommandSignal" SG_ 475 ACU_FLSeatOttomanPosCtlReq 1;
BA_ "GenSigInactiveValue" SG_ 475 ACU_FLSeatOttomanPosCtlReq 255;
BA_ "GenSigStartValue" SG_ 475 ACU_FRSeatOttomanPosCtlReq 255;
BA_ "GenSigSendType" SG_ 475 ACU_FRSeatOttomanPosCtlReq 0;
BA_ "EventCommandSignal" SG_ 475 ACU_FRSeatOttomanPosCtlReq 1;
BA_ "GenSigInactiveValue" SG_ 475 ACU_FRSeatOttomanPosCtlReq 255;
BA_ "GenSigSendType" SG_ 967 DMS_YawnSt 1;
BA_ "GatewayedSignals" SG_ 967 DMS_YawnSt 0;
BA_ "EventCommandSignal" SG_ 967 DMS_YawnSt 0;
BA_ "EventCommandSignal" SG_ 967 DMS_SeatBeltRigntrearStatus 0;
BA_ "GenSigSendType" SG_ 967 DMS_SeatBeltRigntrearStatus 1;
BA_ "EventCommandSignal" SG_ 967 DMS_SeatBeltMidrearStatus 0;
BA_ "GenSigSendType" SG_ 967 DMS_SeatBeltMidrearStatus 1;
BA_ "GatewayedSignals" SG_ 967 DMS_SeatBeltLeftrearStatus 0;
BA_ "GenSigSendType" SG_ 967 DMS_SeatBeltLeftrearStatus 1;
BA_ "EventCommandSignal" SG_ 967 DMS_SeatBeltCodriverStatus 0;
BA_ "GenSigSendType" SG_ 967 DMS_SeatBeltCodriverStatus 1;
BA_ "EventCommandSignal" SG_ 967 DMS_SeatBeltDriverStatus 0;
BA_ "GenSigSendType" SG_ 967 DMS_SeatBeltDriverStatus 1;
BA_ "EventCommandSignal" SG_ 967 DMS_MidrearChild 0;
BA_ "GenSigSendType" SG_ 967 DMS_MidrearChild 1;
BA_ "EventCommandSignal" SG_ 967 DMS_RigntrearChild 0;
BA_ "GenSigSendType" SG_ 967 DMS_RigntrearChild 1;
BA_ "EventCommandSignal" SG_ 967 DMS_LeftrearChild 0;
BA_ "GenSigSendType" SG_ 967 DMS_LeftrearChild 1;
BA_ "EventCommandSignal" SG_ 967 DMS_CodriverChild 0;
BA_ "GenSigSendType" SG_ 967 DMS_CodriverChild 1;
BA_ "EventCommandSignal" SG_ 967 DMS_MidrearThumbleftgestures 0;
BA_ "GenSigSendType" SG_ 967 DMS_MidrearThumbleftgestures 1;
BA_ "EventCommandSignal" SG_ 967 DMS_RigntrearThumbleftgestures 0;
BA_ "GenSigSendType" SG_ 967 DMS_RigntrearThumbleftgestures 1;
BA_ "EventCommandSignal" SG_ 967 DMS_LeftrearThumbleftgestures 0;
BA_ "GenSigSendType" SG_ 967 DMS_LeftrearThumbleftgestures 1;
BA_ "EventCommandSignal" SG_ 967 DMS_CodriverThumbleftgestures 0;
BA_ "GenSigSendType" SG_ 967 DMS_CodriverThumbleftgestures 1;
BA_ "EventCommandSignal" SG_ 967 DMS_DriverThumbleftgestures 0;
BA_ "GenSigSendType" SG_ 967 DMS_DriverThumbleftgestures 1;
BA_ "EventCommandSignal" SG_ 967 DMS_MidrearThumbrightgestures 0;
BA_ "GenSigSendType" SG_ 967 DMS_MidrearThumbrightgestures 1;
BA_ "EventCommandSignal" SG_ 967 DMS_RigntrearThumbrightgestures 0;
BA_ "GenSigSendType" SG_ 967 DMS_RigntrearThumbrightgestures 1;
BA_ "EventCommandSignal" SG_ 967 DMS_LeftrearThumbrightgestures 0;
BA_ "GenSigSendType" SG_ 967 DMS_LeftrearThumbrightgestures 1;
BA_ "EventCommandSignal" SG_ 967 DMS_CodriverThumbrightgestures 0;
BA_ "GenSigSendType" SG_ 967 DMS_CodriverThumbrightgestures 1;
BA_ "EventCommandSignal" SG_ 967 DMS_DriverThumbrightgestures 0;
BA_ "GenSigSendType" SG_ 967 DMS_DriverThumbrightgestures 1;
BA_ "EventCommandSignal" SG_ 967 DMS_MidrearThumbdowngestures 0;
BA_ "GenSigSendType" SG_ 967 DMS_MidrearThumbdowngestures 1;
BA_ "EventCommandSignal" SG_ 967 DMS_RigntrearThumbdowngestures 0;
BA_ "GenSigSendType" SG_ 967 DMS_RigntrearThumbdowngestures 1;
BA_ "EventCommandSignal" SG_ 967 DMS_LeftrearThumbdowngestures 0;
BA_ "GenSigSendType" SG_ 967 DMS_LeftrearThumbdowngestures 1;
BA_ "EventCommandSignal" SG_ 967 DMS_CodriverThumbdowngestures 0;
BA_ "GenSigSendType" SG_ 967 DMS_CodriverThumbdowngestures 1;
BA_ "EventCommandSignal" SG_ 967 DMS_DriverThumbdowngestures 0;
BA_ "GenSigSendType" SG_ 967 DMS_DriverThumbdowngestures 1;
BA_ "EventCommandSignal" SG_ 967 DMS_MidrearThumbupgestures 0;
BA_ "GenSigSendType" SG_ 967 DMS_MidrearThumbupgestures 1;
BA_ "EventCommandSignal" SG_ 967 DMS_RigntrearThumbupgestures 0;
BA_ "GenSigSendType" SG_ 967 DMS_RigntrearThumbupgestures 1;
BA_ "EventCommandSignal" SG_ 967 DMS_LeftrearThumbupgestures 0;
BA_ "GenSigSendType" SG_ 967 DMS_LeftrearThumbupgestures 1;
BA_ "EventCommandSignal" SG_ 967 DMS_CodriverThumbupgestures 0;
BA_ "GenSigSendType" SG_ 967 DMS_CodriverThumbupgestures 1;
BA_ "EventCommandSignal" SG_ 967 DMS_DriverThumbupgestures 0;
BA_ "GenSigSendType" SG_ 967 DMS_DriverThumbupgestures 1;
BA_ "EventCommandSignal" SG_ 967 DMS_MidrearPapergesture 0;
BA_ "GenSigSendType" SG_ 967 DMS_MidrearPapergesture 1;
BA_ "EventCommandSignal" SG_ 967 DMS_RigntrearPapergesture 0;
BA_ "GenSigSendType" SG_ 967 DMS_RigntrearPapergesture 1;
BA_ "EventCommandSignal" SG_ 967 DMS_LeftrearPapergesture 0;
BA_ "GenSigSendType" SG_ 967 DMS_LeftrearPapergesture 1;
BA_ "EventCommandSignal" SG_ 967 DMS_CodriverPapergesture 0;
BA_ "GenSigSendType" SG_ 967 DMS_CodriverPapergesture 1;
BA_ "EventCommandSignal" SG_ 967 DMS_DriverPapergesture 0;
BA_ "GenSigSendType" SG_ 967 DMS_DriverPapergesture 1;
BA_ "EventCommandSignal" SG_ 967 DMS_MidrearScissorsgesture 0;
BA_ "GenSigSendType" SG_ 967 DMS_MidrearScissorsgesture 1;
BA_ "EventCommandSignal" SG_ 967 DMS_RigntrearScissorsgesture 0;
BA_ "GenSigSendType" SG_ 967 DMS_RigntrearScissorsgesture 1;
BA_ "EventCommandSignal" SG_ 967 DMS_LeftrearScissorsgesture 0;
BA_ "GenSigSendType" SG_ 967 DMS_LeftrearScissorsgesture 1;
BA_ "EventCommandSignal" SG_ 967 DMS_CodriverScissorsgesture 0;
BA_ "GenSigSendType" SG_ 967 DMS_CodriverScissorsgesture 1;
BA_ "EventCommandSignal" SG_ 967 DMS_DriverScissorsgesture 0;
BA_ "GenSigSendType" SG_ 967 DMS_DriverScissorsgesture 1;
BA_ "EventCommandSignal" SG_ 967 DMS_MidrearRockgesture 0;
BA_ "GenSigSendType" SG_ 967 DMS_MidrearRockgesture 1;
BA_ "EventCommandSignal" SG_ 967 DMS_RigntrearRockgesture 0;
BA_ "GenSigSendType" SG_ 967 DMS_RigntrearRockgesture 1;
BA_ "EventCommandSignal" SG_ 967 DMS_LeftrearRockgesture 0;
BA_ "GenSigSendType" SG_ 967 DMS_LeftrearRockgesture 1;
BA_ "EventCommandSignal" SG_ 967 DMS_CodriverRockgesture 0;
BA_ "GenSigSendType" SG_ 967 DMS_CodriverRockgesture 1;
BA_ "EventCommandSignal" SG_ 967 DMS_DriverRockgesture 0;
BA_ "GenSigSendType" SG_ 967 DMS_DriverRockgesture 1;
BA_ "EventCommandSignal" SG_ 967 DMS_MidrearWavepalmtotheleft 0;
BA_ "GenSigSendType" SG_ 967 DMS_MidrearWavepalmtotheleft 1;
BA_ "EventCommandSignal" SG_ 967 DMS_RigntrearWavepalmtotheleft 0;
BA_ "GenSigSendType" SG_ 967 DMS_RigntrearWavepalmtotheleft 1;
BA_ "EventCommandSignal" SG_ 967 DMS_LeftrearWavepalmtotheleft 0;
BA_ "GenSigSendType" SG_ 967 DMS_LeftrearWavepalmtotheleft 1;
BA_ "EventCommandSignal" SG_ 967 DMS_CodriverWavepalmtotheleft 0;
BA_ "GenSigSendType" SG_ 967 DMS_CodriverWavepalmtotheleft 1;
BA_ "EventCommandSignal" SG_ 967 DMS_DriverWavepalmtotheleft 0;
BA_ "GenSigSendType" SG_ 967 DMS_DriverWavepalmtotheleft 1;
BA_ "EventCommandSignal" SG_ 967 DMS_MidrearWavepalmtotheright 0;
BA_ "GenSigSendType" SG_ 967 DMS_MidrearWavepalmtotheright 1;
BA_ "EventCommandSignal" SG_ 967 DMS_RigntrearWavepalmtotheright 0;
BA_ "GenSigSendType" SG_ 967 DMS_RigntrearWavepalmtotheright 1;
BA_ "EventCommandSignal" SG_ 967 DMS_LeftrearWavepalmtotheright 0;
BA_ "GenSigSendType" SG_ 967 DMS_LeftrearWavepalmtotheright 1;
BA_ "EventCommandSignal" SG_ 967 DMS_CodriverWavepalmtotheright 0;
BA_ "GenSigSendType" SG_ 967 DMS_CodriverWavepalmtotheright 1;
BA_ "EventCommandSignal" SG_ 967 DMS_DriverWavepalmtotheright 0;
BA_ "GenSigSendType" SG_ 967 DMS_DriverWavepalmtotheright 1;
BA_ "EventCommandSignal" SG_ 967 DMS_MidrearDownwardwave 0;
BA_ "GenSigSendType" SG_ 967 DMS_MidrearDownwardwave 1;
BA_ "EventCommandSignal" SG_ 967 DMS_RigntrearDownwardwave 0;
BA_ "GenSigSendType" SG_ 967 DMS_RigntrearDownwardwave 1;
BA_ "EventCommandSignal" SG_ 967 DMS_LeftrearDownwardwave 0;
BA_ "GenSigSendType" SG_ 967 DMS_LeftrearDownwardwave 1;
BA_ "EventCommandSignal" SG_ 967 DMS_CodriverDownwardwave 0;
BA_ "GenSigSendType" SG_ 967 DMS_CodriverDownwardwave 1;
BA_ "EventCommandSignal" SG_ 967 DMS_DriverDownwardwave 0;
BA_ "GenSigSendType" SG_ 967 DMS_DriverDownwardwave 1;
BA_ "EventCommandSignal" SG_ 967 DMS_MidrearUpwardwave 0;
BA_ "GenSigSendType" SG_ 967 DMS_MidrearUpwardwave 1;
BA_ "EventCommandSignal" SG_ 967 DMS_RigntrearUpwardwave 0;
BA_ "GenSigSendType" SG_ 967 DMS_RigntrearUpwardwave 1;
BA_ "EventCommandSignal" SG_ 967 DMS_LeftrearUpwardwave 0;
BA_ "GenSigSendType" SG_ 967 DMS_LeftrearUpwardwave 1;
BA_ "EventCommandSignal" SG_ 967 DMS_CodriverUpwardwave 0;
BA_ "GenSigSendType" SG_ 967 DMS_CodriverUpwardwave 1;
BA_ "EventCommandSignal" SG_ 967 DMS_DriverUpwardwave 0;
BA_ "GenSigSendType" SG_ 967 DMS_DriverUpwardwave 1;
BA_ "EventCommandSignal" SG_ 967 DMS_MidrearForefingercircleleft 0;
BA_ "GenSigSendType" SG_ 967 DMS_MidrearForefingercircleleft 1;
BA_ "EventCommandSignal" SG_ 967 DMS_RigntrearForefingercirclelef 0;
BA_ "GenSigSendType" SG_ 967 DMS_RigntrearForefingercirclelef 1;
BA_ "SystemSignalLongSymbol" SG_ 967 DMS_RigntrearForefingercirclelef "DMS_RigntrearForefingercircleleft";
BA_ "EventCommandSignal" SG_ 967 DMS_LeftrearForefingercircleleft 0;
BA_ "GenSigSendType" SG_ 967 DMS_LeftrearForefingercircleleft 1;
BA_ "EventCommandSignal" SG_ 967 DMS_CodriverForefingercircleleft 0;
BA_ "GenSigSendType" SG_ 967 DMS_CodriverForefingercircleleft 1;
BA_ "EventCommandSignal" SG_ 967 DMS_DriverForefingercircleleft 0;
BA_ "GenSigSendType" SG_ 967 DMS_DriverForefingercircleleft 1;
BA_ "EventCommandSignal" SG_ 967 DMS_MidrearForefingercircleright 0;
BA_ "GenSigSendType" SG_ 967 DMS_MidrearForefingercircleright 1;
BA_ "EventCommandSignal" SG_ 967 DMS_RigntrearForefingercirclerig 0;
BA_ "GenSigSendType" SG_ 967 DMS_RigntrearForefingercirclerig 1;
BA_ "SystemSignalLongSymbol" SG_ 967 DMS_RigntrearForefingercirclerig "DMS_RigntrearForefingercircleright";
BA_ "EventCommandSignal" SG_ 967 DMS_LeftrearForefingercirclerigh 0;
BA_ "GenSigSendType" SG_ 967 DMS_LeftrearForefingercirclerigh 1;
BA_ "SystemSignalLongSymbol" SG_ 967 DMS_LeftrearForefingercirclerigh "DMS_LeftrearForefingercircleright";
BA_ "EventCommandSignal" SG_ 967 DMS_CodriverForefingercirclerigh 0;
BA_ "GenSigSendType" SG_ 967 DMS_CodriverForefingercirclerigh 1;
BA_ "SystemSignalLongSymbol" SG_ 967 DMS_CodriverForefingercirclerigh "DMS_CodriverForefingercircleright";
BA_ "EventCommandSignal" SG_ 967 DMS_DriverForefingercircleright 0;
BA_ "GenSigSendType" SG_ 967 DMS_DriverForefingercircleright 1;
BA_ "EventCommandSignal" SG_ 967 DMS_MidrearOKgesture 0;
BA_ "GenSigSendType" SG_ 967 DMS_MidrearOKgesture 1;
BA_ "EventCommandSignal" SG_ 967 DMS_RigntrearOKgesture 0;
BA_ "GenSigSendType" SG_ 967 DMS_RigntrearOKgesture 1;
BA_ "EventCommandSignal" SG_ 967 DMS_LeftrearOKgesture 0;
BA_ "GenSigSendType" SG_ 967 DMS_LeftrearOKgesture 1;
BA_ "EventCommandSignal" SG_ 967 DMS_CodriverOKgesture 0;
BA_ "GenSigSendType" SG_ 967 DMS_CodriverOKgesture 1;
BA_ "EventCommandSignal" SG_ 967 DMS_DriverOKgesture 0;
BA_ "GenSigSendType" SG_ 967 DMS_DriverOKgesture 1;
BA_ "EventCommandSignal" SG_ 967 DMS_MidrearHandheartgesture 0;
BA_ "GenSigSendType" SG_ 967 DMS_MidrearHandheartgesture 1;
BA_ "EventCommandSignal" SG_ 967 DMS_RigntrearHandheartgesture 0;
BA_ "GenSigSendType" SG_ 967 DMS_RigntrearHandheartgesture 1;
BA_ "EventCommandSignal" SG_ 967 DMS_LeftrearHandheartgesture 0;
BA_ "GenSigSendType" SG_ 967 DMS_LeftrearHandheartgesture 1;
BA_ "EventCommandSignal" SG_ 967 DMS_CodriverHandheartgesture 0;
BA_ "GenSigSendType" SG_ 967 DMS_CodriverHandheartgesture 1;
BA_ "EventCommandSignal" SG_ 967 DMS_DriverHandheartgesture 0;
BA_ "GenSigSendType" SG_ 967 DMS_DriverHandheartgesture 1;
BA_ "EventCommandSignal" SG_ 967 DMS_CarOwner 0;
BA_ "GenSigSendType" SG_ 967 DMS_CarOwner 1;
BA_ "EventCommandSignal" SG_ 967 DMS_PersonGender 0;
BA_ "GenSigSendType" SG_ 967 DMS_PersonGender 1;
BA_ "EventCommandSignal" SG_ 967 DMS_SeatMidrearSt 0;
BA_ "GenSigSendType" SG_ 967 DMS_SeatMidrearSt 1;
BA_ "EventCommandSignal" SG_ 967 DMS_SeatRigntrearSt 0;
BA_ "GenSigSendType" SG_ 967 DMS_SeatRigntrearSt 1;
BA_ "EventCommandSignal" SG_ 967 DMS_SeatLeftrearSt 0;
BA_ "GenSigSendType" SG_ 967 DMS_SeatLeftrearSt 1;
BA_ "EventCommandSignal" SG_ 967 DMS_PersonAge 0;
BA_ "GenSigSendType" SG_ 967 DMS_PersonAge 1;
BA_ "EventCommandSignal" SG_ 967 DMS_SeatMidmiddleSt 0;
BA_ "GenSigSendType" SG_ 967 DMS_SeatMidmiddleSt 1;
BA_ "EventCommandSignal" SG_ 967 DMS_SeatCodriverSt 0;
BA_ "GenSigSendType" SG_ 967 DMS_SeatCodriverSt 1;
BA_ "EventCommandSignal" SG_ 967 DMS_PersonCount 0;
BA_ "GenSigSendType" SG_ 967 DMS_PersonCount 1;
BA_ "EventCommandSignal" SG_ 967 DMS_DriverDistractionSt 0;
BA_ "GenSigSendType" SG_ 967 DMS_DriverDistractionSt 1;
BA_ "EventCommandSignal" SG_ 967 DMS_SeatDriverSt 0;
BA_ "GenSigSendType" SG_ 967 DMS_SeatDriverSt 1;
BA_ "EventCommandSignal" SG_ 967 DMS_DriverInterestsRegion 0;
BA_ "GenSigSendType" SG_ 967 DMS_DriverInterestsRegion 1;
BA_ "EventCommandSignal" SG_ 967 DMS_DriverFatigueSt 0;
BA_ "GenSigSendType" SG_ 967 DMS_DriverFatigueSt 1;
BA_ "EventCommandSignal" SG_ 967 DMS_FaceIDFailCause 0;
BA_ "GenSigSendType" SG_ 967 DMS_FaceIDFailCause 1;
BA_ "EventCommandSignal" SG_ 967 DMS_FaceIDWelcomeMode 0;
BA_ "GenSigSendType" SG_ 967 DMS_FaceIDWelcomeMode 1;
BA_ "EventCommandSignal" SG_ 967 DMS_DriverFaceID 0;
BA_ "GenSigSendType" SG_ 967 DMS_DriverFaceID 1;
BA_ "EventCommandSignal" SG_ 967 DMS_MidrearHealthSt 0;
BA_ "GenSigSendType" SG_ 967 DMS_MidrearHealthSt 1;
BA_ "EventCommandSignal" SG_ 967 DMS_RigntrearHealthSt 0;
BA_ "GenSigSendType" SG_ 967 DMS_RigntrearHealthSt 1;
BA_ "EventCommandSignal" SG_ 967 DMS_LeftrearHealthSt 0;
BA_ "GenSigSendType" SG_ 967 DMS_LeftrearHealthSt 1;
BA_ "EventCommandSignal" SG_ 967 DMS_CodriverHealthSt 0;
BA_ "GenSigSendType" SG_ 967 DMS_CodriverHealthSt 1;
BA_ "EventCommandSignal" SG_ 967 DMS_SeatPositionID 0;
BA_ "GenSigSendType" SG_ 967 DMS_SeatPositionID 1;
BA_ "EventCommandSignal" SG_ 967 DMS_MidrearTelephoneSt 0;
BA_ "GenSigSendType" SG_ 967 DMS_MidrearTelephoneSt 1;
BA_ "EventCommandSignal" SG_ 967 DMS_RigntrearTelephoneSt 0;
BA_ "GenSigSendType" SG_ 967 DMS_RigntrearTelephoneSt 1;
BA_ "EventCommandSignal" SG_ 967 DMS_LeftrearTelephoneSt 0;
BA_ "GenSigSendType" SG_ 967 DMS_LeftrearTelephoneSt 1;
BA_ "EventCommandSignal" SG_ 967 DMS_CodriverTelephoneSt 0;
BA_ "GenSigSendType" SG_ 967 DMS_CodriverTelephoneSt 1;
BA_ "EventCommandSignal" SG_ 967 DMS_MidrearSmokeSt 0;
BA_ "GenSigSendType" SG_ 967 DMS_MidrearSmokeSt 1;
BA_ "EventCommandSignal" SG_ 967 DMS_RigntrearSmokeSt 0;
BA_ "GenSigSendType" SG_ 967 DMS_RigntrearSmokeSt 1;
BA_ "EventCommandSignal" SG_ 967 DMS_LeftrearSmokeSt 0;
BA_ "GenSigSendType" SG_ 967 DMS_LeftrearSmokeSt 1;
BA_ "EventCommandSignal" SG_ 967 DMS_MidrearExpressionSt 0;
BA_ "GenSigSendType" SG_ 967 DMS_MidrearExpressionSt 1;
BA_ "EventCommandSignal" SG_ 967 DMS_RigntrearExpressionSt 0;
BA_ "GenSigSendType" SG_ 967 DMS_RigntrearExpressionSt 1;
BA_ "EventCommandSignal" SG_ 967 DMS_LeftrearExpressionSt 0;
BA_ "GenSigSendType" SG_ 967 DMS_LeftrearExpressionSt 1;
BA_ "EventCommandSignal" SG_ 967 DMS_CodriverExpressionSt 0;
BA_ "GenSigSendType" SG_ 967 DMS_CodriverExpressionSt 1;
BA_ "EventCommandSignal" SG_ 967 DMS_CodriverSmokeSt 0;
BA_ "GenSigSendType" SG_ 967 DMS_CodriverSmokeSt 1;
BA_ "EventCommandSignal" SG_ 967 DMS_ObjectSt 0;
BA_ "GenSigSendType" SG_ 967 DMS_ObjectSt 1;
BA_ "EventCommandSignal" SG_ 967 DMS_PetSt 0;
BA_ "GenSigSendType" SG_ 967 DMS_PetSt 1;
BA_ "EventCommandSignal" SG_ 967 DMS_DistrWarnSt 0;
BA_ "GenSigSendType" SG_ 967 DMS_DistrWarnSt 1;
BA_ "EventCommandSignal" SG_ 967 DMS_FatigWarnSt 0;
BA_ "GenSigSendType" SG_ 967 DMS_FatigWarnSt 1;
BA_ "EventCommandSignal" SG_ 967 DMS_SeatLeftmiddleSt 0;
BA_ "GenSigSendType" SG_ 967 DMS_SeatLeftmiddleSt 1;
BA_ "EventCommandSignal" SG_ 967 DMS_SeatRightmiddleSt 0;
BA_ "GenSigSendType" SG_ 967 DMS_SeatRightmiddleSt 1;
BA_ "EventCommandSignal" SG_ 967 DMS_DriverHealthSt 0;
BA_ "GenSigSendType" SG_ 967 DMS_DriverHealthSt 1;
BA_ "EventCommandSignal" SG_ 967 DMS_DriverTelephoneSt 0;
BA_ "GenSigSendType" SG_ 967 DMS_DriverTelephoneSt 1;
BA_ "EventCommandSignal" SG_ 967 DMS_DriverSmokeSt 0;
BA_ "GenSigSendType" SG_ 967 DMS_DriverSmokeSt 1;
BA_ "EventCommandSignal" SG_ 967 DMS_GlassWearSt 0;
BA_ "GenSigSendType" SG_ 967 DMS_GlassWearSt 1;
BA_ "EventCommandSignal" SG_ 967 DMS_MouthSt 0;
BA_ "GenSigSendType" SG_ 967 DMS_MouthSt 1;
BA_ "EventCommandSignal" SG_ 967 DMS_RightEyeOpenSt 0;
BA_ "GenSigSendType" SG_ 967 DMS_RightEyeOpenSt 1;
BA_ "EventCommandSignal" SG_ 967 DMS_LeftEyeOpenSt 0;
BA_ "GenSigSendType" SG_ 967 DMS_LeftEyeOpenSt 1;
BA_ "GenSigSendType" SG_ 967 DMS_1_Checksum 1;
BA_ "EventCommandSignal" SG_ 967 DMS_1_Checksum 0;
BA_ "GenSigSendType" SG_ 967 DMS_1_MsgCounter 1;
BA_ "EventCommandSignal" SG_ 967 DMS_1_MsgCounter 0;
BA_ "GenSigSendType" SG_ 967 DMS_SysErrSt 1;
BA_ "EventCommandSignal" SG_ 967 DMS_SysErrSt 0;
BA_ "GenSigSendType" SG_ 967 DMS_DrvrDetSts 1;
BA_ "EventCommandSignal" SG_ 967 DMS_DrvrDetSts 0;
BA_ "GenSigSendType" SG_ 967 DMS_InterestsRegion 1;
BA_ "EventCommandSignal" SG_ 967 DMS_InterestsRegion 0;
BA_ "GenSigSendType" SG_ 967 DMS_L3DriverDistractionSt 1;
BA_ "EventCommandSignal" SG_ 967 DMS_L3DriverDistractionSt 0;
BA_ "GenSigSendType" SG_ 967 DMS_L3DriverFatigueSt 1;
BA_ "EventCommandSignal" SG_ 967 DMS_L3DriverFatigueSt 0;
BA_ "GenSigSendType" SG_ 1963 IDC_Diag_Response 0;
BA_ "EventCommandSignal" SG_ 1963 IDC_Diag_Response 0;
BA_ "GenSigStartValue" SG_ 1323 IDC_NMNodeAddress 43;
BA_ "GenSigSendType" SG_ 1323 IDC_NMNodeAddress 1;
BA_ "EventCommandSignal" SG_ 1323 IDC_NMNodeAddress 0;
BA_ "GenSigSendType" SG_ 1323 IDC_NMDataField 1;
BA_ "EventCommandSignal" SG_ 1323 IDC_NMDataField 0;
BA_ "GenSigSendType" SG_ 1323 IDC_NMWakeupOrigin 1;
BA_ "EventCommandSignal" SG_ 1323 IDC_NMWakeupOrigin 0;
BA_ "GenSigSendType" SG_ 1323 IDC_PNCInformation0 1;
BA_ "EventCommandSignal" SG_ 1323 IDC_PNCInformation0 0;
BA_ "GenSigSendType" SG_ 1323 IDC_PNCInformation1 1;
BA_ "EventCommandSignal" SG_ 1323 IDC_PNCInformation1 0;
BA_ "GenSigStartValue" SG_ 169 IDC_SecReq 17;
BA_ "GenSigSendType" SG_ 169 IDC_SecReq 0;
BA_ "EventCommandSignal" SG_ 169 IDC_SecReq 1;
BA_ "GenSigSendType" SG_ 157 IDC_IMMO 0;
BA_ "EventCommandSignal" SG_ 157 IDC_IMMO 1;
BA_ "GenSigSendType" SG_ 122 IDC_SEC_KEY_Defaultencoding 0;
BA_ "EventCommandSignal" SG_ 122 IDC_SEC_KEY_Defaultencoding 1;
BA_ "GenSigSendType" SG_ 624 KAE_KeyReminderWarning 1;
BA_ "GatewayedSignals" SG_ 624 KAE_KeyReminderWarning 1;
BA_ "EventCommandSignal" SG_ 624 KAE_KeyReminderWarning 0;
BA_ "GenSigSendType" SG_ 624 KAE_DoorLockWarning 1;
BA_ "GatewayedSignals" SG_ 624 KAE_DoorLockWarning 1;
BA_ "EventCommandSignal" SG_ 624 KAE_DoorLockWarning 0;
BA_ "GenSigSendType" SG_ 624 KAE_StartAuthFailWarning 1;
BA_ "GatewayedSignals" SG_ 624 KAE_StartAuthFailWarning 1;
BA_ "EventCommandSignal" SG_ 624 KAE_StartAuthFailWarning 0;
BA_ "GenSigSendType" SG_ 624 KAE_KeyBattaryLowWarning 1;
BA_ "GatewayedSignals" SG_ 624 KAE_KeyBattaryLowWarning 1;
BA_ "EventCommandSignal" SG_ 624 KAE_KeyBattaryLowWarning 0;
BA_ "GenSigSendType" SG_ 624 KAE_IDOutWarning 1;
BA_ "GatewayedSignals" SG_ 624 KAE_IDOutWarning 1;
BA_ "EventCommandSignal" SG_ 624 KAE_IDOutWarning 0;
BA_ "GenSigSendType" SG_ 624 ZCUR_1_FreshnessValue 1;
BA_ "GatewayedSignals" SG_ 624 ZCUR_1_FreshnessValue 1;
BA_ "EventCommandSignal" SG_ 624 ZCUR_1_FreshnessValue 0;
BA_ "GenSigSendType" SG_ 624 ZCUR_1_MAC_Check 1;
BA_ "EventCommandSignal" SG_ 624 ZCUR_1_MAC_Check 0;
BA_ "GenSigSendType" SG_ 777 SSW_FROttomanExtentCurrentOpeSt 1;
BA_ "GatewayedSignals" SG_ 777 SSW_FROttomanExtentCurrentOpeSt 0;
BA_ "EventCommandSignal" SG_ 777 SSW_FROttomanExtentCurrentOpeSt 0;
BA_ "GenSigSendType" SG_ 777 SSW_FROttomanExtentCurrentPst 1;
BA_ "GenSigStartValue" SG_ 777 SSW_FROttomanExtentCurrentPst 255;
BA_ "GatewayedSignals" SG_ 777 SSW_FROttomanExtentCurrentPst 0;
BA_ "EventCommandSignal" SG_ 777 SSW_FROttomanExtentCurrentPst 0;
BA_ "GenSigSendType" SG_ 777 SSW_FROttomanAngleCurrentOpeSt 1;
BA_ "GatewayedSignals" SG_ 777 SSW_FROttomanAngleCurrentOpeSt 0;
BA_ "EventCommandSignal" SG_ 777 SSW_FROttomanAngleCurrentOpeSt 0;
BA_ "GenSigSendType" SG_ 777 SSW_FROttomanAngleCurrentPst 1;
BA_ "GenSigStartValue" SG_ 777 SSW_FROttomanAngleCurrentPst 255;
BA_ "GatewayedSignals" SG_ 777 SSW_FROttomanAngleCurrentPst 0;
BA_ "EventCommandSignal" SG_ 777 SSW_FROttomanAngleCurrentPst 0;
BA_ "GenSigStartValue" SG_ 777 SSW_FRSeatSlideCurrentPst 255;
BA_ "GenSigSendType" SG_ 777 SSW_FRSeatSlideCurrentPst 1;
BA_ "GatewayedSignals" SG_ 777 SSW_FRSeatSlideCurrentPst 1;
BA_ "EventCommandSignal" SG_ 777 SSW_FRSeatSlideCurrentPst 0;
BA_ "GenSigStartValue" SG_ 777 SSW_FRSeatHeightCurrentPst 255;
BA_ "GenSigSendType" SG_ 777 SSW_FRSeatHeightCurrentPst 1;
BA_ "GatewayedSignals" SG_ 777 SSW_FRSeatHeightCurrentPst 1;
BA_ "EventCommandSignal" SG_ 777 SSW_FRSeatHeightCurrentPst 0;
BA_ "GenSigStartValue" SG_ 777 SSW_FRSeatBackrestCurrentPst 255;
BA_ "GenSigSendType" SG_ 777 SSW_FRSeatBackrestCurrentPst 1;
BA_ "GatewayedSignals" SG_ 777 SSW_FRSeatBackrestCurrentPst 1;
BA_ "EventCommandSignal" SG_ 777 SSW_FRSeatBackrestCurrentPst 0;
BA_ "GenSigStartValue" SG_ 777 SSW_FRSeatTiltCurrentPst 255;
BA_ "GenSigSendType" SG_ 777 SSW_FRSeatTiltCurrentPst 1;
BA_ "GatewayedSignals" SG_ 777 SSW_FRSeatTiltCurrentPst 1;
BA_ "EventCommandSignal" SG_ 777 SSW_FRSeatTiltCurrentPst 0;
BA_ "GenSigStartValue" SG_ 777 SSW_FRSeatCushionCurrentPst 255;
BA_ "GenSigSendType" SG_ 777 SSW_FRSeatCushionCurrentPst 1;
BA_ "GatewayedSignals" SG_ 777 SSW_FRSeatCushionCurrentPst 1;
BA_ "EventCommandSignal" SG_ 777 SSW_FRSeatCushionCurrentPst 0;
BA_ "GenSigStartValue" SG_ 777 SSW_FRSeatOttomanCurrentPst 255;
BA_ "GenSigSendType" SG_ 777 SSW_FRSeatOttomanCurrentPst 1;
BA_ "GatewayedSignals" SG_ 777 SSW_FRSeatOttomanCurrentPst 1;
BA_ "EventCommandSignal" SG_ 777 SSW_FRSeatOttomanCurrentPst 0;
BA_ "GenSigSendType" SG_ 777 SSW_FRSeatHeatingSt 1;
BA_ "GatewayedSignals" SG_ 777 SSW_FRSeatHeatingSt 1;
BA_ "EventCommandSignal" SG_ 777 SSW_FRSeatHeatingSt 0;
BA_ "GenSigSendType" SG_ 777 SSW_FRSeatVentSt 1;
BA_ "GatewayedSignals" SG_ 777 SSW_FRSeatVentSt 1;
BA_ "EventCommandSignal" SG_ 777 SSW_FRSeatVentSt 0;
BA_ "GenSigSendType" SG_ 777 EL_MRTurnLightSt 1;
BA_ "GatewayedSignals" SG_ 777 EL_MRTurnLightSt 1;
BA_ "EventCommandSignal" SG_ 777 EL_MRTurnLightSt 0;
BA_ "GenSigSendType" SG_ 777 EL_MRTurnLightFaultSt 1;
BA_ "GatewayedSignals" SG_ 777 EL_MRTurnLightFaultSt 1;
BA_ "EventCommandSignal" SG_ 777 EL_MRTurnLightFaultSt 0;
BA_ "EventCommandSignal" SG_ 786 SSW_FRMassageForceSt 0;
BA_ "GatewayedSignals" SG_ 786 SSW_FRMassageForceSt 0;
BA_ "GenSigSendType" SG_ 786 SSW_FRMassageForceSt 1;
BA_ "EventCommandSignal" SG_ 786 SSW_FRMassageModeSt 0;
BA_ "GatewayedSignals" SG_ 786 SSW_FRMassageModeSt 0;
BA_ "GenSigSendType" SG_ 786 SSW_FRMassageModeSt 1;
BA_ "EventCommandSignal" SG_ 786 SSW_FRSPAMode 0;
BA_ "GatewayedSignals" SG_ 786 SSW_FRSPAMode 0;
BA_ "GenSigSendType" SG_ 786 SSW_FRSPAMode 1;
BA_ "EventCommandSignal" SG_ 786 SSW_FRLumbarModeSt 0;
BA_ "GatewayedSignals" SG_ 786 SSW_FRLumbarModeSt 0;
BA_ "GenSigSendType" SG_ 786 SSW_FRLumbarModeSt 1;
BA_ "EventCommandSignal" SG_ 786 SSW_FRMassageSt 0;
BA_ "GatewayedSignals" SG_ 786 SSW_FRMassageSt 0;
BA_ "GenSigSendType" SG_ 786 SSW_FRMassageSt 1;
BA_ "GenSigSendType" SG_ 786 AQM_CO2DataVD 1;
BA_ "GatewayedSignals" SG_ 786 AQM_CO2DataVD 1;
BA_ "EventCommandSignal" SG_ 786 AQM_CO2DataVD 0;
BA_ "GenSigSendType" SG_ 786 AQM_CO2Data 1;
BA_ "GatewayedSignals" SG_ 786 AQM_CO2Data 1;
BA_ "EventCommandSignal" SG_ 786 AQM_CO2Data 0;
BA_ "GenSigSendType" SG_ 786 AQM_PM25Data 1;
BA_ "GatewayedSignals" SG_ 786 AQM_PM25Data 1;
BA_ "EventCommandSignal" SG_ 786 AQM_PM25Data 0;
BA_ "GenSigSendType" SG_ 786 AQM_PM10Data 1;
BA_ "GatewayedSignals" SG_ 786 AQM_PM10Data 1;
BA_ "EventCommandSignal" SG_ 786 AQM_PM10Data 0;
BA_ "GenSigSendType" SG_ 786 AQM_PM25DataVD 1;
BA_ "GatewayedSignals" SG_ 786 AQM_PM25DataVD 1;
BA_ "EventCommandSignal" SG_ 786 AQM_PM25DataVD 0;
BA_ "GenSigSendType" SG_ 786 AQM_PM10DataVD 1;
BA_ "GatewayedSignals" SG_ 786 AQM_PM10DataVD 1;
BA_ "EventCommandSignal" SG_ 786 AQM_PM10DataVD 0;
BA_ "GenSigSendType" SG_ 786 AQM_PM25ValueOutVD 1;
BA_ "GatewayedSignals" SG_ 786 AQM_PM25ValueOutVD 1;
BA_ "EventCommandSignal" SG_ 786 AQM_PM25ValueOutVD 0;
BA_ "GenSigSendType" SG_ 786 AQM_PM25ValueOut 1;
BA_ "GatewayedSignals" SG_ 786 AQM_PM25ValueOut 1;
BA_ "EventCommandSignal" SG_ 786 AQM_PM25ValueOut 0;
BA_ "GenSigSendType" SG_ 342 KAE_KUID 0;
BA_ "GatewayedSignals" SG_ 342 KAE_KUID 1;
BA_ "EventCommandSignal" SG_ 342 KAE_KUID 1;
BA_ "GenSigSendType" SG_ 342 KAE_RKEChargeGunUnlockReq 0;
BA_ "GatewayedSignals" SG_ 342 KAE_RKEChargeGunUnlockReq 1;
BA_ "EventCommandSignal" SG_ 342 KAE_RKEChargeGunUnlockReq 1;
BA_ "GenSigSendType" SG_ 632 SSW_FLLumbarOpeSt 1;
BA_ "GatewayedSignals" SG_ 632 SSW_FLLumbarOpeSt 0;
BA_ "EventCommandSignal" SG_ 632 SSW_FLLumbarOpeSt 0;
BA_ "GenSigSendType" SG_ 632 SSW_FLOttomanExtentCurrentOpeSt 1;
BA_ "GatewayedSignals" SG_ 632 SSW_FLOttomanExtentCurrentOpeSt 0;
BA_ "EventCommandSignal" SG_ 632 SSW_FLOttomanExtentCurrentOpeSt 0;
BA_ "GenSigSendType" SG_ 632 SSW_FLOttomanExtentCurrentPst 1;
BA_ "GenSigStartValue" SG_ 632 SSW_FLOttomanExtentCurrentPst 255;
BA_ "GatewayedSignals" SG_ 632 SSW_FLOttomanExtentCurrentPst 0;
BA_ "EventCommandSignal" SG_ 632 SSW_FLOttomanExtentCurrentPst 0;
BA_ "GenSigSendType" SG_ 632 SSW_FLOttomanAngleCurrentOpeSt 1;
BA_ "GatewayedSignals" SG_ 632 SSW_FLOttomanAngleCurrentOpeSt 0;
BA_ "EventCommandSignal" SG_ 632 SSW_FLOttomanAngleCurrentOpeSt 0;
BA_ "GenSigSendType" SG_ 632 SSW_FLOttomanAngleCurrentPst 1;
BA_ "GenSigStartValue" SG_ 632 SSW_FLOttomanAngleCurrentPst 255;
BA_ "GatewayedSignals" SG_ 632 SSW_FLOttomanAngleCurrentPst 0;
BA_ "EventCommandSignal" SG_ 632 SSW_FLOttomanAngleCurrentPst 0;
BA_ "EventCommandSignal" SG_ 632 SSW_FLSeatVentSt 0;
BA_ "GenSigSendType" SG_ 632 SSW_FLSeatVentSt 1;
BA_ "EventCommandSignal" SG_ 632 SSW_FLSeatHeatingSt 0;
BA_ "GenSigSendType" SG_ 632 SSW_FLSeatHeatingSt 1;
BA_ "GenSigStartValue" SG_ 632 SSW_FLSeatSlideCurrentPst 255;
BA_ "GenSigSendType" SG_ 632 SSW_FLSeatSlideCurrentPst 1;
BA_ "EventCommandSignal" SG_ 632 SSW_FLSeatSlideCurrentPst 0;
BA_ "GenSigStartValue" SG_ 632 SSW_FLSeatHeightCurrentPst 255;
BA_ "GenSigSendType" SG_ 632 SSW_FLSeatHeightCurrentPst 1;
BA_ "EventCommandSignal" SG_ 632 SSW_FLSeatHeightCurrentPst 0;
BA_ "GenSigStartValue" SG_ 632 SSW_FLSeatBackrestCurrentPst 255;
BA_ "GenSigSendType" SG_ 632 SSW_FLSeatBackrestCurrentPst 1;
BA_ "EventCommandSignal" SG_ 632 SSW_FLSeatBackrestCurrentPst 0;
BA_ "GenSigStartValue" SG_ 632 SSW_FLSeatTiltCurrentPst 255;
BA_ "GenSigSendType" SG_ 632 SSW_FLSeatTiltCurrentPst 1;
BA_ "EventCommandSignal" SG_ 632 SSW_FLSeatTiltCurrentPst 0;
BA_ "GenSigStartValue" SG_ 632 SSW_SteeringAngleCurrentPst 255;
BA_ "GenSigSendType" SG_ 632 SSW_SteeringAngleCurrentPst 1;
BA_ "EventCommandSignal" SG_ 632 SSW_SteeringAngleCurrentPst 0;
BA_ "GenSigStartValue" SG_ 632 SSW_SteeringExtentCurrentPst 255;
BA_ "GenSigSendType" SG_ 632 SSW_SteeringExtentCurrentPst 1;
BA_ "EventCommandSignal" SG_ 632 SSW_SteeringExtentCurrentPst 0;
BA_ "GenSigStartValue" SG_ 632 SSW_FLSeatCushionCurrentPst 255;
BA_ "GenSigSendType" SG_ 632 SSW_FLSeatCushionCurrentPst 1;
BA_ "EventCommandSignal" SG_ 632 SSW_FLSeatCushionCurrentPst 0;
BA_ "GenSigStartValue" SG_ 632 SSW_FLSeatOttomanCurrentPst 255;
BA_ "GenSigSendType" SG_ 632 SSW_FLSeatOttomanCurrentPst 1;
BA_ "EventCommandSignal" SG_ 632 SSW_FLSeatOttomanCurrentPst 0;
BA_ "GenSigStartValue" SG_ 632 SSW_SteerHeatSt 1;
BA_ "EventCommandSignal" SG_ 632 SSW_SteerHeatSt 0;
BA_ "GenSigSendType" SG_ 776 EL_MLTurnLightSt 1;
BA_ "GatewayedSignals" SG_ 776 EL_MLTurnLightSt 1;
BA_ "EventCommandSignal" SG_ 776 EL_MLTurnLightSt 0;
BA_ "GenSigSendType" SG_ 776 EL_MLTurnLightFaultSt 1;
BA_ "GatewayedSignals" SG_ 776 EL_MLTurnLightFaultSt 1;
BA_ "EventCommandSignal" SG_ 776 EL_MLTurnLightFaultSt 0;
BA_ "GenSigSendType" SG_ 776 UINM_HazardLightSwSt 1;
BA_ "GatewayedSignals" SG_ 776 UINM_HazardLightSwSt 1;
BA_ "EventCommandSignal" SG_ 776 UINM_HazardLightSwSt 0;
BA_ "EventCommandSignal" SG_ 791 WW_FWPMotorSt 0;
BA_ "GatewayedSignals" SG_ 791 WW_FWPMotorSt 0;
BA_ "GenSigSendType" SG_ 791 WW_FWPMotorSt 1;
BA_ "GenSigSendType" SG_ 791 WW_FWSHLevelWarning 1;
BA_ "GatewayedSignals" SG_ 791 WW_FWSHLevelWarning 1;
BA_ "EventCommandSignal" SG_ 791 WW_FWSHLevelWarning 0;
BA_ "GenSigSendType" SG_ 791 EL_FLPositionLightSt 1;
BA_ "GatewayedSignals" SG_ 791 EL_FLPositionLightSt 1;
BA_ "EventCommandSignal" SG_ 791 EL_FLPositionLightSt 0;
BA_ "GenSigSendType" SG_ 791 EL_FLPositionLightFaultSt 1;
BA_ "GatewayedSignals" SG_ 791 EL_FLPositionLightFaultSt 1;
BA_ "EventCommandSignal" SG_ 791 EL_FLPositionLightFaultSt 0;
BA_ "GenSigSendType" SG_ 791 EL_FRPositionLightSt 1;
BA_ "GatewayedSignals" SG_ 791 EL_FRPositionLightSt 1;
BA_ "EventCommandSignal" SG_ 791 EL_FRPositionLightSt 0;
BA_ "GenSigSendType" SG_ 791 EL_FRPositionLightFaultSt 1;
BA_ "GatewayedSignals" SG_ 791 EL_FRPositionLightFaultSt 1;
BA_ "EventCommandSignal" SG_ 791 EL_FRPositionLightFaultSt 0;
BA_ "GenSigSendType" SG_ 791 EL_LeftLowBeamSt 1;
BA_ "GatewayedSignals" SG_ 791 EL_LeftLowBeamSt 1;
BA_ "EventCommandSignal" SG_ 791 EL_LeftLowBeamSt 0;
BA_ "GenSigSendType" SG_ 791 EL_LeftLowBeamFaultSt 1;
BA_ "GatewayedSignals" SG_ 791 EL_LeftLowBeamFaultSt 1;
BA_ "EventCommandSignal" SG_ 791 EL_LeftLowBeamFaultSt 0;
BA_ "GenSigSendType" SG_ 791 EL_RightLowBeamSt 1;
BA_ "GatewayedSignals" SG_ 791 EL_RightLowBeamSt 1;
BA_ "EventCommandSignal" SG_ 791 EL_RightLowBeamSt 0;
BA_ "GenSigSendType" SG_ 791 EL_RightLowBeamFaultSt 1;
BA_ "GatewayedSignals" SG_ 791 EL_RightLowBeamFaultSt 1;
BA_ "EventCommandSignal" SG_ 791 EL_RightLowBeamFaultSt 0;
BA_ "GenSigSendType" SG_ 791 EL_LeftHighBeamSt 1;
BA_ "GatewayedSignals" SG_ 791 EL_LeftHighBeamSt 1;
BA_ "EventCommandSignal" SG_ 791 EL_LeftHighBeamSt 0;
BA_ "GenSigSendType" SG_ 791 EL_LeftHighBeamFaultSt 1;
BA_ "GatewayedSignals" SG_ 791 EL_LeftHighBeamFaultSt 1;
BA_ "EventCommandSignal" SG_ 791 EL_LeftHighBeamFaultSt 0;
BA_ "GenSigSendType" SG_ 791 EL_RightHighBeamSt 1;
BA_ "GatewayedSignals" SG_ 791 EL_RightHighBeamSt 1;
BA_ "EventCommandSignal" SG_ 791 EL_RightHighBeamSt 0;
BA_ "GenSigSendType" SG_ 791 EL_RightHighBeamFaultSt 1;
BA_ "GatewayedSignals" SG_ 791 EL_RightHighBeamFaultSt 1;
BA_ "EventCommandSignal" SG_ 791 EL_RightHighBeamFaultSt 0;
BA_ "GenSigSendType" SG_ 791 EL_FLFogLightSt 1;
BA_ "GatewayedSignals" SG_ 791 EL_FLFogLightSt 1;
BA_ "EventCommandSignal" SG_ 791 EL_FLFogLightSt 0;
BA_ "GenSigSendType" SG_ 791 EL_FLFogLightFaultSt 1;
BA_ "GatewayedSignals" SG_ 791 EL_FLFogLightFaultSt 1;
BA_ "EventCommandSignal" SG_ 791 EL_FLFogLightFaultSt 0;
BA_ "GenSigSendType" SG_ 791 EL_FRFogLightSt 1;
BA_ "GatewayedSignals" SG_ 791 EL_FRFogLightSt 1;
BA_ "EventCommandSignal" SG_ 791 EL_FRFogLightSt 0;
BA_ "GenSigSendType" SG_ 791 EL_FRFogLightFaultSt 1;
BA_ "GatewayedSignals" SG_ 791 EL_FRFogLightFaultSt 1;
BA_ "EventCommandSignal" SG_ 791 EL_FRFogLightFaultSt 0;
BA_ "GenSigSendType" SG_ 791 EL_LeftDRLFaultSt 1;
BA_ "GatewayedSignals" SG_ 791 EL_LeftDRLFaultSt 1;
BA_ "EventCommandSignal" SG_ 791 EL_LeftDRLFaultSt 0;
BA_ "GenSigSendType" SG_ 791 EL_RightDRLFaultSt 1;
BA_ "GatewayedSignals" SG_ 791 EL_RightDRLFaultSt 1;
BA_ "EventCommandSignal" SG_ 791 EL_RightDRLFaultSt 0;
BA_ "GenSigSendType" SG_ 791 EL_FLTurnLightSt 1;
BA_ "GatewayedSignals" SG_ 791 EL_FLTurnLightSt 1;
BA_ "EventCommandSignal" SG_ 791 EL_FLTurnLightSt 0;
BA_ "GenSigSendType" SG_ 791 EL_FLTurnLightFaultSt 1;
BA_ "GatewayedSignals" SG_ 791 EL_FLTurnLightFaultSt 1;
BA_ "EventCommandSignal" SG_ 791 EL_FLTurnLightFaultSt 0;
BA_ "GenSigSendType" SG_ 791 EL_FRTurnLightSt 1;
BA_ "GatewayedSignals" SG_ 791 EL_FRTurnLightSt 1;
BA_ "EventCommandSignal" SG_ 791 EL_FRTurnLightSt 0;
BA_ "GenSigSendType" SG_ 791 EL_FRTurnLightFaultSt 1;
BA_ "GatewayedSignals" SG_ 791 EL_FRTurnLightFaultSt 1;
BA_ "EventCommandSignal" SG_ 791 EL_FRTurnLightFaultSt 0;
BA_ "GenSigStartValue" SG_ 791 EBSF_SOC 255;
BA_ "GenSigSendType" SG_ 791 EBSF_SOC 1;
BA_ "GatewayedSignals" SG_ 791 EBSF_SOC 1;
BA_ "EventCommandSignal" SG_ 791 EBSF_SOC 0;
BA_ "GenSigStartValue" SG_ 791 EBSF_SOC_STATE 3;
BA_ "GenSigSendType" SG_ 791 EBSF_SOC_STATE 1;
BA_ "GatewayedSignals" SG_ 791 EBSF_SOC_STATE 1;
BA_ "EventCommandSignal" SG_ 791 EBSF_SOC_STATE 0;
BA_ "GenSigSendType" SG_ 792 EL_CHMSLSt 1;
BA_ "GatewayedSignals" SG_ 792 EL_CHMSLSt 0;
BA_ "EventCommandSignal" SG_ 792 EL_CHMSLSt 0;
BA_ "GenSigSendType" SG_ 792 EL_SideBrkLightSt 1;
BA_ "GatewayedSignals" SG_ 792 EL_SideBrkLightSt 0;
BA_ "EventCommandSignal" SG_ 792 EL_SideBrkLightSt 0;
BA_ "GenSigSendType" SG_ 792 EL_ReverseLightSt 1;
BA_ "GatewayedSignals" SG_ 792 EL_ReverseLightSt 0;
BA_ "EventCommandSignal" SG_ 792 EL_ReverseLightSt 0;
BA_ "GatewayedSignals" SG_ 792 UMM_SecondMIDSeatSt 1;
BA_ "GenSigSendType" SG_ 792 UMM_SecondMIDSeatSt 1;
BA_ "GatewayedSignals" SG_ 792 UMM_SecondRHSeatSt 1;
BA_ "GenSigSendType" SG_ 792 UMM_SecondRHSeatSt 1;
BA_ "GatewayedSignals" SG_ 792 UMM_SecondLHSeatSt 1;
BA_ "GenSigSendType" SG_ 792 UMM_SecondLHSeatSt 1;
BA_ "GenSigStartValue" SG_ 792 PLG_SetPosition 200;
BA_ "EventCommandSignal" SG_ 792 PLG_SetPosition 0;
BA_ "GenSigSendType" SG_ 792 LCK_PowerFillerCapAngle 1;
BA_ "EventCommandSignal" SG_ 792 LCK_PowerFillerCapAngle 0;
BA_ "GenSigSendType" SG_ 792 EL_ReverseLightFaultSt 1;
BA_ "EventCommandSignal" SG_ 792 EL_ReverseLightFaultSt 0;
BA_ "GenSigSendType" SG_ 792 EL_SideBrkLightFaultSt 1;
BA_ "EventCommandSignal" SG_ 792 EL_SideBrkLightFaultSt 0;
BA_ "GenSigSendType" SG_ 792 EL_CHMSLFaultSt 1;
BA_ "EventCommandSignal" SG_ 792 EL_CHMSLFaultSt 0;
BA_ "GenSigSendType" SG_ 792 EL_RLPositionLightSt 1;
BA_ "EventCommandSignal" SG_ 792 EL_RLPositionLightSt 0;
BA_ "GenSigSendType" SG_ 792 EL_RLPositionLightFaultSt 1;
BA_ "EventCommandSignal" SG_ 792 EL_RLPositionLightFaultSt 0;
BA_ "GenSigSendType" SG_ 792 EL_RRPositionLightSt 1;
BA_ "EventCommandSignal" SG_ 792 EL_RRPositionLightSt 0;
BA_ "GenSigSendType" SG_ 792 EL_RRPositionLightFaultSt 1;
BA_ "EventCommandSignal" SG_ 792 EL_RRPositionLightFaultSt 0;
BA_ "GenSigSendType" SG_ 792 EL_RearFogLightSt 1;
BA_ "EventCommandSignal" SG_ 792 EL_RearFogLightSt 0;
BA_ "GenSigSendType" SG_ 792 EL_RearFogLightFaultSt 1;
BA_ "EventCommandSignal" SG_ 792 EL_RearFogLightFaultSt 0;
BA_ "GenSigSendType" SG_ 792 EL_RLTurnLightSt 1;
BA_ "EventCommandSignal" SG_ 792 EL_RLTurnLightSt 0;
BA_ "GenSigSendType" SG_ 792 EL_RLTurnLightFaultSt 1;
BA_ "EventCommandSignal" SG_ 792 EL_RLTurnLightFaultSt 0;
BA_ "GenSigSendType" SG_ 792 EL_RRTurnLightSt 1;
BA_ "EventCommandSignal" SG_ 792 EL_RRTurnLightSt 0;
BA_ "GenSigSendType" SG_ 792 EL_RRTurnLightFaultSt 1;
BA_ "EventCommandSignal" SG_ 792 EL_RRTurnLightFaultSt 0;
BA_ "GenSigSendType" SG_ 792 LCK_RearLeftDoorLockAction 1;
BA_ "EventCommandSignal" SG_ 792 LCK_RearLeftDoorLockAction 0;
BA_ "GenSigSendType" SG_ 616 EEM_LvElecEgySt 1;
BA_ "GatewayedSignals" SG_ 616 EEM_LvElecEgySt 0;
BA_ "EventCommandSignal" SG_ 616 EEM_LvElecEgySt 0;
BA_ "Remark" SG_ 616 EEM_LvElecEgySt "<E2E_Group1>

[E2E_Trigger]";
BA_ "Remark" SG_ 616 UMM_FrontPassengerSeatSt "<E2E_Group1>";
BA_ "GatewayedSignals" SG_ 616 UMM_FrontPassengerSeatSt 1;
BA_ "GenSigSendType" SG_ 616 UMM_FrontPassengerSeatSt 1;
BA_ "Remark" SG_ 616 UMM_EmergencyWarning "<E2E_Group1>";
BA_ "GenSigSendType" SG_ 616 UMM_EmergencyWarning 1;
BA_ "EventCommandSignal" SG_ 616 UMM_EmergencyWarning 0;
BA_ "Remark" SG_ 616 UINM_BrakeSWSt "<E2E_Group1>";
BA_ "GenSigSendType" SG_ 616 UINM_BrakeSWSt 1;
BA_ "EventCommandSignal" SG_ 616 UINM_BrakeSWSt 0;
BA_ "Remark" SG_ 616 UMM_OpIndicationWarning "<E2E_Group1>";
BA_ "GenSigSendType" SG_ 616 UMM_OpIndicationWarning 1;
BA_ "EventCommandSignal" SG_ 616 UMM_OpIndicationWarning 0;
BA_ "Remark" SG_ 616 UMM_UsageModeSt "<E2E_Group1>";
BA_ "GenSigSendType" SG_ 616 UMM_UsageModeSt 1;
BA_ "EventCommandSignal" SG_ 616 UMM_UsageModeSt 0;
BA_ "Remark" SG_ 616 UINM_BrakeSWNCSt "<E2E_Group1>";
BA_ "GenSigSendType" SG_ 616 UINM_BrakeSWNCSt 1;
BA_ "EventCommandSignal" SG_ 616 UINM_BrakeSWNCSt 0;
BA_ "Remark" SG_ 616 UINM_BrakeSWNOSt "<E2E_Group1>";
BA_ "GenSigSendType" SG_ 616 UINM_BrakeSWNOSt 1;
BA_ "EventCommandSignal" SG_ 616 UINM_BrakeSWNOSt 0;
BA_ "Remark" SG_ 616 UMM_ReadyForbidWarning "<E2E_Group1>";
BA_ "GenSigSendType" SG_ 616 UMM_ReadyForbidWarning 1;
BA_ "EventCommandSignal" SG_ 616 UMM_ReadyForbidWarning 0;
BA_ "Remark" SG_ 616 UMM_PowerKeepMode "<E2E_Group1>";
BA_ "GenSigSendType" SG_ 616 UMM_PowerKeepMode 1;
BA_ "EventCommandSignal" SG_ 616 UMM_PowerKeepMode 0;
BA_ "Remark" SG_ 616 UMM_PowerOffEnable "<E2E_Group1>";
BA_ "GenSigSendType" SG_ 616 UMM_PowerOffEnable 1;
BA_ "EventCommandSignal" SG_ 616 UMM_PowerOffEnable 0;
BA_ "Remark" SG_ 616 UMM_PowerKeepEnable "<E2E_Group1>";
BA_ "GenSigSendType" SG_ 616 UMM_PowerKeepEnable 1;
BA_ "EventCommandSignal" SG_ 616 UMM_PowerKeepEnable 0;
BA_ "Remark" SG_ 616 UMM_DriverSeatSt "<E2E_Group1>";
BA_ "GenSigSendType" SG_ 616 UMM_DriverSeatSt 1;
BA_ "EventCommandSignal" SG_ 616 UMM_DriverSeatSt 0;
BA_ "Remark" SG_ 616 VMM_VehModeSt "<E2E_Group2>";
BA_ "GenSigStartValue" SG_ 616 VMM_VehModeSt 15;
BA_ "GenSigInvalidValue" SG_ 616 VMM_VehModeSt 15;
BA_ "GenSigSendType" SG_ 616 VMM_VehModeSt 1;
BA_ "EventCommandSignal" SG_ 616 VMM_VehModeSt 0;
BA_ "GenSigTimeoutValue" SG_ 616 VMM_VehModeSt 15;
BA_ "Remark" SG_ 616 VMM_OTAModeSt "<E2E_Group2>";
BA_ "GenSigStartValue" SG_ 616 VMM_OTAModeSt 2;
BA_ "GenSigInvalidValue" SG_ 616 VMM_OTAModeSt 2;
BA_ "GenSigSendType" SG_ 616 VMM_OTAModeSt 1;
BA_ "EventCommandSignal" SG_ 616 VMM_OTAModeSt 0;
BA_ "GenSigTimeoutValue" SG_ 616 VMM_OTAModeSt 2;
BA_ "GenSigSendType" SG_ 616 IPDS_EnablePowerSup 1;
BA_ "EventCommandSignal" SG_ 616 IPDS_EnablePowerSup 0;
BA_ "GenSigSendType" SG_ 616 EEM_LdCtlLv 0;
BA_ "EventCommandSignal" SG_ 616 EEM_LdCtlLv 1;
BA_ "GenSigSendType" SG_ 616 EEM_LdCtlSt 1;
BA_ "EventCommandSignal" SG_ 616 EEM_LdCtlSt 0;
BA_ "GenSigSendType" SG_ 616 CCU_1_FreshnessValue 1;
BA_ "EventCommandSignal" SG_ 616 CCU_1_FreshnessValue 0;
BA_ "GenSigSendType" SG_ 616 CCU_1_MAC_Check 1;
BA_ "EventCommandSignal" SG_ 616 CCU_1_MAC_Check 0;
BA_ "GenSigSendType" SG_ 816 AQM_FreshPopReq 1;
BA_ "EventCommandSignal" SG_ 816 AQM_FreshPopReq 0;
BA_ "GenSigSendType" SG_ 816 AQM_CO2CleanReq 1;
BA_ "EventCommandSignal" SG_ 816 AQM_CO2CleanReq 0;
BA_ "EventCommandSignal" SG_ 816 HVAC_InCarAutoVentilationSt 0;
BA_ "GenSigSendType" SG_ 816 HVAC_InCarAutoVentilationSt 1;
BA_ "GenSigSendType" SG_ 816 HVAC_RearDefrostSt 1;
BA_ "EventCommandSignal" SG_ 816 HVAC_RearDefrostSt 0;
BA_ "GenSigSendType" SG_ 816 HVAC_ACSt 1;
BA_ "EventCommandSignal" SG_ 816 HVAC_ACSt 0;
BA_ "GenSigSendType" SG_ 816 HVAC_ACmaxSt 1;
BA_ "EventCommandSignal" SG_ 816 HVAC_ACmaxSt 0;
BA_ "GenSigStartValue" SG_ 816 HVAC_AutoDefCfgSt 2;
BA_ "EventCommandSignal" SG_ 816 HVAC_AutoDefCfgSt 0;
BA_ "GenSigStartValue" SG_ 816 HVAC_TimedVentilationSt 1;
BA_ "EventCommandSignal" SG_ 816 HVAC_TimedVentilationSt 0;
BA_ "GenSigSendType" SG_ 816 HVAC_DualSyncSt 1;
BA_ "EventCommandSignal" SG_ 816 HVAC_DualSyncSt 0;
BA_ "GenSigSendType" SG_ 816 HVAC_AutoSt 1;
BA_ "EventCommandSignal" SG_ 816 HVAC_AutoSt 0;
BA_ "GenSigSendType" SG_ 816 HVAC_WindExitMode 1;
BA_ "EventCommandSignal" SG_ 816 HVAC_WindExitMode 0;
BA_ "GenSigSendType" SG_ 816 HVAC_AirCirculationSt 1;
BA_ "EventCommandSignal" SG_ 816 HVAC_AirCirculationSt 0;
BA_ "GenSigSendType" SG_ 816 HVAC_PopUpDisplayReq 1;
BA_ "EventCommandSignal" SG_ 816 HVAC_PopUpDisplayReq 0;
BA_ "GenSigSendType" SG_ 816 HVAC_PopupDisplayReq2 1;
BA_ "EventCommandSignal" SG_ 816 HVAC_PopupDisplayReq2 0;
BA_ "GenSigSendType" SG_ 816 AQM_IonPopReq 1;
BA_ "EventCommandSignal" SG_ 816 AQM_IonPopReq 0;
BA_ "GenSigStartValue" SG_ 816 HVAC_DriverTempSelect 31;
BA_ "GenSigSendType" SG_ 816 HVAC_DriverTempSelect 1;
BA_ "EventCommandSignal" SG_ 816 HVAC_DriverTempSelect 0;
BA_ "GenSigSendType" SG_ 816 AQM_IonMode 1;
BA_ "EventCommandSignal" SG_ 816 AQM_IonMode 0;
BA_ "GenSigSendType" SG_ 816 HVAC_WindExitSpd 1;
BA_ "EventCommandSignal" SG_ 816 HVAC_WindExitSpd 0;
BA_ "EventCommandSignal" SG_ 816 HVAC_ECOSt 0;
BA_ "GenSigInvalidValue" SG_ 816 HVAC_WindExitSpdPercent 127;
BA_ "EventCommandSignal" SG_ 816 HVAC_WindExitSpdPercent 0;
BA_ "GenSigInvalidValue" SG_ 816 HVAC_PTCPwrConsmp 1023;
BA_ "GenSigSendType" SG_ 816 HVAC_PTCPwrConsmp 1;
BA_ "EventCommandSignal" SG_ 816 HVAC_PTCPwrConsmp 0;
BA_ "GenSigStartValue" SG_ 816 HVAC_PsnTempSelect 31;
BA_ "GenSigSendType" SG_ 816 HVAC_PsnTempSelect 1;
BA_ "EventCommandSignal" SG_ 816 HVAC_PsnTempSelect 0;
BA_ "GenSigSendType" SG_ 816 HVAC_PTCWaterTempWarn 1;
BA_ "EventCommandSignal" SG_ 816 HVAC_PTCWaterTempWarn 0;
BA_ "GenSigStartValue" SG_ 816 HVAC_ComfortCfgSt 1;
BA_ "GenSigSendType" SG_ 816 HVAC_ComfortCfgSt 1;
BA_ "EventCommandSignal" SG_ 816 HVAC_ComfortCfgSt 0;
BA_ "GenSigStartValue" SG_ 816 HVAC_AirCirCfgSt 1;
BA_ "GenSigSendType" SG_ 816 HVAC_AirCirCfgSt 1;
BA_ "EventCommandSignal" SG_ 816 HVAC_AirCirCfgSt 0;
BA_ "GenSigStartValue" SG_ 816 HVAC_PTCOutletTargetTemp 25;
BA_ "GenSigSendType" SG_ 816 HVAC_PTCOutletTargetTemp 1;
BA_ "EventCommandSignal" SG_ 816 HVAC_PTCOutletTargetTemp 0;
BA_ "GenSigStartValue" SG_ 816 HVAC_AirQualitySenSt 1;
BA_ "GenSigSendType" SG_ 816 HVAC_AirQualitySenSt 1;
BA_ "EventCommandSignal" SG_ 816 HVAC_AirQualitySenSt 0;
BA_ "GenSigStartValue" SG_ 816 HVAC_FanspeedCfgSt 2;
BA_ "GenSigSendType" SG_ 816 HVAC_FanspeedCfgSt 1;
BA_ "EventCommandSignal" SG_ 816 HVAC_FanspeedCfgSt 0;
BA_ "GenSigSendType" SG_ 816 HVAC_SceneDisplayReq 1;
BA_ "EventCommandSignal" SG_ 816 HVAC_SceneDisplayReq 0;
BA_ "GenSigSendType" SG_ 816 HVAC_EvapratorSelfCleanSt 1;
BA_ "EventCommandSignal" SG_ 816 HVAC_EvapratorSelfCleanSt 0;
BA_ "GenSigSendType" SG_ 816 HVAC_SolarFeaturesCfgSt 1;
BA_ "EventCommandSignal" SG_ 816 HVAC_SolarFeaturesCfgSt 0;
BA_ "GenSigStartValue" SG_ 816 HVAC_CorrectedExterTemp 120;
BA_ "GenSigSendType" SG_ 816 HVAC_CorrectedExterTemp 1;
BA_ "EventCommandSignal" SG_ 816 HVAC_CorrectedExterTemp 0;
BA_ "GenSigSendType" SG_ 816 HVAC_CorrectedExterTempVD 1;
BA_ "EventCommandSignal" SG_ 816 HVAC_CorrectedExterTempVD 0;
BA_ "GenSigSendType" SG_ 816 HVAC_DualCircuSt 1;
BA_ "EventCommandSignal" SG_ 816 HVAC_DualCircuSt 0;
BA_ "GenSigSendType" SG_ 816 HVAC_CondDefSt 1;
BA_ "EventCommandSignal" SG_ 816 HVAC_CondDefSt 0;
BA_ "GenSigSendType" SG_ 816 AQM_PM25CleanReq 1;
BA_ "EventCommandSignal" SG_ 816 AQM_PM25CleanReq 0;
BA_ "GenSigSendType" SG_ 816 AQM_FraganceRatioWarn 1;
BA_ "EventCommandSignal" SG_ 816 AQM_FraganceRatioWarn 0;
BA_ "GenSigSendType" SG_ 816 AQM_FraganceConcentrationReq 1;
BA_ "EventCommandSignal" SG_ 816 AQM_FraganceConcentrationReq 0;
BA_ "GenSigSendType" SG_ 816 AQM_FragTasteRemanentRatio 1;
BA_ "EventCommandSignal" SG_ 816 AQM_FragTasteRemanentRatio 0;
BA_ "GenSigSendType" SG_ 816 AQM_FraganceTaste 1;
BA_ "EventCommandSignal" SG_ 816 AQM_FraganceTaste 0;
BA_ "GenSigSendType" SG_ 816 AQM_FraganceConcentration 1;
BA_ "EventCommandSignal" SG_ 816 AQM_FraganceConcentration 0;
BA_ "GenSigSendType" SG_ 816 AQM_FraganceBoxID 1;
BA_ "EventCommandSignal" SG_ 816 AQM_FraganceBoxID 0;
BA_ "GenSigSendType" SG_ 816 AQM_FraganceTaste_Seek 1;
BA_ "EventCommandSignal" SG_ 816 AQM_FraganceTaste_Seek 0;
BA_ "GenSigSendType" SG_ 816 AQM_FraganceBoxLoad 1;
BA_ "EventCommandSignal" SG_ 816 AQM_FraganceBoxLoad 0;
BA_ "GenSigSendType" SG_ 816 HVAC_UnlockVentilationSt 1;
BA_ "EventCommandSignal" SG_ 816 HVAC_UnlockVentilationSt 0;
BA_ "GenSigSendType" SG_ 816 AQM_PM25CirReq 1;
BA_ "EventCommandSignal" SG_ 816 AQM_PM25CirReq 0;
BA_ "GenSigInvalidValue" SG_ 816 HVAC_ECPPwrConsump 2047;
BA_ "GenSigSendType" SG_ 816 HVAC_ECPPwrConsump 1;
BA_ "EventCommandSignal" SG_ 816 HVAC_ECPPwrConsump 0;
BA_ "GenSigSendType" SG_ 288 PWL_LockAutoWinCloseFunCfgSt 0;
BA_ "EventCommandSignal" SG_ 288 PWL_LockAutoWinCloseFunCfgSt 1;
BA_ "GenSigSendType" SG_ 288 PWL_PowerWinOpenWarn 0;
BA_ "EventCommandSignal" SG_ 288 PWL_PowerWinOpenWarn 1;
BA_ "GenSigSendType" SG_ 825 RLS_RainfallLevel 1;
BA_ "GenSigStartValue" SG_ 825 RLS_RainfallLevel 14;
BA_ "GatewayedSignals" SG_ 825 RLS_RainfallLevel 0;
BA_ "EventCommandSignal" SG_ 825 RLS_RainfallLevel 0;
BA_ "Remark" SG_ 825 RLS_RainfallLevel "<E2E_Group1>

[E2E_Trigger]";
BA_ "GenSigSendType" SG_ 825 RLS_RSErr 1;
BA_ "GatewayedSignals" SG_ 825 RLS_RSErr 0;
BA_ "EventCommandSignal" SG_ 825 RLS_RSErr 0;
BA_ "Remark" SG_ 825 RLS_RSErr "<E2E_Group1>

[E2E_Trigger]";
BA_ "GenSigSendType" SG_ 825 RLS_LSErr 1;
BA_ "GatewayedSignals" SG_ 825 RLS_LSErr 0;
BA_ "EventCommandSignal" SG_ 825 RLS_LSErr 0;
BA_ "Remark" SG_ 825 RLS_LSErr "<E2E_Group1>

[E2E_Trigger]";
BA_ "GenSigSendType" SG_ 825 RLS_WiperSpd 1;
BA_ "GatewayedSignals" SG_ 825 RLS_WiperSpd 0;
BA_ "EventCommandSignal" SG_ 825 RLS_WiperSpd 0;
BA_ "Remark" SG_ 825 RLS_WiperSpd "<E2E_Group1>

[E2E_Trigger]";
BA_ "GenSigSendType" SG_ 825 RLS_LampOnReqValid 1;
BA_ "GatewayedSignals" SG_ 825 RLS_LampOnReqValid 0;
BA_ "EventCommandSignal" SG_ 825 RLS_LampOnReqValid 0;
BA_ "Remark" SG_ 825 RLS_LampOnReqValid "<E2E_Group1>

[E2E_Trigger]";
BA_ "GenSigSendType" SG_ 825 RLS_LightOnReq 1;
BA_ "GatewayedSignals" SG_ 825 RLS_LightOnReq 0;
BA_ "EventCommandSignal" SG_ 825 RLS_LightOnReq 0;
BA_ "Remark" SG_ 825 RLS_LightOnReq "<E2E_Group1>

[E2E_Trigger]";
BA_ "GenSigSendType" SG_ 825 SSW_RLSeatAutoModeCfgSt 1;
BA_ "GatewayedSignals" SG_ 825 SSW_RLSeatAutoModeCfgSt 0;
BA_ "EventCommandSignal" SG_ 825 SSW_RLSeatAutoModeCfgSt 0;
BA_ "GenSigSendType" SG_ 825 SSW_RRSeatAutoModeCfgSt 1;
BA_ "GatewayedSignals" SG_ 825 SSW_RRSeatAutoModeCfgSt 0;
BA_ "EventCommandSignal" SG_ 825 SSW_RRSeatAutoModeCfgSt 0;
BA_ "GenSigSendType" SG_ 825 SSW_FRSeatAutoModeCfgSt 1;
BA_ "EventCommandSignal" SG_ 825 SSW_FRSeatAutoModeCfgSt 0;
BA_ "GenSigSendType" SG_ 825 SSW_FLSeatAutoModeCfgSt 1;
BA_ "EventCommandSignal" SG_ 825 SSW_FLSeatAutoModeCfgSt 0;
BA_ "GenSigSendType" SG_ 825 SSW_FLSeatHeatModeSt 1;
BA_ "EventCommandSignal" SG_ 825 SSW_FLSeatHeatModeSt 0;
BA_ "GenSigSendType" SG_ 825 MR_MirrorAutoFoldFuncCfgSt 1;
BA_ "EventCommandSignal" SG_ 825 MR_MirrorAutoFoldFuncCfgSt 0;
BA_ "GenSigSendType" SG_ 825 MR_MirrorAngleDipFuncCfgSt 1;
BA_ "EventCommandSignal" SG_ 825 MR_MirrorAngleDipFuncCfgSt 0;
BA_ "GenSigSendType" SG_ 825 SSW_EasyEntryExitFuncCfgSt 1;
BA_ "EventCommandSignal" SG_ 825 SSW_EasyEntryExitFuncCfgSt 0;
BA_ "GenSigSendType" SG_ 825 SSW_SeatNapModePosSt 1;
BA_ "EventCommandSignal" SG_ 825 SSW_SeatNapModePosSt 0;
BA_ "GenSigSendType" SG_ 825 SSW_PosSaveRecallPopUpReq 1;
BA_ "EventCommandSignal" SG_ 825 SSW_PosSaveRecallPopUpReq 0;
BA_ "GenSigSendType" SG_ 825 SSW_SeatNapPopUpReq 1;
BA_ "EventCommandSignal" SG_ 825 SSW_SeatNapPopUpReq 0;
BA_ "GenSigSendType" SG_ 825 SSW_FRSeatHeatModeSt 1;
BA_ "EventCommandSignal" SG_ 825 SSW_FRSeatHeatModeSt 0;
BA_ "GenSigSendType" SG_ 825 WW_FwpFaultSt 1;
BA_ "EventCommandSignal" SG_ 825 WW_FwpFaultSt 0;
BA_ "GenSigSendType" SG_ 825 WW_RwpFaultSt 1;
BA_ "EventCommandSignal" SG_ 825 WW_RwpFaultSt 0;
BA_ "GenSigSendType" SG_ 825 WW_FwshFaultSt 1;
BA_ "EventCommandSignal" SG_ 825 WW_FwshFaultSt 0;
BA_ "GenSigSendType" SG_ 825 WW_RwshFaultSt 1;
BA_ "EventCommandSignal" SG_ 825 WW_RwshFaultSt 0;
BA_ "GenSigSendType" SG_ 825 WW_FwpAutoModeSt 1;
BA_ "EventCommandSignal" SG_ 825 WW_FwpAutoModeSt 0;
BA_ "GenSigSendType" SG_ 825 SSW_FRSeatVentSt 1;
BA_ "EventCommandSignal" SG_ 825 SSW_FRSeatVentSt 0;
BA_ "GenSigSendType" SG_ 825 SSW_SeatNapModeSt 1;
BA_ "EventCommandSignal" SG_ 825 SSW_SeatNapModeSt 0;
BA_ "GenSigStartValue" SG_ 825 MR_LeftMirrorXCurrentPst 255;
BA_ "GenSigInvalidValue" SG_ 825 MR_LeftMirrorXCurrentPst 255;
BA_ "GenSigSendType" SG_ 825 MR_LeftMirrorXCurrentPst 1;
BA_ "EventCommandSignal" SG_ 825 MR_LeftMirrorXCurrentPst 0;
BA_ "GenSigStartValue" SG_ 825 MR_LeftMirrorYCurrentPst 255;
BA_ "GenSigInvalidValue" SG_ 825 MR_LeftMirrorYCurrentPst 255;
BA_ "GenSigSendType" SG_ 825 MR_LeftMirrorYCurrentPst 1;
BA_ "EventCommandSignal" SG_ 825 MR_LeftMirrorYCurrentPst 0;
BA_ "GenSigStartValue" SG_ 825 MR_RightMirrorXCurrentPst 255;
BA_ "GenSigInvalidValue" SG_ 825 MR_RightMirrorXCurrentPst 255;
BA_ "GenSigSendType" SG_ 825 MR_RightMirrorXCurrentPst 1;
BA_ "EventCommandSignal" SG_ 825 MR_RightMirrorXCurrentPst 0;
BA_ "GenSigStartValue" SG_ 825 MR_RightMirrorYCurrentPst 255;
BA_ "GenSigInvalidValue" SG_ 825 MR_RightMirrorYCurrentPst 255;
BA_ "GenSigSendType" SG_ 825 MR_RightMirrorYCurrentPst 1;
BA_ "EventCommandSignal" SG_ 825 MR_RightMirrorYCurrentPst 0;
BA_ "GenSigStartValue" SG_ 825 SSW_FLSeatSlideCurrentPst 255;
BA_ "GenSigInvalidValue" SG_ 825 SSW_FLSeatSlideCurrentPst 255;
BA_ "GenSigSendType" SG_ 825 SSW_FLSeatSlideCurrentPst 1;
BA_ "EventCommandSignal" SG_ 825 SSW_FLSeatSlideCurrentPst 0;
BA_ "GenSigStartValue" SG_ 825 SSW_FLSeatHeightCurrentPst 255;
BA_ "GenSigInvalidValue" SG_ 825 SSW_FLSeatHeightCurrentPst 255;
BA_ "GenSigSendType" SG_ 825 SSW_FLSeatHeightCurrentPst 1;
BA_ "EventCommandSignal" SG_ 825 SSW_FLSeatHeightCurrentPst 0;
BA_ "GenSigStartValue" SG_ 825 SSW_FLSeatBackrestCurrentPst 255;
BA_ "GenSigInvalidValue" SG_ 825 SSW_FLSeatBackrestCurrentPst 255;
BA_ "GenSigSendType" SG_ 825 SSW_FLSeatBackrestCurrentPst 1;
BA_ "EventCommandSignal" SG_ 825 SSW_FLSeatBackrestCurrentPst 0;
BA_ "GenSigStartValue" SG_ 825 SSW_FLSeatTiltCurrentPst 255;
BA_ "GenSigInvalidValue" SG_ 825 SSW_FLSeatTiltCurrentPst 255;
BA_ "GenSigSendType" SG_ 825 SSW_FLSeatTiltCurrentPst 1;
BA_ "EventCommandSignal" SG_ 825 SSW_FLSeatTiltCurrentPst 0;
BA_ "GenSigStartValue" SG_ 825 SSW_SteeringAngleCurrentPst 255;
BA_ "GenSigInvalidValue" SG_ 825 SSW_SteeringAngleCurrentPst 255;
BA_ "GenSigSendType" SG_ 825 SSW_SteeringAngleCurrentPst 1;
BA_ "EventCommandSignal" SG_ 825 SSW_SteeringAngleCurrentPst 0;
BA_ "GenSigStartValue" SG_ 825 SSW_SteeringExtentCurrentPst 255;
BA_ "GenSigInvalidValue" SG_ 825 SSW_SteeringExtentCurrentPst 255;
BA_ "GenSigSendType" SG_ 825 SSW_SteeringExtentCurrentPst 1;
BA_ "EventCommandSignal" SG_ 825 SSW_SteeringExtentCurrentPst 0;
BA_ "GenSigSendType" SG_ 825 SSW_PSCSOpeSt 1;
BA_ "EventCommandSignal" SG_ 825 SSW_PSCSOpeSt 0;
BA_ "GenSigSendType" SG_ 825 WinVentilationReqExculFb 1;
BA_ "EventCommandSignal" SG_ 825 WinVentilationReqExculFb 0;
BA_ "GenSigSendType" SG_ 825 SSW_FLSeatVentModeSt 1;
BA_ "EventCommandSignal" SG_ 825 SSW_FLSeatVentModeSt 0;
BA_ "GenSigSendType" SG_ 825 SSW_FRSeatHeatingSt 1;
BA_ "EventCommandSignal" SG_ 825 SSW_FRSeatHeatingSt 0;
BA_ "GenSigSendType" SG_ 825 SSW_FRSeatVentModeSt 1;
BA_ "EventCommandSignal" SG_ 825 SSW_FRSeatVentModeSt 0;
BA_ "GenSigStartValue" SG_ 825 SSW_FRSeatSlideCurrentPst 255;
BA_ "GenSigInvalidValue" SG_ 825 SSW_FRSeatSlideCurrentPst 255;
BA_ "GenSigSendType" SG_ 825 SSW_FRSeatSlideCurrentPst 1;
BA_ "EventCommandSignal" SG_ 825 SSW_FRSeatSlideCurrentPst 0;
BA_ "GenSigStartValue" SG_ 825 SSW_FRSeatHeightCurrentPst 255;
BA_ "GenSigInvalidValue" SG_ 825 SSW_FRSeatHeightCurrentPst 255;
BA_ "GenSigSendType" SG_ 825 SSW_FRSeatHeightCurrentPst 1;
BA_ "EventCommandSignal" SG_ 825 SSW_FRSeatHeightCurrentPst 0;
BA_ "GenSigStartValue" SG_ 825 SSW_FRSeatBackrestCurrentPst 255;
BA_ "GenSigInvalidValue" SG_ 825 SSW_FRSeatBackrestCurrentPst 255;
BA_ "GenSigSendType" SG_ 825 SSW_FRSeatBackrestCurrentPst 1;
BA_ "EventCommandSignal" SG_ 825 SSW_FRSeatBackrestCurrentPst 0;
BA_ "GenSigStartValue" SG_ 825 SSW_FRSeatTiltCurrentPst 255;
BA_ "GenSigInvalidValue" SG_ 825 SSW_FRSeatTiltCurrentPst 255;
BA_ "GenSigSendType" SG_ 825 SSW_FRSeatTiltCurrentPst 1;
BA_ "EventCommandSignal" SG_ 825 SSW_FRSeatTiltCurrentPst 0;
BA_ "GenSigStartValue" SG_ 825 SSW_FLSeatCushionCurrentPst 255;
BA_ "GenSigInvalidValue" SG_ 825 SSW_FLSeatCushionCurrentPst 255;
BA_ "GenSigSendType" SG_ 825 SSW_FLSeatCushionCurrentPst 1;
BA_ "EventCommandSignal" SG_ 825 SSW_FLSeatCushionCurrentPst 0;
BA_ "GenSigStartValue" SG_ 825 SSW_FRSeatCushionCurrentPst 255;
BA_ "GenSigInvalidValue" SG_ 825 SSW_FRSeatCushionCurrentPst 255;
BA_ "GenSigSendType" SG_ 825 SSW_FRSeatCushionCurrentPst 1;
BA_ "EventCommandSignal" SG_ 825 SSW_FRSeatCushionCurrentPst 0;
BA_ "GenSigStartValue" SG_ 825 SSW_FLSeatOttomanCurrentPst 255;
BA_ "GenSigInvalidValue" SG_ 825 SSW_FLSeatOttomanCurrentPst 255;
BA_ "GenSigSendType" SG_ 825 SSW_FLSeatOttomanCurrentPst 1;
BA_ "EventCommandSignal" SG_ 825 SSW_FLSeatOttomanCurrentPst 0;
BA_ "GenSigStartValue" SG_ 825 SSW_FRSeatOttomanCurrentPst 255;
BA_ "GenSigInvalidValue" SG_ 825 SSW_FRSeatOttomanCurrentPst 255;
BA_ "GenSigSendType" SG_ 825 SSW_FRSeatOttomanCurrentPst 1;
BA_ "EventCommandSignal" SG_ 825 SSW_FRSeatOttomanCurrentPst 0;
BA_ "GenSigStartValue" SG_ 825 PWL_FLWinCurrentPst 255;
BA_ "GenSigSendType" SG_ 825 PWL_FLWinCurrentPst 1;
BA_ "EventCommandSignal" SG_ 825 PWL_FLWinCurrentPst 0;
BA_ "GenSigStartValue" SG_ 825 PWL_FRWinCurrentPst 255;
BA_ "GenSigSendType" SG_ 825 PWL_FRWinCurrentPst 1;
BA_ "EventCommandSignal" SG_ 825 PWL_FRWinCurrentPst 0;
BA_ "GenSigStartValue" SG_ 825 PWL_RLWinCurrentPst 255;
BA_ "GenSigSendType" SG_ 825 PWL_RLWinCurrentPst 1;
BA_ "EventCommandSignal" SG_ 825 PWL_RLWinCurrentPst 0;
BA_ "GenSigStartValue" SG_ 825 PWL_RRWinCurrentPst 255;
BA_ "GenSigSendType" SG_ 825 PWL_RRWinCurrentPst 1;
BA_ "EventCommandSignal" SG_ 825 PWL_RRWinCurrentPst 0;
BA_ "GenSigSendType" SG_ 825 PWL_FLWinCurrentOpeSt 1;
BA_ "EventCommandSignal" SG_ 825 PWL_FLWinCurrentOpeSt 0;
BA_ "GenSigSendType" SG_ 825 PWL_FRWinCurrentOpeSt 1;
BA_ "EventCommandSignal" SG_ 825 PWL_FRWinCurrentOpeSt 0;
BA_ "GenSigSendType" SG_ 825 PWL_RLWinCurrentOpeSt 1;
BA_ "EventCommandSignal" SG_ 825 PWL_RLWinCurrentOpeSt 0;
BA_ "GenSigSendType" SG_ 825 PWL_RRWinCurrentOpeSt 1;
BA_ "EventCommandSignal" SG_ 825 PWL_RRWinCurrentOpeSt 0;
BA_ "GenSigSendType" SG_ 825 WW_RainFallLevel 1;
BA_ "GatewayedSignals" SG_ 825 WW_RainFallLevel 1;
BA_ "EventCommandSignal" SG_ 825 WW_RainFallLevel 0;
BA_ "GenSigSendType" SG_ 825 WW_RLSWarning_Rain 1;
BA_ "EventCommandSignal" SG_ 825 WW_RLSWarning_Rain 0;
BA_ "EventCommandSignal" SG_ 825 PLG_TravelPst 0;
BA_ "EventCommandSignal" SG_ 825 PLG_SetPst 0;
BA_ "EventCommandSignal" SG_ 825 PLG_DoorSt 0;
BA_ "EventCommandSignal" SG_ 825 PLG_ModeSW 1;
BA_ "GenSigSendType" SG_ 291 WW_FWPInitAdjustSWPresent 0;
BA_ "GatewayedSignals" SG_ 291 WW_FWPInitAdjustSWPresent 0;
BA_ "EventCommandSignal" SG_ 291 WW_FWPInitAdjustSWPresent 1;
BA_ "Remark" SG_ 291 WW_FWPInitAdjustSWPresent "<E2E_Group1>

[E2E_Trigger]";
BA_ "GenSigSendType" SG_ 291 WW_RearCamWasherVRResp 0;
BA_ "GenSigInvalidValue" SG_ 291 WW_RearCamWasherVRResp 3;
BA_ "GatewayedSignals" SG_ 291 WW_RearCamWasherVRResp 0;
BA_ "EventCommandSignal" SG_ 291 WW_RearCamWasherVRResp 1;
BA_ "Remark" SG_ 291 WW_RearCamWasherVRResp "<E2E_Group1>

[E2E_Trigger]";
BA_ "GenSigSendType" SG_ 291 WW_RearCamWasherVKResp 0;
BA_ "GenSigInvalidValue" SG_ 291 WW_RearCamWasherVKResp 3;
BA_ "GatewayedSignals" SG_ 291 WW_RearCamWasherVKResp 0;
BA_ "EventCommandSignal" SG_ 291 WW_RearCamWasherVKResp 1;
BA_ "Remark" SG_ 291 WW_RearCamWasherVKResp "<E2E_Group1>

[E2E_Trigger]";
BA_ "GenSigSendType" SG_ 291 ATWS_ATWSAlarmReq 0;
BA_ "EventCommandSignal" SG_ 291 ATWS_ATWSAlarmReq 1;
BA_ "GenSigSendType" SG_ 291 ATWS_ATWSLEDIndCmd 0;
BA_ "EventCommandSignal" SG_ 291 ATWS_ATWSLEDIndCmd 1;
BA_ "GenSigSendType" SG_ 291 ATWS_ATWSSt 0;
BA_ "EventCommandSignal" SG_ 291 ATWS_ATWSSt 1;
BA_ "Remark" SG_ 291 WW_FrontWiperServiceMode "<NoneE2E_Group1>";
BA_ "GenSigStartValue" SG_ 291 WW_FrontWiperServiceMode 1;
BA_ "GenSigSendType" SG_ 291 WW_FrontWiperServiceMode 0;
BA_ "EventCommandSignal" SG_ 291 WW_FrontWiperServiceMode 1;
BA_ "Remark" SG_ 291 WW_RearWiperServiceMode "<NoneE2E_Group2>";
BA_ "GenSigStartValue" SG_ 291 WW_RearWiperServiceMode 1;
BA_ "GenSigSendType" SG_ 291 WW_RearWiperServiceMode 0;
BA_ "EventCommandSignal" SG_ 291 WW_RearWiperServiceMode 1;
BA_ "GenSigSendType" SG_ 291 HRN_HornDoorLookAckEnable 0;
BA_ "EventCommandSignal" SG_ 291 HRN_HornDoorLookAckEnable 1;
BA_ "GenSigSendType" SG_ 291 HRN_HornVehAckEnable 0;
BA_ "EventCommandSignal" SG_ 291 HRN_HornVehAckEnable 1;
BA_ "GenSigSendType" SG_ 291 WW_FWPIntLevelSt 0;
BA_ "EventCommandSignal" SG_ 291 WW_FWPIntLevelSt 1;
BA_ "GenSigSendType" SG_ 291 WW_FWPAutoLevelSt 0;
BA_ "EventCommandSignal" SG_ 291 WW_FWPAutoLevelSt 1;
BA_ "GenSigSendType" SG_ 291 WW_FrontAutoWiperEnable 0;
BA_ "EventCommandSignal" SG_ 291 WW_FrontAutoWiperEnable 1;
BA_ "GenSigSendType" SG_ 291 WW_FrontWiperVRResp 0;
BA_ "EventCommandSignal" SG_ 291 WW_FrontWiperVRResp 1;
BA_ "GenSigSendType" SG_ 291 WW_FrontWasherVRResp 0;
BA_ "EventCommandSignal" SG_ 291 WW_FrontWasherVRResp 1;
BA_ "GenSigStartValue" SG_ 291 ATWS_ATWSAlarmHistory 7;
BA_ "GenSigSendType" SG_ 291 ATWS_ATWSAlarmHistory 0;
BA_ "EventCommandSignal" SG_ 291 ATWS_ATWSAlarmHistory 1;
BA_ "GenSigSendType" SG_ 291 WW_FrontWiperCtrlSt 0;
BA_ "EventCommandSignal" SG_ 291 WW_FrontWiperCtrlSt 1;
BA_ "GenSigSendType" SG_ 291 WW_FrontAutoWiperPresent 0;
BA_ "EventCommandSignal" SG_ 291 WW_FrontAutoWiperPresent 1;
BA_ "GenSigSendType" SG_ 291 WW_RearWiperCtrlSt 0;
BA_ "EventCommandSignal" SG_ 291 WW_RearWiperCtrlSt 1;
BA_ "GenSigSendType" SG_ 291 WW_RearWiperPresent 0;
BA_ "EventCommandSignal" SG_ 291 WW_RearWiperPresent 1;
BA_ "GenSigSendType" SG_ 291 WW_RearWiperVRResp 0;
BA_ "EventCommandSignal" SG_ 291 WW_RearWiperVRResp 1;
BA_ "GenSigSendType" SG_ 291 WW_RearWasherVRResp 0;
BA_ "EventCommandSignal" SG_ 291 WW_RearWasherVRResp 1;
BA_ "GenSigSendType" SG_ 291 WW_FrontWiperCtrlSrc 0;
BA_ "EventCommandSignal" SG_ 291 WW_FrontWiperCtrlSrc 1;
BA_ "GenSigSendType" SG_ 291 WW_RearWiperCtrlSrc 0;
BA_ "EventCommandSignal" SG_ 291 WW_RearWiperCtrlSrc 1;
BA_ "GenSigSendType" SG_ 865 EL_SideBrkLightCtrlCmd 1;
BA_ "GatewayedSignals" SG_ 865 EL_SideBrkLightCtrlCmd 0;
BA_ "EventCommandSignal" SG_ 865 EL_SideBrkLightCtrlCmd 0;
BA_ "Remark" SG_ 865 EL_SideBrkLightCtrlCmd "<E2E_Group1>

[E2E_Trigger]";
BA_ "GenSigStartValue" SG_ 865 EL_HeadLightDelayEnable 1;
BA_ "GenSigSendType" SG_ 865 EL_HeadLightDelayEnable 1;
BA_ "EventCommandSignal" SG_ 865 EL_HeadLightDelayEnable 0;
BA_ "GenSigSendType" SG_ 865 EL_RLSWarning_Light 1;
BA_ "EventCommandSignal" SG_ 865 EL_RLSWarning_Light 0;
BA_ "GenSigSendType" SG_ 865 EL_LampOnWarningReq 1;
BA_ "EventCommandSignal" SG_ 865 EL_LampOnWarningReq 0;
BA_ "GenSigSendType" SG_ 865 IL_AutoDomeLightCfgSt 1;
BA_ "EventCommandSignal" SG_ 865 IL_AutoDomeLightCfgSt 0;
BA_ "GenSigSendType" SG_ 865 EL_WelcomeLightMode 1;
BA_ "EventCommandSignal" SG_ 865 EL_WelcomeLightMode 0;
BA_ "GenSigSendType" SG_ 865 EL_LightShowSt 1;
BA_ "EventCommandSignal" SG_ 865 EL_LightShowSt 0;
BA_ "GenSigSendType" SG_ 865 EL_HeadLightLevelingSwSt 1;
BA_ "EventCommandSignal" SG_ 865 EL_HeadLightLevelingSwSt 0;
BA_ "GenSigStartValue" SG_ 865 EL_ALSEnable 1;
BA_ "GenSigSendType" SG_ 865 EL_ALSEnable 1;
BA_ "EventCommandSignal" SG_ 865 EL_ALSEnable 0;
BA_ "GenSigSendType" SG_ 865 EL_LeftTurnLightStForDisp 1;
BA_ "EventCommandSignal" SG_ 865 EL_LeftTurnLightStForDisp 0;
BA_ "GenSigSendType" SG_ 865 EL_RightTurnLightStForDisp 1;
BA_ "EventCommandSignal" SG_ 865 EL_RightTurnLightStForDisp 0;
BA_ "GenSigSendType" SG_ 865 EL_PositionLightstForDisp 1;
BA_ "EventCommandSignal" SG_ 865 EL_PositionLightstForDisp 0;
BA_ "GenSigSendType" SG_ 865 EL_FrontFogLightStForDisp 1;
BA_ "EventCommandSignal" SG_ 865 EL_FrontFogLightStForDisp 0;
BA_ "GenSigSendType" SG_ 865 EL_RearFogLightStForDisp 1;
BA_ "EventCommandSignal" SG_ 865 EL_RearFogLightStForDisp 0;
BA_ "GenSigSendType" SG_ 865 EL_LowBeamStForDisp 1;
BA_ "EventCommandSignal" SG_ 865 EL_LowBeamStForDisp 0;
BA_ "GenSigSendType" SG_ 865 EL_HighBeamStForDisp 1;
BA_ "EventCommandSignal" SG_ 865 EL_HighBeamStForDisp 0;
BA_ "GenSigStartValue" SG_ 293 TPMS_FrontLeftTirePressure 255;
BA_ "GenSigSendType" SG_ 293 TPMS_FrontLeftTirePressure 1;
BA_ "EventCommandSignal" SG_ 293 TPMS_FrontLeftTirePressure 0;
BA_ "GenSigTimeoutValue" SG_ 293 TPMS_FrontLeftTirePressure 255;
BA_ "GenSigStartValue" SG_ 293 TPMS_FrontRightTirePressure 255;
BA_ "GenSigSendType" SG_ 293 TPMS_FrontRightTirePressure 1;
BA_ "EventCommandSignal" SG_ 293 TPMS_FrontRightTirePressure 0;
BA_ "GenSigTimeoutValue" SG_ 293 TPMS_FrontRightTirePressure 255;
BA_ "GenSigStartValue" SG_ 293 TPMS_RearRightTirePressure 255;
BA_ "GenSigSendType" SG_ 293 TPMS_RearRightTirePressure 1;
BA_ "EventCommandSignal" SG_ 293 TPMS_RearRightTirePressure 0;
BA_ "GenSigTimeoutValue" SG_ 293 TPMS_RearRightTirePressure 255;
BA_ "GenSigStartValue" SG_ 293 TPMS_RearLeftTirePressure 255;
BA_ "GenSigSendType" SG_ 293 TPMS_RearLeftTirePressure 1;
BA_ "EventCommandSignal" SG_ 293 TPMS_RearLeftTirePressure 0;
BA_ "GenSigTimeoutValue" SG_ 293 TPMS_RearLeftTirePressure 255;
BA_ "GenSigStartValue" SG_ 293 TPMS_FrontLeftTireTemperature 255;
BA_ "GenSigSendType" SG_ 293 TPMS_FrontLeftTireTemperature 1;
BA_ "EventCommandSignal" SG_ 293 TPMS_FrontLeftTireTemperature 0;
BA_ "GenSigTimeoutValue" SG_ 293 TPMS_FrontLeftTireTemperature 255;
BA_ "GenSigStartValue" SG_ 293 TPMS_FrontRightTireTemperature 255;
BA_ "GenSigSendType" SG_ 293 TPMS_FrontRightTireTemperature 1;
BA_ "EventCommandSignal" SG_ 293 TPMS_FrontRightTireTemperature 0;
BA_ "GenSigTimeoutValue" SG_ 293 TPMS_FrontRightTireTemperature 255;
BA_ "GenSigStartValue" SG_ 293 TPMS_RearRightTireTemperature 255;
BA_ "GenSigSendType" SG_ 293 TPMS_RearRightTireTemperature 1;
BA_ "EventCommandSignal" SG_ 293 TPMS_RearRightTireTemperature 0;
BA_ "GenSigTimeoutValue" SG_ 293 TPMS_RearRightTireTemperature 255;
BA_ "GenSigStartValue" SG_ 293 TPMS_RearLeftTireTemperature 255;
BA_ "GenSigSendType" SG_ 293 TPMS_RearLeftTireTemperature 1;
BA_ "EventCommandSignal" SG_ 293 TPMS_RearLeftTireTemperature 0;
BA_ "GenSigTimeoutValue" SG_ 293 TPMS_RearLeftTireTemperature 255;
BA_ "GenSigStartValue" SG_ 293 TPMS_FrontWheelRCP 4;
BA_ "GenSigSendType" SG_ 293 TPMS_FrontWheelRCP 0;
BA_ "EventCommandSignal" SG_ 293 TPMS_FrontWheelRCP 1;
BA_ "GenSigTimeoutValue" SG_ 293 TPMS_FrontWheelRCP 4;
BA_ "GenSigStartValue" SG_ 293 TPMS_RearWheelRCP 4;
BA_ "GenSigSendType" SG_ 293 TPMS_RearWheelRCP 0;
BA_ "EventCommandSignal" SG_ 293 TPMS_RearWheelRCP 1;
BA_ "GenSigTimeoutValue" SG_ 293 TPMS_RearWheelRCP 4;
BA_ "GenSigSendType" SG_ 293 TPMS_FrontLeftTireLowPressure 0;
BA_ "EventCommandSignal" SG_ 293 TPMS_FrontLeftTireLowPressure 1;
BA_ "GenSigSendType" SG_ 293 TPMS_FrontRightTireLowPressure 0;
BA_ "EventCommandSignal" SG_ 293 TPMS_FrontRightTireLowPressure 1;
BA_ "GenSigSendType" SG_ 293 TPMS_RearRightTireLowPressure 0;
BA_ "EventCommandSignal" SG_ 293 TPMS_RearRightTireLowPressure 1;
BA_ "GenSigSendType" SG_ 293 TPMS_RearLeftTireLowPressure 0;
BA_ "EventCommandSignal" SG_ 293 TPMS_RearLeftTireLowPressure 1;
BA_ "GenSigSendType" SG_ 293 TPMS_FrontLeftTireHighPressure 0;
BA_ "EventCommandSignal" SG_ 293 TPMS_FrontLeftTireHighPressure 1;
BA_ "GenSigSendType" SG_ 293 TPMS_FrontRightTireHighPressure 0;
BA_ "EventCommandSignal" SG_ 293 TPMS_FrontRightTireHighPressure 1;
BA_ "GenSigSendType" SG_ 293 TPMS_RearRightTireHighPressure 0;
BA_ "EventCommandSignal" SG_ 293 TPMS_RearRightTireHighPressure 1;
BA_ "GenSigSendType" SG_ 293 TPMS_RearLeftTireHighPressure 0;
BA_ "EventCommandSignal" SG_ 293 TPMS_RearLeftTireHighPressure 1;
BA_ "GenSigSendType" SG_ 293 TPMS_FrontLeftTireDelaPressure 0;
BA_ "EventCommandSignal" SG_ 293 TPMS_FrontLeftTireDelaPressure 1;
BA_ "GenSigSendType" SG_ 293 TPMS_FrontRightTireDelaPressure 0;
BA_ "EventCommandSignal" SG_ 293 TPMS_FrontRightTireDelaPressure 1;
BA_ "GenSigSendType" SG_ 293 TPMS_RearRightTireDelaPressure 0;
BA_ "EventCommandSignal" SG_ 293 TPMS_RearRightTireDelaPressure 1;
BA_ "GenSigSendType" SG_ 293 TPMS_RearLeftTireDelaPressure 0;
BA_ "EventCommandSignal" SG_ 293 TPMS_RearLeftTireDelaPressure 1;
BA_ "GenSigSendType" SG_ 293 TPMS_FLTireHighTemperature 0;
BA_ "EventCommandSignal" SG_ 293 TPMS_FLTireHighTemperature 1;
BA_ "GenSigSendType" SG_ 293 TPMS_FRTireHighTemperature 0;
BA_ "EventCommandSignal" SG_ 293 TPMS_FRTireHighTemperature 1;
BA_ "GenSigSendType" SG_ 293 TPMS_RRTireHighTemperature 0;
BA_ "EventCommandSignal" SG_ 293 TPMS_RRTireHighTemperature 1;
BA_ "GenSigSendType" SG_ 293 TPMS_RearLeftTireHighTemperature 0;
BA_ "EventCommandSignal" SG_ 293 TPMS_RearLeftTireHighTemperature 1;
BA_ "GenSigSendType" SG_ 293 TPMS_TireWarningLamp 0;
BA_ "EventCommandSignal" SG_ 293 TPMS_TireWarningLamp 1;
BA_ "GenSigSendType" SG_ 293 TPMS_FrontLeftSensorLowBattery 0;
BA_ "EventCommandSignal" SG_ 293 TPMS_FrontLeftSensorLowBattery 1;
BA_ "GenSigSendType" SG_ 293 TPMS_FrontRighSensorLowBattery 0;
BA_ "EventCommandSignal" SG_ 293 TPMS_FrontRighSensorLowBattery 1;
BA_ "GenSigSendType" SG_ 293 TPMS_RearRightSensorLowBattery 0;
BA_ "EventCommandSignal" SG_ 293 TPMS_RearRightSensorLowBattery 1;
BA_ "GenSigSendType" SG_ 293 TPMS_RearLeftSensorLowBattery 0;
BA_ "EventCommandSignal" SG_ 293 TPMS_RearLeftSensorLowBattery 1;
BA_ "GenSigSendType" SG_ 293 TPMS_FrontLeftSensorFailure 0;
BA_ "EventCommandSignal" SG_ 293 TPMS_FrontLeftSensorFailure 1;
BA_ "GenSigSendType" SG_ 293 TPMS_FrontRightSensorFailure 0;
BA_ "EventCommandSignal" SG_ 293 TPMS_FrontRightSensorFailure 1;
BA_ "GenSigSendType" SG_ 293 TPMS_RearRightSensorFailure 0;
BA_ "EventCommandSignal" SG_ 293 TPMS_RearRightSensorFailure 1;
BA_ "GenSigSendType" SG_ 293 TPMS_RearLeftSensorFailure 0;
BA_ "EventCommandSignal" SG_ 293 TPMS_RearLeftSensorFailure 1;
BA_ "GenSigSendType" SG_ 293 TPMS_FrontLeftSensorNotCalibrate 0;
BA_ "EventCommandSignal" SG_ 293 TPMS_FrontLeftSensorNotCalibrate 1;
BA_ "GenSigSendType" SG_ 293 TPMS_FRSensorNotCalibrate 0;
BA_ "EventCommandSignal" SG_ 293 TPMS_FRSensorNotCalibrate 1;
BA_ "GenSigSendType" SG_ 293 TPMS_RearRightSensorNotCalibrate 0;
BA_ "EventCommandSignal" SG_ 293 TPMS_RearRightSensorNotCalibrate 1;
BA_ "GenSigSendType" SG_ 293 TPMS_RearLeftSensorNotCalibrate 0;
BA_ "EventCommandSignal" SG_ 293 TPMS_RearLeftSensorNotCalibrate 1;
BA_ "GenSigSendType" SG_ 293 TPMS_FrontLeftSensorMute 0;
BA_ "EventCommandSignal" SG_ 293 TPMS_FrontLeftSensorMute 1;
BA_ "GenSigSendType" SG_ 293 TPMS_FrontRightSensorMute 0;
BA_ "EventCommandSignal" SG_ 293 TPMS_FrontRightSensorMute 1;
BA_ "GenSigSendType" SG_ 293 TPMS_RearRightSensorMute 0;
BA_ "EventCommandSignal" SG_ 293 TPMS_RearRightSensorMute 1;
BA_ "GenSigSendType" SG_ 293 TPMS_RearLeftSensorMute 0;
BA_ "EventCommandSignal" SG_ 293 TPMS_RearLeftSensorMute 1;
BA_ "GenSigSendType" SG_ 293 TPMS_SystemWarningLamp 0;
BA_ "EventCommandSignal" SG_ 293 TPMS_SystemWarningLamp 1;
BA_ "GenSigSendType" SG_ 294 LCK_DriverDoorAjarSt 0;
BA_ "EventCommandSignal" SG_ 294 LCK_DriverDoorAjarSt 1;
BA_ "GenSigSendType" SG_ 294 LCK_PassengerDoorAjarSt 0;
BA_ "EventCommandSignal" SG_ 294 LCK_PassengerDoorAjarSt 1;
BA_ "GenSigSendType" SG_ 294 LCK_DriverDoorLockSt 0;
BA_ "EventCommandSignal" SG_ 294 LCK_DriverDoorLockSt 1;
BA_ "GenSigSendType" SG_ 294 LCK_PassengerDoorLockSt 0;
BA_ "EventCommandSignal" SG_ 294 LCK_PassengerDoorLockSt 1;
BA_ "GenSigSendType" SG_ 294 LCK_VehicleDoorLockSt 0;
BA_ "EventCommandSignal" SG_ 294 LCK_VehicleDoorLockSt 1;
BA_ "GenSigSendType" SG_ 294 LCK_VehicleChildSaftyLockSt 0;
BA_ "EventCommandSignal" SG_ 294 LCK_VehicleChildSaftyLockSt 1;
BA_ "GenSigSendType" SG_ 294 LCK_VehicleChildSaftyLockedIndic 0;
BA_ "EventCommandSignal" SG_ 294 LCK_VehicleChildSaftyLockedIndic 1;
BA_ "SystemSignalLongSymbol" SG_ 294 LCK_VehicleChildSaftyLockedIndic "LCK_VehicleChildSaftyLockedIndicate";
BA_ "GenSigSendType" SG_ 294 LCK_VehicleDoorLockedIndicate 0;
BA_ "EventCommandSignal" SG_ 294 LCK_VehicleDoorLockedIndicate 1;
BA_ "GenSigSendType" SG_ 294 LCK_VehicleDoorUnlockedIndicate 0;
BA_ "EventCommandSignal" SG_ 294 LCK_VehicleDoorUnlockedIndicate 1;
BA_ "GenSigSendType" SG_ 294 LCK_LockOverHeatInhibit 0;
BA_ "EventCommandSignal" SG_ 294 LCK_LockOverHeatInhibit 1;
BA_ "GenSigSendType" SG_ 294 LCK_LockVehicleModeInhibit 0;
BA_ "EventCommandSignal" SG_ 294 LCK_LockVehicleModeInhibit 1;
BA_ "GenSigSendType" SG_ 294 LCK_LockEmergencyInhibit 0;
BA_ "EventCommandSignal" SG_ 294 LCK_LockEmergencyInhibit 1;
BA_ "GenSigSendType" SG_ 294 CCU_9_FreshnessValue 1;
BA_ "EventCommandSignal" SG_ 294 CCU_9_FreshnessValue 0;
BA_ "GenSigSendType" SG_ 294 CCU_9_MAC_Check 1;
BA_ "EventCommandSignal" SG_ 294 CCU_9_MAC_Check 0;
BA_ "GenSigSendType" SG_ 909 KAE_BLEChl7Connectingst 1;
BA_ "GatewayedSignals" SG_ 909 KAE_BLEChl7Connectingst 0;
BA_ "EventCommandSignal" SG_ 909 KAE_BLEChl7Connectingst 0;
BA_ "GenSigSendType" SG_ 909 LCK_FLPowerReleaseFailedRemind 1;
BA_ "EventCommandSignal" SG_ 909 LCK_FLPowerReleaseFailedRemind 0;
BA_ "GenSigSendType" SG_ 909 LCK_FRPowerReleaseFailedRemind 1;
BA_ "EventCommandSignal" SG_ 909 LCK_FRPowerReleaseFailedRemind 0;
BA_ "GenSigSendType" SG_ 909 LCK_RLPowerReleaseFailedRemind 1;
BA_ "EventCommandSignal" SG_ 909 LCK_RLPowerReleaseFailedRemind 0;
BA_ "GenSigSendType" SG_ 909 LCK_RRPowerReleaseFailedRemind 1;
BA_ "EventCommandSignal" SG_ 909 LCK_RRPowerReleaseFailedRemind 0;
BA_ "GenSigSendType" SG_ 909 LCK_HoodAjarSt 1;
BA_ "EventCommandSignal" SG_ 909 LCK_HoodAjarSt 0;
BA_ "GenSigSendType" SG_ 909 LCK_FrontLeftDoorAjarSt 1;
BA_ "EventCommandSignal" SG_ 909 LCK_FrontLeftDoorAjarSt 0;
BA_ "GenSigSendType" SG_ 909 LCK_FrontRightDoorAjarSt 1;
BA_ "EventCommandSignal" SG_ 909 LCK_FrontRightDoorAjarSt 0;
BA_ "GenSigSendType" SG_ 909 LCK_RearLeftDoorAjarSt 1;
BA_ "EventCommandSignal" SG_ 909 LCK_RearLeftDoorAjarSt 0;
BA_ "GenSigSendType" SG_ 909 LCK_RearRightDoorAjarSt 1;
BA_ "EventCommandSignal" SG_ 909 LCK_RearRightDoorAjarSt 0;
BA_ "GenSigSendType" SG_ 909 LCK_TrunkAjarSt 1;
BA_ "EventCommandSignal" SG_ 909 LCK_TrunkAjarSt 0;
BA_ "GenSigSendType" SG_ 909 LCK_FrontLeftDoorLockSt 1;
BA_ "EventCommandSignal" SG_ 909 LCK_FrontLeftDoorLockSt 0;
BA_ "GenSigSendType" SG_ 909 LCK_FrontRightDoorLockSt 1;
BA_ "EventCommandSignal" SG_ 909 LCK_FrontRightDoorLockSt 0;
BA_ "GenSigSendType" SG_ 909 LCK_RearLeftDoorLockSt 1;
BA_ "EventCommandSignal" SG_ 909 LCK_RearLeftDoorLockSt 0;
BA_ "GenSigSendType" SG_ 909 LCK_RearRightDoorLockSt 1;
BA_ "EventCommandSignal" SG_ 909 LCK_RearRightDoorLockSt 0;
BA_ "GenSigSendType" SG_ 909 LCK_RearLeftChildSaftyLockSt 1;
BA_ "EventCommandSignal" SG_ 909 LCK_RearLeftChildSaftyLockSt 0;
BA_ "GenSigSendType" SG_ 909 LCK_RearRightChildSaftyLockSt 1;
BA_ "EventCommandSignal" SG_ 909 LCK_RearRightChildSaftyLockSt 0;
BA_ "GenSigInvalidValue" SG_ 909 LCK_FrontLeftDoorHandlePosition 255;
BA_ "GenSigSendType" SG_ 909 LCK_FrontLeftDoorHandlePosition 1;
BA_ "EventCommandSignal" SG_ 909 LCK_FrontLeftDoorHandlePosition 0;
BA_ "GenSigInvalidValue" SG_ 909 LCK_FrontRightDoorHandlePosition 255;
BA_ "GenSigSendType" SG_ 909 LCK_FrontRightDoorHandlePosition 1;
BA_ "EventCommandSignal" SG_ 909 LCK_FrontRightDoorHandlePosition 0;
BA_ "GenSigInvalidValue" SG_ 909 LCK_RearLeftDoorHandlePosition 255;
BA_ "GenSigSendType" SG_ 909 LCK_RearLeftDoorHandlePosition 1;
BA_ "EventCommandSignal" SG_ 909 LCK_RearLeftDoorHandlePosition 0;
BA_ "GenSigInvalidValue" SG_ 909 LCK_RearRightDoorHandlePosition 255;
BA_ "GenSigSendType" SG_ 909 LCK_RearRightDoorHandlePosition 1;
BA_ "EventCommandSignal" SG_ 909 LCK_RearRightDoorHandlePosition 0;
SIG_GROUP_ 475 IDC_4_E2E 1 : ACU_FLSeatOttomanPosCtlReq IDC_4_Dummy2 Reserved1 ACU_HVACF_FDefrostBtnSt ACU_HVACF_FLTempIncBtnSt ACU_LeftMirrorYPosCtlReq ACU_FLSeatBackrestPosCtlReq ACU_SteeringExtentPosCtlReq ACU_FRSeatTiltPosCtlReq ACU_FRSeatOttomanPosCtlReq ACU_FRSeatHeightPosCtlReq ACU_FRSeatCushionPosCtlReq ACU_FLSeatCushionPosCtlReq ACU_FRSeatSlidePosCtlReq IDC_4_Dummy4 IDC_4_Dummy5 ACU_HVACF_ACBtnSt ACU_HVACFR_FanDecBtnSt ACU_FRSeatBackrestPosCtlReq ACU_FLSeatSlidePosCtlReq ACU_SteeringAnglePosCtlReq ACU_FLSeatHeightPosCtlReq ACU_HVACF_ACMaxBtnSt ACU_HVACF_FRTempDecBtnSt ACU_HVACF_CirBtnSt ACU_FLSeatTiltPosCtlReq ACU_RightMirrorYPosCtlReq ACU_HVAC_RearOnOffBtnSt ACU_HVACF_FLTempDecBtnSt ACU_HVACF_FRTempIncBtnSt ACU_HVAC_RearAutoModeBtnSt ACU_RightMirrorXPosCtlReq ACU_LeftMirrorXPosCtlReq ACU_HVACF_ECOBtnSt IDC_4_Counter ACU_HVACFR_FanIncBtnSt ACU_HVACF_IonBtnSt IDC_4_Dummy1 ACU_HVACF_DualSyncBtnSt ACU_HVACF_RDefrostBtnSt ACU_HVACFR_ModeBtnSt ACU_FRSeatOttomanExtentPosCtlReq ACU_FRSeatOttomanAnglePosCtlReq ACU_HVACFR_OffOnBtnSt ACU_HVACFR_AutoModeBtnSt IDC_4_CRC ACU_FLSeatOttomanAnglePosCtlReq ACU_FLSeatOttomanExtentPosCtlReq IDC_4_Dummy3 IDC_4_Dummy6 IDC_4_Dummy7;
SIG_GROUP_ 967 IDC_DMS_1_E2E 1 : IDC_DMS_1_Dummy12 IDC_DMS_1_Dummy13 DMS_YawnSt IDC_DMS_1_Dummy11 DMS_FaceIDVerifyResult IDC_DMS_1_Dummy1 DMS_DriverExpressionSt DMS_FaceIDStatus DMS_FaceIDRegisterResult DMS_FaceIDDeleteResult DMS_LeftEyeOpenSt DMS_RightEyeOpenSt DMS_MouthSt DMS_GlassWearSt DMS_DriverSmokeSt DMS_DriverTelephoneSt DMS_DriverHealthSt DMS_SeatRightmiddleSt DMS_SeatLeftmiddleSt DMS_FatigWarnSt DMS_DistrWarnSt DMS_PetSt DMS_ObjectSt DMS_CodriverSmokeSt DMS_CodriverExpressionSt DMS_LeftrearExpressionSt DMS_RigntrearExpressionSt DMS_MidrearExpressionSt DMS_LeftrearSmokeSt DMS_RigntrearSmokeSt DMS_MidrearSmokeSt DMS_CodriverTelephoneSt DMS_LeftrearTelephoneSt DMS_RigntrearTelephoneSt DMS_MidrearTelephoneSt DMS_SeatPositionID DMS_CodriverHealthSt DMS_LeftrearHealthSt DMS_RigntrearHealthSt DMS_MidrearHealthSt DMS_DriverFaceID DMS_FaceIDWelcomeMode DMS_FaceIDFailCause DMS_DriverFatigueSt DMS_DriverInterestsRegion DMS_SeatDriverSt DMS_DriverDistractionSt DMS_PersonCount DMS_SeatCodriverSt DMS_SeatMidmiddleSt DMS_PersonAge DMS_SeatLeftrearSt DMS_SeatRigntrearSt DMS_SeatMidrearSt DMS_PersonGender DMS_CarOwner DMS_DriverHandheartgesture DMS_CodriverHandheartgesture DMS_LeftrearHandheartgesture DMS_RigntrearHandheartgesture DMS_MidrearHandheartgesture DMS_DriverOKgesture DMS_CodriverOKgesture DMS_LeftrearOKgesture DMS_RigntrearOKgesture DMS_MidrearOKgesture DMS_DriverForefingercircleright DMS_CodriverForefingercirclerigh DMS_LeftrearForefingercirclerigh DMS_RigntrearForefingercirclerig DMS_MidrearForefingercircleright DMS_DriverForefingercircleleft DMS_CodriverForefingercircleleft DMS_LeftrearForefingercircleleft DMS_RigntrearForefingercirclelef DMS_MidrearForefingercircleleft DMS_DriverUpwardwave DMS_CodriverUpwardwave DMS_LeftrearUpwardwave DMS_RigntrearUpwardwave DMS_MidrearUpwardwave DMS_DriverDownwardwave DMS_CodriverDownwardwave DMS_LeftrearDownwardwave DMS_RigntrearDownwardwave DMS_MidrearDownwardwave DMS_DriverWavepalmtotheright DMS_CodriverWavepalmtotheright DMS_LeftrearWavepalmtotheright DMS_RigntrearWavepalmtotheright DMS_MidrearWavepalmtotheright DMS_DriverWavepalmtotheleft DMS_CodriverWavepalmtotheleft DMS_LeftrearWavepalmtotheleft DMS_RigntrearWavepalmtotheleft DMS_MidrearWavepalmtotheleft DMS_DriverRockgesture DMS_CodriverRockgesture DMS_LeftrearRockgesture DMS_RigntrearRockgesture DMS_MidrearRockgesture DMS_DriverScissorsgesture DMS_CodriverScissorsgesture DMS_LeftrearScissorsgesture DMS_RigntrearScissorsgesture DMS_DriverPapergesture DMS_CodriverPapergesture DMS_LeftrearPapergesture DMS_RigntrearPapergesture DMS_MidrearScissorsgesture DMS_MidrearPapergesture DMS_DriverThumbupgestures DMS_CodriverThumbupgestures DMS_LeftrearThumbupgestures DMS_RigntrearThumbupgestures DMS_MidrearThumbupgestures DMS_CodriverThumbdowngestures DMS_CodriverChild DMS_DriverThumbdowngestures DMS_LeftrearThumbdowngestures DMS_RigntrearThumbrightgestures DMS_MidrearThumbdowngestures DMS_RigntrearThumbdowngestures DMS_RigntrearThumbleftgestures DMS_MidrearThumbrightgestures DMS_CodriverThumbrightgestures DMS_CodriverThumbleftgestures DMS_MidrearThumbleftgestures DMS_DriverThumbleftgestures DMS_DriverThumbrightgestures DMS_LeftrearThumbrightgestures DMS_LeftrearThumbleftgestures DMS_SeatBeltLeftrearStatus DMS_SeatBeltCodriverStatus DMS_SeatBeltMidrearStatus DMS_LeftrearChild DMS_MidrearChild DMS_RigntrearChild DMS_SeatBeltDriverStatus DMS_SeatBeltRigntrearStatus IDC_DMS_1_Dummy9 DMS_FaceID IDC_DMS_1_Dummy6 IDC_DMS_1_Dummy5 IDC_DMS_1_Dummy3 IDC_DMS_1_Dummy2 IDC_DMS_1_Dummy4 IDC_DMS_1_Dummy10 DMS_L3DriverFatigueSt DMS_L3DriverDistractionSt DMS_InterestsRegion DMS_SysErrSt DMS_DrvrDetSts DMS_1_MsgCounter DMS_1_Checksum;
SIG_GROUP_ 616 CCU_1_E2E 1 : EEM_LvElecEgySt EEM_LdCtlSt EEM_LdCtlLv IPDS_EnablePowerSup VMM_OTAModeSt VMM_VehModeSt UMM_DriverSeatSt UMM_PowerKeepEnable UMM_PowerOffEnable UMM_PowerKeepMode UMM_ReadyForbidWarning UINM_BrakeSWNOSt UINM_BrakeSWNCSt UMM_OpIndicationWarning UINM_BrakeSWSt UMM_EmergencyWarning UMM_FrontPassengerSeatSt CCU_1_Dummy1 CCU_1_Dummy2 CCU_1_Dummy3 CCU_1_Dummy4 CCU_1_Dummy5 CCU_1_Dummy6 CCU_1_Dummy7 CCU_1_Dummy8 CCU_1_Dummy9 CCU_1_Dummy10 CCU_1_Dummy11 CCU_1_Dummy12 UMM_UsageModeSt CCU_1_CRC1 CCU_1_Counter1;
